VERSION "HNNBNNNYNNNNNNNNNNNNNNNNNNNNNNNNNNNNNNNNNN/4/%%%/4/'%**4NNN///"

NS_ :

BS_ :

BU_:  Airbag BAP_Tester ICAS1_Gateway ICAS1_KommunikationsServer LE1 LE2 Motor_BEV Schaltbetaetigung

BO_ 333 ACC_18: 32 ICAS1_Gateway
 SG_ ACC_18_CRC  : 0|8@1+ (1.000000,0.000000) [0.000000|255.000000] "" Motor_BEV
 SG_ ACC_18_BZ  : 8|4@1+ (1.000000,0.000000) [0.000000|15.000000] "" Motor_BEV
 SG_ ACC_limitierte_Anfahrdyn  : 12|1@1+ (1.000000,0.000000) [0.000000|1.000000] "" Motor_BEV
 SG_ ACC_nachtr_Stopp_Anf  : 13|1@1+ (1.000000,0.000000) [0.000000|1.000000] "" Vector__XXX
 SG_ ACC_DynErhoehung  : 14|1@1+ (1.000000,0.000000) [0.000000|1.000000] "" Motor_BEV
 SG_ ACC_Freilaufstrategie_TSK  : 15|1@1+ (1.000000,0.000000) [0.000000|1.000000] "" Motor_BEV
 SG_ ACC_zul_Regelabw_unten  : 16|6@1+ (0.024000,0.000000) [0.000000|1.512000] "Unit_MeterPerSeconSquar" Motor_BEV
 SG_ ACC_StartStopp_Info  : 22|2@1+ (1.000000,0.000000) [0.000000|3.000000] "" Vector__XXX
 SG_ ACC_Sollbeschleunigung_02  : 24|11@1+ (0.005000,-7.220000) [-7.220000|3.005000] "Unit_MeterPerSeconSquar" Motor_BEV
 SG_ ACC_zul_Regelabw_oben  : 35|5@1+ (0.062500,0.000000) [0.000000|1.937500] "Unit_MeterPerSeconSquar" Motor_BEV
 SG_ ACC_neg_Sollbeschl_Grad_02  : 40|8@1+ (0.050000,0.000000) [0.000000|12.750000] "Unit_MeterPerCubicSecon" Motor_BEV
 SG_ ACC_pos_Sollbeschl_Grad_02  : 48|8@1+ (0.050000,0.000000) [0.000000|12.750000] "Unit_MeterPerCubicSecon" Motor_BEV
 SG_ ACC_Anfahren  : 56|1@1+ (1.000000,0.000000) [0.000000|1.000000] "" Motor_BEV
 SG_ ACC_Anhalten  : 57|1@1+ (1.000000,0.000000) [0.000000|1.000000] "" Motor_BEV
 SG_ ACC_Typ  : 58|2@1+ (1.000000,0.000000) [0.000000|3.000000] "" Motor_BEV
 SG_ ACC_Status_ACC  : 60|3@1+ (1.000000,0.000000) [0.000000|7.000000] "" Motor_BEV
 SG_ ACC_Minimale_Bremsung  : 63|1@1+ (1.000000,0.000000) [0.000000|1.000000] "" Motor_BEV
 SG_ ACC_Anhalteweg  : 64|11@1+ (0.010000,0.000000) [0.000000|20.450000] "Unit_Meter" Vector__XXX
 SG_ ACC_Boost  : 75|1@1+ (1.000000,0.000000) [0.000000|1.000000] "" Vector__XXX
 SG_ ACC_Freilauf_Anf  : 76|1@1+ (1.000000,0.000000) [0.000000|1.000000] "" Vector__XXX
 SG_ ACC_Anforderung_HMS  : 77|3@1+ (1.000000,0.000000) [0.000000|7.000000] "" Vector__XXX
 SG_ ACC_Folgebeschl  : 80|8@1+ (0.030000,-4.600000) [-4.600000|2.990000] "Unit_MeterPerSeconSquar" Motor_BEV
 SG_ ACC_Freilauf_Info  : 88|2@1+ (1.000000,0.000000) [0.000000|3.000000] "" Motor_BEV
 SG_ ACC_Tempolimitassistent_Ein  : 90|1@1+ (1.000000,0.000000) [0.000000|1.000000] "" Vector__XXX
 SG_ ACC_FoD_Status  : 91|2@1+ (1.000000,0.000000) [0.000000|3.000000] "" Motor_BEV
 SG_ vESC_Verz_Anf  : 232|4@1+ (0.500000,0.000000) [0.000000|3.500000] "Unit_MeterPerSeconSquar" Vector__XXX
 SG_ RDR_v_ueber_Grund  : 236|12@1+ (0.100000,0.000000) [0.000000|409.000000] "Unit_KiloMeterPerHour" Vector__XXX
 SG_ RDR_v_ueber_Grund_Genauigkeit  : 248|6@1+ (0.100000,0.000000) [0.000000|6.000000] "Unit_KiloMeterPerHour" Vector__XXX
 SG_ RDR_v_ueber_Grund_Fahrtrichtung  : 254|2@1+ (1.000000,0.000000) [0.000000|3.000000] "" Vector__XXX

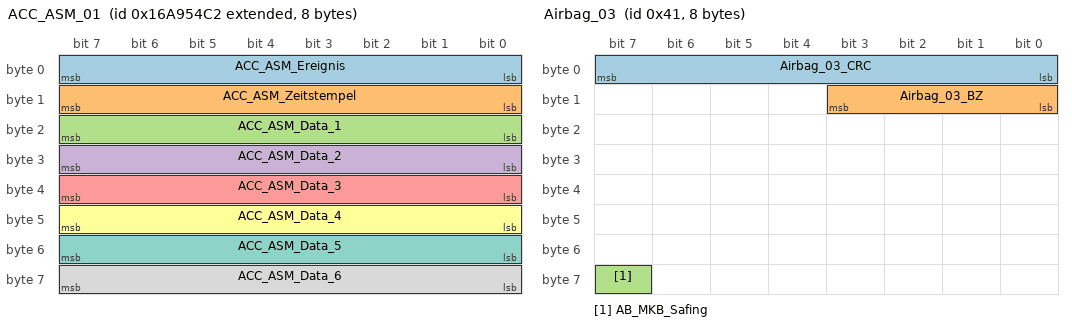
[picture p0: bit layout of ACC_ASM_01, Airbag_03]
BO_ 2527679682 ACC_ASM_01: 8 ICAS1_Gateway
 SG_ ACC_ASM_Ereignis  : 0|8@1+ (1.000000,0.000000) [1.000000|254.000000] "" Airbag
 SG_ ACC_ASM_Zeitstempel  : 8|8@1+ (0.080000,0.000000) [0.000000|20.320000] "Unit_Secon" Airbag
 SG_ ACC_ASM_Data_1  : 16|8@1+ (1.000000,0.000000) [0.000000|255.000000] "" Airbag
 SG_ ACC_ASM_Data_2  : 24|8@1+ (1.000000,0.000000) [0.000000|255.000000] "" Airbag
 SG_ ACC_ASM_Data_3  : 32|8@1+ (1.000000,0.000000) [0.000000|255.000000] "" Airbag
 SG_ ACC_ASM_Data_4  : 40|8@1+ (1.000000,0.000000) [0.000000|255.000000] "" Airbag
 SG_ ACC_ASM_Data_5  : 48|8@1+ (1.000000,0.000000) [0.000000|255.000000] "" Airbag
 SG_ ACC_ASM_Data_6  : 56|8@1+ (1.000000,0.000000) [0.000000|255.000000] "" Airbag

BO_ 64 Airbag_01: 8 Airbag
 SG_ Airbag_01_CRC  : 0|8@1+ (1.000000,0.000000) [0.000000|255.000000] "" ICAS1_Gateway LE1 LE2 Motor_BEV
 SG_ Airbag_01_BZ  : 8|4@1+ (1.000000,0.000000) [0.000000|15.000000] "" ICAS1_Gateway LE1 LE2 Motor_BEV
 SG_ AB_RGS_Anst  : 12|4@1+ (1.000000,0.000000) [0.000000|15.000000] "" ICAS1_Gateway ICAS1_KommunikationsServer
 SG_ AB_Front_Crash  : 16|1@1+ (1.000000,0.000000) [0.000000|1.000000] "" ICAS1_Gateway
 SG_ AB_Heck_Crash  : 17|1@1+ (1.000000,0.000000) [0.000000|1.000000] "" ICAS1_Gateway
 SG_ AB_SF_Crash  : 18|1@1+ (1.000000,0.000000) [0.000000|1.000000] "" ICAS1_Gateway
 SG_ AB_SB_Crash  : 19|1@1+ (1.000000,0.000000) [0.000000|1.000000] "" ICAS1_Gateway
 SG_ AB_Rollover_Crash  : 20|1@1+ (1.000000,0.000000) [0.000000|1.000000] "" ICAS1_Gateway
 SG_ AB_Crash_Int  : 21|3@1+ (1.000000,0.000000) [0.000000|7.000000] "" ICAS1_Gateway ICAS1_KommunikationsServer Motor_BEV
 SG_ AB_Lampe  : 24|1@1+ (1.000000,0.000000) [0.000000|1.000000] "" ICAS1_Gateway ICAS1_KommunikationsServer
 SG_ AB_Deaktiviert  : 25|1@1+ (1.000000,0.000000) [0.000000|1.000000] "" ICAS1_Gateway
 SG_ AB_VB_deaktiviert  : 26|1@1+ (1.000000,0.000000) [0.000000|1.000000] "" ICAS1_Gateway
 SG_ AB_Systemfehler  : 27|1@1+ (1.000000,0.000000) [0.000000|1.000000] "" ICAS1_Gateway ICAS1_KommunikationsServer
 SG_ AB_Diagnose  : 28|1@1+ (1.000000,0.000000) [0.000000|1.000000] "" ICAS1_Gateway
 SG_ AB_Stellgliedtest  : 29|1@1+ (1.000000,0.000000) [0.000000|1.000000] "" ICAS1_Gateway
 SG_ AB_Erh_Auf_VB  : 30|2@1+ (1.000000,0.000000) [0.000000|3.000000] "" ICAS1_Gateway
 SG_ AB_Gurtwarn_VF  : 32|1@1+ (1.000000,0.000000) [0.000000|1.000000] "" ICAS1_Gateway ICAS1_KommunikationsServer
 SG_ AB_Gurtwarn_VB  : 33|1@1+ (1.000000,0.000000) [0.000000|1.000000] "" ICAS1_Gateway ICAS1_KommunikationsServer
 SG_ AB_Anzeige_Fussg  : 34|2@1+ (1.000000,0.000000) [0.000000|3.000000] "" ICAS1_Gateway
 SG_ AB_Texte_AKS  : 36|2@1+ (1.000000,0.000000) [0.000000|3.000000] "" ICAS1_Gateway
 SG_ AB_PAO_Leuchte_Anf  : 38|1@1+ (1.000000,0.000000) [0.000000|1.000000] "" ICAS1_Gateway
 SG_ AB_MKB_gueltig  : 39|1@1+ (1.000000,0.000000) [0.000000|1.000000] "" ICAS1_Gateway
 SG_ AB_MKB_Anforderung  : 40|1@1+ (1.000000,0.000000) [0.000000|1.000000] "" ICAS1_Gateway
 SG_ AB_Versorgungsspannung  : 41|1@1+ (1.000000,0.000000) [0.000000|1.000000] "" ICAS1_Gateway
 SG_ AB_Deaktivierung_HV  : 42|3@1+ (1.000000,0.000000) [0.000000|7.000000] "" ICAS1_Gateway ICAS1_KommunikationsServer LE1 LE2 Motor_BEV
 SG_ AB_EDR_Trigger  : 45|2@1+ (1.000000,0.000000) [0.000000|3.000000] "" ICAS1_Gateway
 SG_ AB_Belegung_VF  : 47|2@1+ (1.000000,0.000000) [0.000000|3.000000] "" ICAS1_Gateway
 SG_ AB_Gurtschloss_FA_ext  : 49|3@1+ (1.000000,0.000000) [0.000000|7.000000] "" ICAS1_Gateway
 SG_ AB_Belegung_VF_ext  : 52|3@1+ (1.000000,0.000000) [0.000000|7.000000] "" ICAS1_Gateway
 SG_ ASM_Masterzeit  : 56|8@1+ (0.080000,0.000000) [0.000000|20.320000] "Unit_Secon" ICAS1_Gateway

BO_ 1312 Airbag_02: 8 Airbag
 SG_ Airbag_02_CRC  : 0|8@1+ (1.000000,0.000000) [0.000000|255.000000] "" ICAS1_Gateway Motor_BEV
 SG_ Airbag_02_BZ  : 8|4@1+ (1.000000,0.000000) [0.000000|15.000000] "" ICAS1_Gateway Motor_BEV
 SG_ LoGeWa_Event_Kombiwarnung  : 12|4@1+ (1.000000,0.000000) [0.000000|15.000000] "" ICAS1_Gateway
 SG_ AB_Anforderung_eCall  : 16|1@1+ (1.000000,0.000000) [0.000000|1.000000] "" ICAS1_Gateway
 SG_ AB_Anprall_Seite_Beifahrer  : 17|1@1+ (1.000000,0.000000) [0.000000|1.000000] "" ICAS1_Gateway ICAS1_KommunikationsServer
 SG_ AB_Anprall_Rollover  : 18|1@1+ (1.000000,0.000000) [0.000000|1.000000] "" ICAS1_Gateway ICAS1_KommunikationsServer
 SG_ AB_Anprall_FGS  : 19|1@1+ (1.000000,0.000000) [0.000000|1.000000] "" ICAS1_Gateway ICAS1_KommunikationsServer
 SG_ AB_Anprall_Front_Beifahrer  : 20|1@1+ (1.000000,0.000000) [0.000000|1.000000] "" ICAS1_Gateway ICAS1_KommunikationsServer
 SG_ AB_Anprall_Front_Fahrer  : 21|1@1+ (1.000000,0.000000) [0.000000|1.000000] "" ICAS1_Gateway ICAS1_KommunikationsServer
 SG_ AB_Anprall_Heck_Beifahrer  : 22|1@1+ (1.000000,0.000000) [0.000000|1.000000] "" ICAS1_Gateway ICAS1_KommunikationsServer
 SG_ AB_Anprall_Heck_Fahrer  : 23|1@1+ (1.000000,0.000000) [0.000000|1.000000] "" ICAS1_Gateway ICAS1_KommunikationsServer
 SG_ AB_Wickelklappung_Reihe2_MI  : 24|2@1+ (1.000000,0.000000) [0.000000|3.000000] "" ICAS1_Gateway
 SG_ AB_Belegung_VB  : 26|2@1+ (1.000000,0.000000) [0.000000|3.000000] "" ICAS1_Gateway
 SG_ AB_Abschaltanf_SIH_BF  : 28|1@1+ (1.000000,0.000000) [0.000000|1.000000] "" ICAS1_Gateway
 SG_ AB_Anprall_Seite_Fahrer  : 29|1@1+ (1.000000,0.000000) [0.000000|1.000000] "" ICAS1_Gateway ICAS1_KommunikationsServer
 SG_ SC_PAO_Schriftzug_Anf  : 30|2@1+ (1.000000,0.000000) [0.000000|3.000000] "" ICAS1_Gateway
 SG_ SC_PAO_ON_Anf  : 32|2@1+ (1.000000,0.000000) [0.000000|3.000000] "" ICAS1_Gateway
 SG_ SC_PAO_OFF_Anf  : 34|2@1+ (1.000000,0.000000) [0.000000|3.000000] "" ICAS1_Gateway
 SG_ AB_Crashschwere  : 36|3@1+ (1.000000,0.000000) [0.000000|7.000000] "" ICAS1_Gateway ICAS1_KommunikationsServer
 SG_ AB_Anforderung_USM  : 39|1@1+ (1.000000,0.000000) [0.000000|1.000000] "" ICAS1_Gateway
 SG_ AB_Gurtschloss_FA  : 40|2@1+ (1.000000,0.000000) [0.000000|3.000000] "" ICAS1_Gateway ICAS1_KommunikationsServer Motor_BEV
 SG_ AB_Gurtschloss_BF  : 42|2@1+ (1.000000,0.000000) [0.000000|3.000000] "" ICAS1_Gateway ICAS1_KommunikationsServer
 SG_ AB_Gurtschloss_Reihe2_FA  : 44|2@1+ (1.000000,0.000000) [0.000000|3.000000] "" ICAS1_Gateway ICAS1_KommunikationsServer
 SG_ AB_Gurtschloss_Reihe2_MI  : 46|2@1+ (1.000000,0.000000) [0.000000|3.000000] "" ICAS1_Gateway ICAS1_KommunikationsServer
 SG_ AB_Gurtschloss_Reihe2_BF  : 48|2@1+ (1.000000,0.000000) [0.000000|3.000000] "" ICAS1_Gateway ICAS1_KommunikationsServer
 SG_ AB_Gurtschloss_Reihe3_FA  : 50|2@1+ (1.000000,0.000000) [0.000000|3.000000] "" ICAS1_Gateway ICAS1_KommunikationsServer
 SG_ AB_Gurtschloss_Reihe3_MI  : 52|2@1+ (1.000000,0.000000) [0.000000|3.000000] "" ICAS1_Gateway ICAS1_KommunikationsServer
 SG_ AB_Gurtschloss_Reihe3_BF  : 54|2@1+ (1.000000,0.000000) [0.000000|3.000000] "" ICAS1_Gateway ICAS1_KommunikationsServer
 SG_ AB_Sitzpos_Sens_FA  : 56|2@1+ (1.000000,0.000000) [0.000000|3.000000] "" ICAS1_Gateway
 SG_ AB_Sitzpos_Sens_BF  : 58|2@1+ (1.000000,0.000000) [0.000000|3.000000] "" ICAS1_Gateway
 SG_ AB_Wickelklappung_Reihe2_BF  : 60|2@1+ (1.000000,0.000000) [0.000000|3.000000] "" ICAS1_Gateway
 SG_ AB_Wickelklappung_Reihe2_FA  : 62|2@1+ (1.000000,0.000000) [0.000000|3.000000] "" ICAS1_Gateway

BO_ 65 Airbag_03: 8 Airbag
 SG_ Airbag_03_CRC  : 0|8@1+ (1.000000,0.000000) [0.000000|255.000000] "" ICAS1_Gateway
 SG_ Airbag_03_BZ  : 8|4@1+ (1.000000,0.000000) [0.000000|15.000000] "" ICAS1_Gateway
 SG_ AB_MKB_Safing  : 63|1@1+ (1.000000,0.000000) [0.000000|1.000000] "" ICAS1_Gateway

BO_ 1349 Airbag_04: 8 Airbag
 SG_ AB_Gurtwarn_Reihe4_FA  : 14|2@1+ (1.000000,0.000000) [0.000000|3.000000] "" ICAS1_Gateway ICAS1_KommunikationsServer
 SG_ AB_Gurtwarn_Reihe4_BF  : 16|2@1+ (1.000000,0.000000) [0.000000|3.000000] "" ICAS1_Gateway ICAS1_KommunikationsServer
 SG_ AB_Gurtwarn_Reihe4_MI  : 18|2@1+ (1.000000,0.000000) [0.000000|3.000000] "" ICAS1_Gateway ICAS1_KommunikationsServer
 SG_ AB_Gurtwarn_Reihe2_FA  : 20|2@1+ (1.000000,0.000000) [0.000000|3.000000] "" ICAS1_Gateway ICAS1_KommunikationsServer
 SG_ AB_Gurtwarn_Reihe2_BF  : 22|2@1+ (1.000000,0.000000) [0.000000|3.000000] "" ICAS1_Gateway ICAS1_KommunikationsServer
 SG_ AbstWarn_MV_FAS_Fkt_Status  : 24|2@1+ (1.000000,0.000000) [0.000000|3.000000] "" ICAS1_Gateway
 SG_ WarnBrems_Charisma_Status  : 26|2@1+ (1.000000,0.000000) [0.000000|3.000000] "" ICAS1_Gateway
 SG_ WarnBrems_Charisma_FahrPr  : 28|4@1+ (1.000000,0.000000) [0.000000|15.000000] "" ICAS1_Gateway
 SG_ AB_Gurtwarn_Reihe2_MI  : 32|2@1+ (1.000000,0.000000) [0.000000|3.000000] "" ICAS1_Gateway ICAS1_KommunikationsServer
 SG_ AB_Gurtwarn_Reihe3_FA  : 34|2@1+ (1.000000,0.000000) [0.000000|3.000000] "" ICAS1_Gateway ICAS1_KommunikationsServer
 SG_ AB_Gurtwarn_Reihe3_MI  : 36|2@1+ (1.000000,0.000000) [0.000000|3.000000] "" ICAS1_Gateway ICAS1_KommunikationsServer
 SG_ AB_Gurtwarn_Reihe3_BF  : 38|2@1+ (1.000000,0.000000) [0.000000|3.000000] "" ICAS1_Gateway ICAS1_KommunikationsServer
 SG_ LGI_FAS_Fkt_Status  : 40|2@1+ (1.000000,0.000000) [0.000000|3.000000] "" ICAS1_Gateway
 SG_ PreCrash_FAS_Fkt_Status  : 42|3@1+ (1.000000,0.000000) [0.000000|7.000000] "" ICAS1_Gateway
 SG_ AB_SBR_hinten_verbau  : 48|2@1+ (1.000000,0.000000) [0.000000|3.000000] "" ICAS1_Gateway ICAS1_KommunikationsServer
 SG_ AWV_Einstellung_System_ASG  : 51|1@1+ (1.000000,0.000000) [0.000000|1.000000] "" ICAS1_Gateway
 SG_ AWV_Einstellung_Warnung_ASG  : 52|3@1+ (1.000000,0.000000) [0.000000|7.000000] "" ICAS1_Gateway
 SG_ SC_PreSense_Modus_Warnung_NV  : 55|3@1+ (1.000000,0.000000) [0.000000|7.000000] "" ICAS1_Gateway
 SG_ SC_PreSense_Modus_Warnung_MV  : 58|3@1+ (1.000000,0.000000) [0.000000|7.000000] "" ICAS1_Gateway
 SG_ SC_PreSense_Modus_System_MV  : 61|1@1+ (1.000000,0.000000) [0.000000|1.000000] "" ICAS1_Gateway
 SG_ SC_PreSense_Modus_System_NV  : 62|1@1+ (1.000000,0.000000) [0.000000|1.000000] "" ICAS1_Gateway
 SG_ SC_PreSense_Modus_System_KAS  : 63|1@1+ (1.000000,0.000000) [0.000000|1.000000] "" ICAS1_Gateway

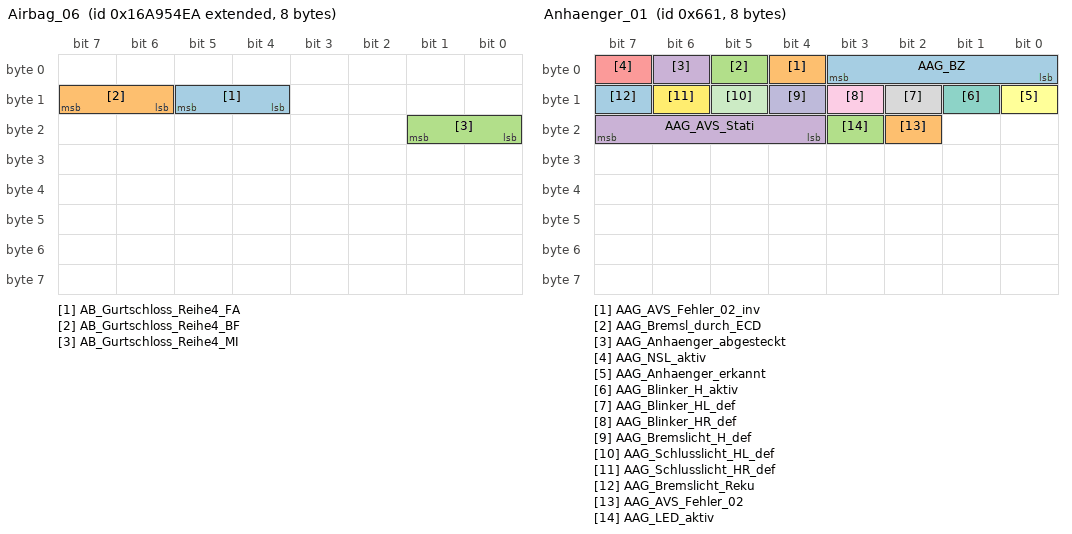
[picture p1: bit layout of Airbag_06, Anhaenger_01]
BO_ 2527679722 Airbag_06: 8 Airbag
 SG_ AB_Gurtschloss_Reihe4_FA  : 12|2@1+ (1.000000,0.000000) [0.000000|3.000000] "" ICAS1_Gateway ICAS1_KommunikationsServer
 SG_ AB_Gurtschloss_Reihe4_BF  : 14|2@1+ (1.000000,0.000000) [0.000000|3.000000] "" ICAS1_Gateway ICAS1_KommunikationsServer
 SG_ AB_Gurtschloss_Reihe4_MI  : 16|2@1+ (1.000000,0.000000) [0.000000|3.000000] "" ICAS1_Gateway ICAS1_KommunikationsServer

BO_ 1633 Anhaenger_01: 8 ICAS1_Gateway
 SG_ AAG_BZ  : 0|4@1+ (1.000000,0.000000) [0.000000|15.000000] "" Vector__XXX
 SG_ AAG_AVS_Fehler_02_inv  : 4|1@1+ (1.000000,0.000000) [0.000000|1.000000] "" Vector__XXX
 SG_ AAG_Bremsl_durch_ECD  : 5|1@1+ (1.000000,0.000000) [0.000000|1.000000] "" Motor_BEV
 SG_ AAG_Anhaenger_abgesteckt  : 6|1@1+ (1.000000,0.000000) [0.000000|1.000000] "" Motor_BEV
 SG_ AAG_NSL_aktiv  : 7|1@1+ (1.000000,0.000000) [0.000000|1.000000] "" Vector__XXX
 SG_ AAG_Anhaenger_erkannt  : 8|1@1+ (1.000000,0.000000) [0.000000|1.000000] "" Motor_BEV
 SG_ AAG_Blinker_H_aktiv  : 9|1@1+ (1.000000,0.000000) [0.000000|1.000000] "" Vector__XXX
 SG_ AAG_Blinker_HL_def  : 10|1@1+ (1.000000,0.000000) [0.000000|1.000000] "" Vector__XXX
 SG_ AAG_Blinker_HR_def  : 11|1@1+ (1.000000,0.000000) [0.000000|1.000000] "" Vector__XXX
 SG_ AAG_Bremslicht_H_def  : 12|1@1+ (1.000000,0.000000) [0.000000|1.000000] "" Motor_BEV
 SG_ AAG_Schlusslicht_HL_def  : 13|1@1+ (1.000000,0.000000) [0.000000|1.000000] "" Vector__XXX
 SG_ AAG_Schlusslicht_HR_def  : 14|1@1+ (1.000000,0.000000) [0.000000|1.000000] "" Vector__XXX
 SG_ AAG_Bremslicht_Reku  : 15|1@1+ (1.000000,0.000000) [0.000000|1.000000] "" Vector__XXX
 SG_ AAG_AVS_Fehler_02  : 18|1@1+ (1.000000,0.000000) [0.000000|1.000000] "" Vector__XXX
 SG_ AAG_LED_aktiv  : 19|1@1+ (1.000000,0.000000) [0.000000|1.000000] "" Vector__XXX
 SG_ AAG_AVS_Stati  : 20|4@1+ (1.000000,0.000000) [0.000000|15.000000] "" Vector__XXX

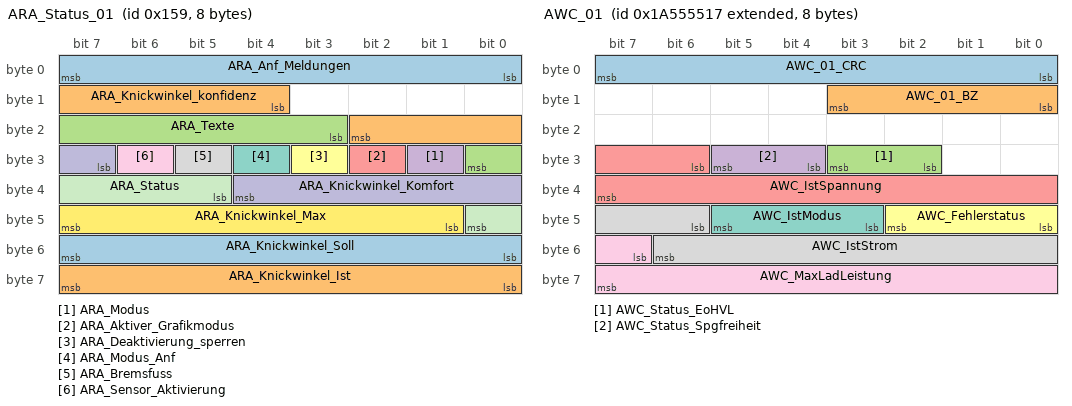
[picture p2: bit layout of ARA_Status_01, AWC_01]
BO_ 345 ARA_Status_01: 8 ICAS1_Gateway
 SG_ ARA_Anf_Meldungen  : 0|8@1+ (1.000000,0.000000) [0.000000|255.000000] "" Vector__XXX
 SG_ ARA_Knickwinkel_konfidenz  : 12|7@1+ (1.000000,0.000000) [0.000000|120.000000] "Unit_DegreOfArc" Vector__XXX
 SG_ ARA_Texte  : 19|6@1+ (1.000000,0.000000) [0.000000|63.000000] "" Vector__XXX
 SG_ ARA_Modus  : 25|1@1+ (1.000000,0.000000) [0.000000|1.000000] "" Vector__XXX
 SG_ ARA_Aktiver_Grafikmodus  : 26|1@1+ (1.000000,0.000000) [0.000000|1.000000] "" Vector__XXX
 SG_ ARA_Deaktivierung_sperren  : 27|1@1+ (1.000000,0.000000) [0.000000|1.000000] "" Vector__XXX
 SG_ ARA_Modus_Anf  : 28|1@1+ (1.000000,0.000000) [0.000000|1.000000] "" Vector__XXX
 SG_ ARA_Bremsfuss  : 29|1@1+ (1.000000,0.000000) [0.000000|1.000000] "" Vector__XXX
 SG_ ARA_Sensor_Aktivierung  : 30|1@1+ (1.000000,0.000000) [0.000000|1.000000] "" Vector__XXX
 SG_ ARA_Knickwinkel_Komfort  : 31|6@1+ (1.000000,0.000000) [0.000000|60.000000] "Unit_DegreOfArc" Vector__XXX
 SG_ ARA_Status  : 37|4@1+ (1.000000,0.000000) [0.000000|15.000000] "" Motor_BEV
 SG_ ARA_Knickwinkel_Max  : 41|7@1+ (1.000000,0.000000) [0.000000|120.000000] "Unit_DegreOfArc" Vector__XXX
 SG_ ARA_Knickwinkel_Soll  : 48|8@1+ (1.000000,-125.000000) [-125.000000|126.000000] "Unit_DegreOfArc" Vector__XXX
 SG_ ARA_Knickwinkel_Ist  : 56|8@1+ (1.000000,-125.000000) [-125.000000|126.000000] "Unit_DegreOfArc" Vector__XXX

BO_ 2589283607 AWC_01: 8 ICAS1_Gateway
 SG_ AWC_01_CRC  : 0|8@1+ (1.000000,0.000000) [0.000000|255.000000] "" Vector__XXX
 SG_ AWC_01_BZ  : 8|4@1+ (1.000000,0.000000) [0.000000|15.000000] "" Vector__XXX
 SG_ AWC_Status_EoHVL  : 26|2@1+ (1.000000,0.000000) [0.000000|3.000000] "" Motor_BEV
 SG_ AWC_Status_Spgfreiheit  : 28|2@1+ (1.000000,0.000000) [0.000000|3.000000] "" Vector__XXX
 SG_ AWC_IstSpannung  : 30|10@1+ (1.000000,0.000000) [0.000000|1021.000000] "Unit_Volt" Vector__XXX
 SG_ AWC_Fehlerstatus  : 40|3@1+ (1.000000,0.000000) [0.000000|7.000000] "" Vector__XXX
 SG_ AWC_IstModus  : 43|3@1+ (1.000000,0.000000) [0.000000|7.000000] "" Vector__XXX
 SG_ AWC_IstStrom  : 46|9@1+ (0.100000,0.000000) [0.000000|50.900000] "Unit_Amper" Vector__XXX
 SG_ AWC_MaxLadLeistung  : 55|9@1+ (25.000000,0.000000) [0.000000|12725.000000] "Unit_Watt" Vector__XXX

BO_ 219 AWV_03: 48 ICAS1_Gateway
 SG_ AWV_03_CRC  : 0|8@1+ (1.000000,0.000000) [0.000000|255.000000] "" Airbag
 SG_ AWV_03_BZ  : 8|4@1+ (1.000000,0.000000) [0.000000|15.000000] "" Airbag
 SG_ PCF_Freigabe  : 12|1@1+ (1.000000,0.000000) [0.000000|1.000000] "" Airbag
 SG_ SDF_PSF_Objektstatus  : 13|3@1+ (1.000000,0.000000) [0.000000|7.000000] "" Airbag
 SG_ SDF_PSF_CU_Status  : 16|1@1+ (1.000000,0.000000) [0.000000|1.000000] "" Airbag
 SG_ SDF_PSF_CW  : 17|7@1+ (1.000000,0.000000) [0.000000|100.000000] "" Airbag
 SG_ SDF_PSF_Fahrer_aktiv  : 24|1@1+ (1.000000,0.000000) [0.000000|1.000000] "" Airbag
 SG_ SDF_PSF_Guete  : 25|2@1+ (1.000000,0.000000) [0.000000|3.000000] "" Airbag
 SG_ SDF_PSF_Kollisionsueberdeckung  : 27|5@1+ (0.100000,0.000000) [0.100000|2.800000] "Unit_Meter" Airbag
 SG_ SDF_PSF_Time_To_Collision  : 32|8@1+ (0.010000,0.000000) [0.000000|2.500000] "Unit_Secon" Vector__XXX
 SG_ SDF_PSF_v_rel  : 40|8@1+ (0.400000,0.000000) [0.400000|101.200000] "Unit_MeterPerSecon" Airbag
 SG_ AWV_Eingriff_Sendeart  : 64|1@1+ (1.000000,0.000000) [0.000000|1.000000] "" Airbag
 SG_ AWV_Verz_Freigabe  : 65|1@1+ (1.000000,0.000000) [0.000000|1.000000] "" Airbag
 SG_ AWV_Verz_Anf  : 66|10@1+ (0.024000,-20.016000) [-20.016000|4.512000] "Unit_MeterPerSeconSquar" Airbag
 SG_ AWV_Anf_Prefill  : 76|1@1+ (1.000000,0.000000) [0.000000|1.000000] "" Airbag
 SG_ AWV_Ruckprofil  : 77|3@1+ (1.000000,0.000000) [0.000000|7.000000] "" Vector__XXX
 SG_ AWV_Time_to_collision  : 80|8@1+ (0.010000,0.000000) [0.000000|2.500000] "Unit_Secon" Airbag
 SG_ AWV_HBA_Param  : 88|2@1+ (1.000000,0.000000) [0.000000|3.000000] "" Vector__XXX
 SG_ AWV_Verz_Anf_ASIL  : 90|3@1+ (1.000000,0.000000) [0.000000|7.000000] "" Vector__XXX
 SG_ AWV_Time_to_brake  : 93|7@1+ (10.000000,0.000000) [0.000000|1240.000000] "Unit_MilliSecon" Vector__XXX
 SG_ AWV_Zielobjekttyp  : 100|4@1+ (1.000000,0.000000) [0.000000|15.000000] "" Airbag
 SG_ AWV_QFK_KruemmSoll  : 104|15@1+ (0.000007,0.000000) [0.000000|0.219539] "Unit_MeterInver" Vector__XXX
 SG_ AWV_QFK_KruemmSoll_VZ  : 119|1@1+ (1.000000,0.000000) [0.000000|1.000000] "" Vector__XXX
 SG_ AWV_QFK_Spuerb  : 120|8@1+ (0.400000,0.000000) [0.000000|100.000000] "Unit_PerCent" Vector__XXX
 SG_ AWV_QFK_AnfStat  : 128|4@1+ (1.000000,0.000000) [0.000000|15.000000] "" Airbag
 SG_ AWV_QFK_Signal1  : 132|10@1+ (1.000000,0.000000) [0.000000|1023.000000] "" Vector__XXX
 SG_ AWV_QFK_Art1  : 142|3@1+ (1.000000,0.000000) [0.000000|7.000000] "" Vector__XXX
 SG_ AWV_QFK_Art2  : 145|3@1+ (1.000000,0.000000) [0.000000|7.000000] "" Vector__XXX
 SG_ AWV_QFK_Signal2  : 148|10@1+ (1.000000,0.000000) [0.000000|1023.000000] "" Vector__XXX

BO_ 2536767264 BAP_Debug_Cmd: 8 BAP_Tester
 SG_ BAP_Debug_Cmd  : 0|16@1+ (1.000000,0.000000) [0.000000|65535.000000] "" Motor_BEV

BO_ 2536767280 BAP_Debug_Data: 8 Motor_BEV
 SG_ BAP_Debug_Data  : 0|64@1+ (1.000000,0.000000) [0.000000|18446744073709551616.000000] "" BAP_Tester

BO_ 2536717313 BAP_EfficiencyAssist_ASG_02: 8 ICAS1_Gateway
 SG_ BAP_EfficAssist_ASG_02_Header  : 0|64@1+ (1.000000,0.000000) [0.000000|18446744073709551616.000000] "" Motor_BEV

BO_ 2536717314 BAP_EfficiencyAssist_ASG_03: 8 ICAS1_Gateway
 SG_ BAP_EfficAssist_ASG_03_Header  : 0|8@1+ (1.000000,0.000000) [0.000000|255.000000] "" Motor_BEV

BO_ 2536717328 BAP_EfficiencyAssist_FSG_01: 8 Motor_BEV
 SG_ BAP_EfficAssist_FSG_01_Header  : 0|8@1+ (1.000000,0.000000) [0.000000|255.000000] "" ICAS1_Gateway

BO_ 2536709120 BAP_Hybrid_ASG_01: 8 ICAS1_Gateway
 SG_ BAP_Hybrid_ASG_01_Header  : 0|8@1+ (1.000000,0.000000) [0.000000|255.000000] "" Motor_BEV

BO_ 2536709136 BAP_Hybrid_FSG_01: 8 Motor_BEV
 SG_ BAP_Hybrid_FSG_01_Header  : 0|8@1+ (1.000000,0.000000) [0.000000|255.000000] "" ICAS1_Gateway

BO_ 869 BEM_05: 8 ICAS1_Gateway
 SG_ BEM_UBDM  : 0|8@1+ (0.050000,5.000000) [5.050000|17.700000] "Unit_Volt" Vector__XXX
 SG_ NVEM_Ladefreigabe  : 8|2@1+ (1.000000,0.000000) [0.000000|3.000000] "" Vector__XXX
 SG_ NVEM_FMAus_Info  : 10|2@1+ (1.000000,0.000000) [0.000000|3.000000] "" Vector__XXX
 SG_ NVEM_PTC_Sollstufe  : 12|2@1+ (1.000000,0.000000) [0.000000|3.000000] "" Vector__XXX
 SG_ NVEM_P_Generator_Status  : 15|1@1+ (1.000000,0.000000) [0.000000|1.000000] "" Vector__XXX
 SG_ BEM_P_Generator  : 16|8@1+ (50.000000,0.000000) [0.000000|12700.000000] "Unit_Watt" Vector__XXX
 SG_ BEM_n_LLA  : 24|2@1+ (1.000000,0.000000) [0.000000|3.000000] "" Vector__XXX
 SG_ BEM_01_Abschaltstufen  : 26|3@1+ (1.000000,0.000000) [0.000000|7.000000] "" Vector__XXX
 SG_ BEM_Anf_KL  : 29|1@1+ (1.000000,0.000000) [0.000000|1.000000] "" Vector__XXX
 SG_ BEM_StartStopp_Info  : 30|2@1+ (1.000000,0.000000) [0.000000|3.000000] "" Vector__XXX
 SG_ BEM_DFM  : 32|5@1+ (3.225000,0.025000) [0.025000|100.000000] "" Vector__XXX
 SG_ BEM_EMLIN_ungueltig  : 37|1@1+ (1.000000,0.000000) [0.000000|1.000000] "" Vector__XXX
 SG_ BEM_Batt_Ab  : 38|1@1+ (1.000000,0.000000) [0.000000|1.000000] "" Motor_BEV
 SG_ NVEM_FMAus_I_Verbrauch  : 39|5@1+ (5.000000,0.000000) [0.000000|145.000000] "Unit_Amper" Vector__XXX
 SG_ NVEM_Freilauf_Info  : 44|2@1+ (1.000000,0.000000) [0.000000|3.000000] "" Vector__XXX
 SG_ BEM_NV_NachladAnf  : 46|2@1+ (1.000000,0.000000) [0.000000|3.000000] "" Vector__XXX
 SG_ BEM_Segel_Info  : 48|2@1+ (1.000000,0.000000) [0.000000|3.000000] "" Vector__XXX
 SG_ BEM_HYB_DC_uSollLV  : 50|6@1+ (0.100000,10.600000) [10.600000|16.000000] "Unit_Volt" Vector__XXX
 SG_ BEM_HYB_DC_uMinLV  : 56|8@1+ (0.100000,0.000000) [0.000000|25.300000] "Unit_Volt" Vector__XXX

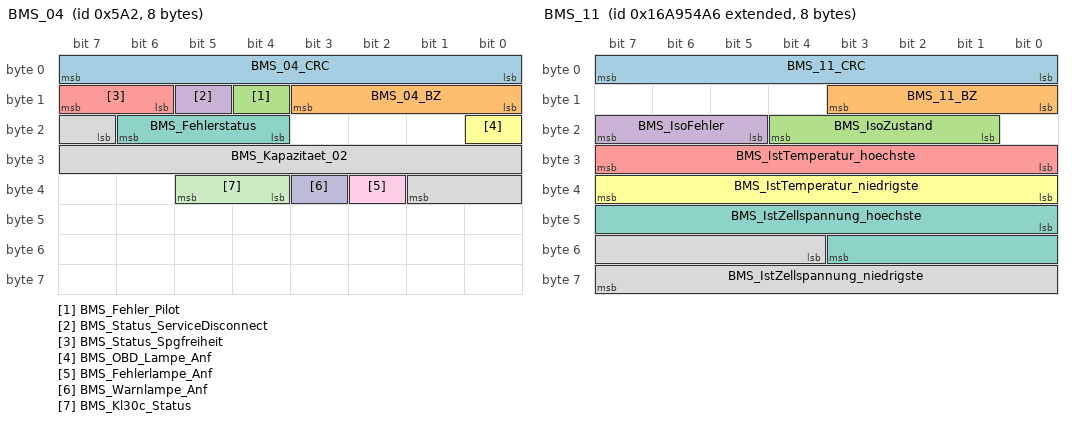
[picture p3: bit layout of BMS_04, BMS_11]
BO_ 1442 BMS_04: 8 ICAS1_Gateway
 SG_ BMS_04_CRC  : 0|8@1+ (1.000000,0.000000) [0.000000|255.000000] "" Vector__XXX
 SG_ BMS_04_BZ  : 8|4@1+ (1.000000,0.000000) [0.000000|15.000000] "" Vector__XXX
 SG_ BMS_Fehler_Pilot  : 12|1@1+ (1.000000,0.000000) [0.000000|1.000000] "" Vector__XXX
 SG_ BMS_Status_ServiceDisconnect  : 13|1@1+ (1.000000,0.000000) [0.000000|1.000000] "" Vector__XXX
 SG_ BMS_Status_Spgfreiheit  : 14|2@1+ (1.000000,0.000000) [0.000000|3.000000] "" Motor_BEV
 SG_ BMS_OBD_Lampe_Anf  : 16|1@1+ (1.000000,0.000000) [0.000000|1.000000] "" Motor_BEV
 SG_ BMS_Fehlerstatus  : 20|3@1+ (1.000000,0.000000) [0.000000|7.000000] "" Vector__XXX
 SG_ BMS_Kapazitaet_02  : 23|11@1+ (0.200000,0.000000) [0.000000|409.200000] "Unit_AmperHour" Vector__XXX
 SG_ BMS_Fehlerlampe_Anf  : 34|1@1+ (1.000000,0.000000) [0.000000|1.000000] "" Motor_BEV
 SG_ BMS_Warnlampe_Anf  : 35|1@1+ (1.000000,0.000000) [0.000000|1.000000] "" Motor_BEV
 SG_ BMS_Kl30c_Status  : 36|2@1+ (1.000000,0.000000) [0.000000|3.000000] "" Motor_BEV

BO_ 2527679654 BMS_11: 8 ICAS1_Gateway
 SG_ BMS_11_CRC  : 0|8@1+ (1.000000,0.000000) [0.000000|255.000000] "" Motor_BEV
 SG_ BMS_11_BZ  : 8|4@1+ (1.000000,0.000000) [0.000000|15.000000] "" Motor_BEV
 SG_ BMS_IsoZustand  : 17|4@1+ (1.000000,0.000000) [0.000000|15.000000] "" Motor_BEV
 SG_ BMS_IsoFehler  : 21|3@1+ (1.000000,0.000000) [0.000000|7.000000] "" Motor_BEV
 SG_ BMS_IstTemperatur_hoechste  : 24|8@1+ (0.500000,-40.000000) [-40.000000|86.000000] "Unit_DegreCelsi" Vector__XXX
 SG_ BMS_IstTemperatur_niedrigste  : 32|8@1+ (0.500000,-40.000000) [-40.000000|86.000000] "Unit_DegreCelsi" Vector__XXX
 SG_ BMS_IstZellspannung_hoechste  : 40|12@1+ (1.000000,1000.000000) [1000.000000|5091.000000] "Unit_MilliVolt" Vector__XXX
 SG_ BMS_IstZellspannung_niedrigste  : 52|12@1+ (1.000000,1000.000000) [1000.000000|5091.000000] "Unit_MilliVolt" Vector__XXX

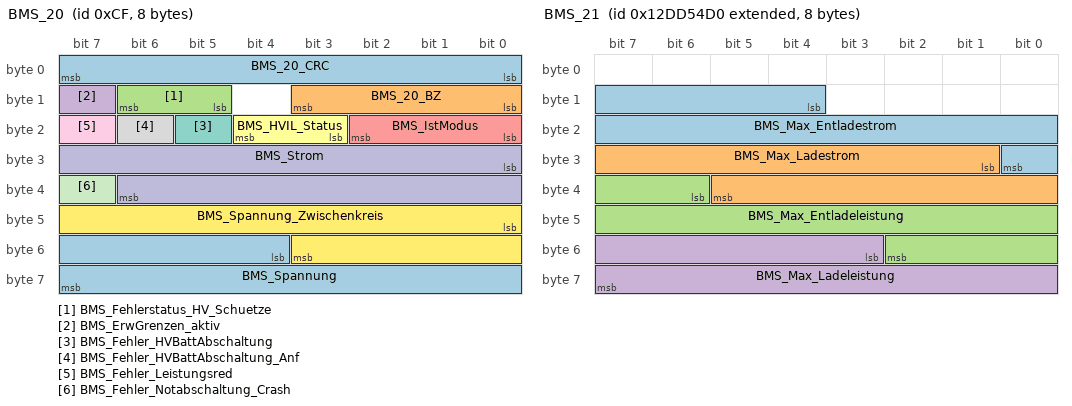
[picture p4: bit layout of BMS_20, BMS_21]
BO_ 207 BMS_20: 8 ICAS1_Gateway
 SG_ BMS_20_CRC  : 0|8@1+ (1.000000,0.000000) [0.000000|255.000000] "" Motor_BEV
 SG_ BMS_20_BZ  : 8|4@1+ (1.000000,0.000000) [0.000000|15.000000] "" Motor_BEV
 SG_ BMS_Fehlerstatus_HV_Schuetze  : 13|2@1+ (1.000000,0.000000) [0.000000|3.000000] "" Motor_BEV
 SG_ BMS_ErwGrenzen_aktiv  : 15|1@1+ (1.000000,0.000000) [0.000000|1.000000] "" Motor_BEV
 SG_ BMS_IstModus  : 16|3@1+ (1.000000,0.000000) [0.000000|7.000000] "" LE1 LE2 Motor_BEV
 SG_ BMS_HVIL_Status  : 19|2@1+ (1.000000,0.000000) [0.000000|3.000000] "" Motor_BEV
 SG_ BMS_Fehler_HVBattAbschaltung  : 21|1@1+ (1.000000,0.000000) [0.000000|1.000000] "" Motor_BEV
 SG_ BMS_Fehler_HVBattAbschaltung_Anf  : 22|1@1+ (1.000000,0.000000) [0.000000|1.000000] "" Motor_BEV
 SG_ BMS_Fehler_Leistungsred  : 23|1@1+ (1.000000,0.000000) [0.000000|1.000000] "" Motor_BEV
 SG_ BMS_Strom  : 24|15@1+ (0.100000,-1630.000000) [-1630.000000|1630.000000] "Unit_Amper" Motor_BEV
 SG_ BMS_Fehler_Notabschaltung_Crash  : 39|1@1+ (1.000000,0.000000) [0.000000|1.000000] "" Vector__XXX
 SG_ BMS_Spannung_Zwischenkreis  : 40|12@1+ (0.500000,-1000.000000) [-1000.000000|1000.000000] "Unit_Volt" Motor_BEV
 SG_ BMS_Spannung  : 52|12@1+ (0.250000,0.000000) [0.000000|1000.000000] "Unit_Volt" Motor_BEV

BO_ 2463978704 BMS_21: 8 ICAS1_Gateway
 SG_ BMS_Max_Entladestrom  : 12|13@1+ (0.200000,0.000000) [0.000000|1630.000000] "Unit_Amper" Motor_BEV
 SG_ BMS_Max_Ladestrom  : 25|13@1+ (0.200000,0.000000) [0.000000|1630.000000] "Unit_Amper" Motor_BEV
 SG_ BMS_Max_Entladeleistung  : 38|13@1+ (100.000000,0.000000) [0.000000|818000.000000] "Unit_Watt" Motor_BEV
 SG_ BMS_Max_Ladeleistung  : 51|13@1+ (100.000000,0.000000) [0.000000|818000.000000] "Unit_Watt" Motor_BEV

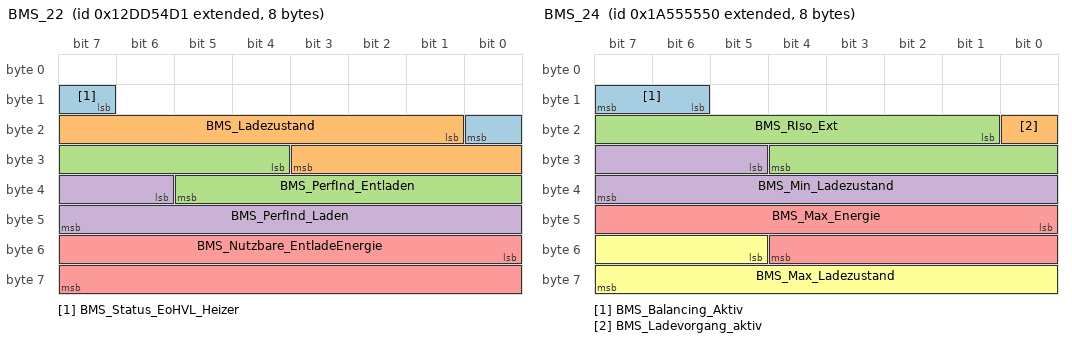
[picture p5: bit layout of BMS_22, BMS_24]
BO_ 2463978705 BMS_22: 8 ICAS1_Gateway
 SG_ BMS_Status_EoHVL_Heizer  : 15|2@1+ (1.000000,0.000000) [0.000000|3.000000] "" Motor_BEV
 SG_ BMS_Ladezustand  : 17|11@1+ (0.050000,0.000000) [0.000000|100.000000] "Unit_PerCent" Motor_BEV
 SG_ BMS_PerfInd_Entladen  : 28|10@1+ (0.200000,0.000000) [0.000000|200.000000] "Unit_PerCent" Motor_BEV
 SG_ BMS_PerfInd_Laden  : 38|10@1+ (0.200000,0.000000) [0.000000|200.000000] "Unit_PerCent" Motor_BEV
 SG_ BMS_Nutzbare_EntladeEnergie  : 48|16@1+ (5.000000,0.000000) [0.000000|327400.000000] "Unit_WattHour" Motor_BEV

BO_ 2589283664 BMS_24: 8 ICAS1_Gateway
 SG_ BMS_Balancing_Aktiv  : 14|2@1+ (1.000000,0.000000) [0.000000|3.000000] "" Vector__XXX
 SG_ BMS_Ladevorgang_aktiv  : 16|1@1+ (1.000000,0.000000) [0.000000|1.000000] "" Vector__XXX
 SG_ BMS_RIso_Ext  : 17|12@1+ (5.000000,0.000000) [0.000000|20465.000000] "Unit_KiloOhm" Motor_BEV
 SG_ BMS_Min_Ladezustand  : 29|11@1+ (0.050000,0.000000) [0.000000|100.000000] "Unit_PerCent" Motor_BEV
 SG_ BMS_Max_Energie  : 40|13@1+ (40.000000,0.000000) [0.000000|327400.000000] "Unit_WattHour" Motor_BEV
 SG_ BMS_Max_Ladezustand  : 53|11@1+ (0.050000,0.000000) [0.000000|100.000000] "Unit_PerCent" Motor_BEV

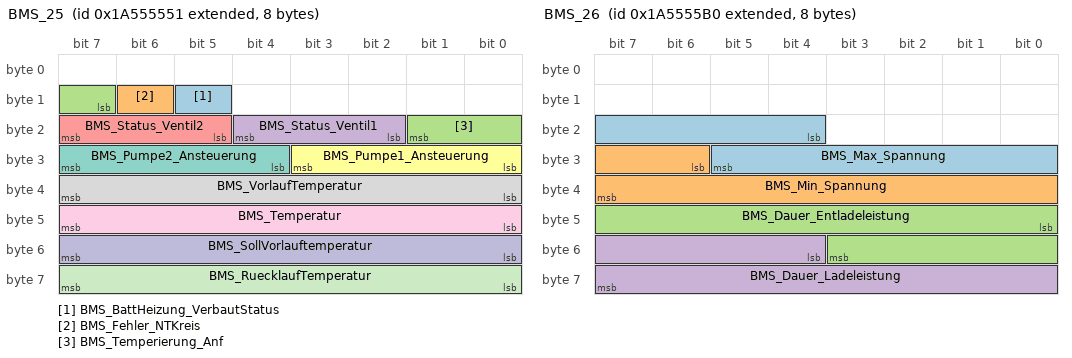
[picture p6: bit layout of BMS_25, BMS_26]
BO_ 2589283665 BMS_25: 8 ICAS1_Gateway
 SG_ BMS_BattHeizung_VerbautStatus  : 13|1@1+ (1.000000,0.000000) [0.000000|1.000000] "" Motor_BEV
 SG_ BMS_Fehler_NTKreis  : 14|1@1+ (1.000000,0.000000) [0.000000|1.000000] "" Vector__XXX
 SG_ BMS_Temperierung_Anf  : 15|3@1+ (1.000000,0.000000) [0.000000|7.000000] "" Motor_BEV
 SG_ BMS_Status_Ventil1  : 18|3@1+ (1.000000,0.000000) [0.000000|7.000000] "" Motor_BEV
 SG_ BMS_Status_Ventil2  : 21|3@1+ (1.000000,0.000000) [0.000000|7.000000] "" Motor_BEV
 SG_ BMS_Pumpe1_Ansteuerung  : 24|4@1+ (10.000000,0.000000) [0.000000|100.000000] "Unit_PerCent" Motor_BEV
 SG_ BMS_Pumpe2_Ansteuerung  : 28|4@1+ (10.000000,0.000000) [0.000000|100.000000] "Unit_PerCent" Motor_BEV
 SG_ BMS_VorlaufTemperatur  : 32|8@1+ (0.500000,-40.000000) [-40.000000|86.000000] "Unit_DegreCelsi" Motor_BEV
 SG_ BMS_Temperatur  : 40|8@1+ (0.500000,-40.000000) [-40.000000|86.500000] "Unit_DegreCelsi" Motor_BEV
 SG_ BMS_SollVorlauftemperatur  : 48|8@1+ (0.500000,-40.000000) [-40.000000|86.500000] "Unit_DegreCelsi" Motor_BEV
 SG_ BMS_RuecklaufTemperatur  : 56|8@1+ (0.500000,-40.000000) [-40.000000|86.000000] "Unit_DegreCelsi" Motor_BEV

BO_ 2589283760 BMS_26: 8 ICAS1_Gateway
 SG_ BMS_Max_Spannung  : 20|10@1+ (1.000000,0.000000) [0.000000|1000.000000] "Unit_Volt" Motor_BEV
 SG_ BMS_Min_Spannung  : 30|10@1+ (1.000000,0.000000) [0.000000|1000.000000] "Unit_Volt" Motor_BEV
 SG_ BMS_Dauer_Entladeleistung  : 40|12@1+ (200.000000,0.000000) [0.000000|818000.000000] "Unit_Watt" Motor_BEV
 SG_ BMS_Dauer_Ladeleistung  : 52|12@1+ (200.000000,0.000000) [0.000000|818000.000000] "Unit_Watt" Motor_BEV

BO_ 2463978646 Charisma_11: 24 ICAS1_Gateway
 SG_ CHA_Ziel_FahrPr_AGA  : 0|4@1+ (1.000000,0.000000) [0.000000|15.000000] "" Vector__XXX
 SG_ CHA_Ziel_FahrPr_ESP  : 4|4@1+ (1.000000,0.000000) [0.000000|15.000000] "" Motor_BEV
 SG_ CHA_Ziel_FahrPr_Freilauf  : 8|4@1+ (1.000000,0.000000) [0.000000|15.000000] "" Vector__XXX
 SG_ CHA_Fahrer_Umschaltung  : 14|1@1+ (1.000000,0.000000) [0.000000|1.000000] "" Motor_BEV
 SG_ CHA_Fahrer_Umschaltung_BMA  : 15|1@1+ (1.000000,0.000000) [0.000000|1.000000] "" Vector__XXX
 SG_ CHA_Ziel_FahrPr_MO  : 16|4@1+ (1.000000,0.000000) [0.000000|15.000000] "" Motor_BEV
 SG_ CHA_Ziel_FahrPr_GE  : 20|4@1+ (1.000000,0.000000) [0.000000|15.000000] "" Vector__XXX
 SG_ CHA_Ziel_FahrPr_ALR  : 24|4@1+ (1.000000,0.000000) [0.000000|15.000000] "" Motor_BEV
 SG_ CHA_Ziel_FahrPr_MO_BZS  : 28|4@1+ (1.000000,0.000000) [0.000000|15.000000] "" Vector__XXX
 SG_ CHA_Ziel_FahrPr_DR  : 32|4@1+ (1.000000,0.000000) [0.000000|15.000000] "" Vector__XXX
 SG_ CHA_Ziel_FahrPr_VAQ  : 36|4@1+ (1.000000,0.000000) [0.000000|15.000000] "" Vector__XXX
 SG_ CHA_Ziel_FahrPr_AFS  : 40|4@1+ (1.000000,0.000000) [0.000000|15.000000] "" Vector__XXX
 SG_ CHA_Ziel_FahrPr_PreCrash  : 44|4@1+ (1.000000,0.000000) [0.000000|15.000000] "" Airbag
 SG_ CHA_Ziel_FahrPr_EPS  : 48|4@1+ (1.000000,0.000000) [0.000000|15.000000] "" Vector__XXX
 SG_ CHA_Ziel_FahrPr_ACC  : 52|4@1+ (1.000000,0.000000) [0.000000|15.000000] "" Vector__XXX
 SG_ CHA_Ziel_FahrPr_SAK  : 56|4@1+ (1.000000,0.000000) [0.000000|15.000000] "" Vector__XXX
 SG_ CHA_Ziel_FahrPr_MO_StSt  : 60|4@1+ (1.000000,0.000000) [0.000000|15.000000] "" Vector__XXX
 SG_ CHA_Ziel_FahrPr_EBKV  : 64|4@1+ (1.000000,0.000000) [0.000000|15.000000] "" Vector__XXX
 SG_ CHA_Ziel_FahrPr_IL  : 68|4@1+ (1.000000,0.000000) [0.000000|15.000000] "" Vector__XXX
 SG_ CHA_Current_Mode  : 72|4@1+ (1.000000,0.000000) [0.000000|15.000000] "" Vector__XXX
 SG_ CHA_Ziel_FahrPr_QS  : 80|4@1+ (1.000000,0.000000) [0.000000|15.000000] "" Vector__XXX
 SG_ CHA_Ziel_FahrPr_SCU  : 84|4@1+ (1.000000,0.000000) [0.000000|15.000000] "" Vector__XXX
 SG_ CHA_Ziel_FahrPr_HAL  : 88|4@1+ (1.000000,0.000000) [0.000000|15.000000] "" Vector__XXX
 SG_ CHA_Ziel_FahrPr_NR  : 92|4@1+ (1.000000,0.000000) [0.000000|15.000000] "" Vector__XXX
 SG_ CHA_Ziel_FahrPr_AV  : 96|4@1+ (1.000000,0.000000) [0.000000|15.000000] "" Vector__XXX
 SG_ CHA_Ziel_FahrPr_MXB  : 100|4@1+ (1.000000,0.000000) [0.000000|15.000000] "" Vector__XXX
 SG_ CHA_Ziel_FahrPr_AFR  : 104|4@1+ (1.000000,0.000000) [0.000000|15.000000] "" Vector__XXX
 SG_ CHA_Ziel_FahrPr_HDC  : 108|4@1+ (1.000000,0.000000) [0.000000|15.000000] "" Vector__XXX
 SG_ CHA_Ziel_FahrPr_EAR  : 112|4@1+ (1.000000,0.000000) [0.000000|15.000000] "" Vector__XXX
 SG_ CHA_Ziel_FahrPr_AEB  : 116|4@1+ (1.000000,0.000000) [0.000000|15.000000] "" Vector__XXX
 SG_ CHA_Ziel_FahrPr_FCWO  : 120|4@1+ (1.000000,0.000000) [0.000000|15.000000] "" Vector__XXX
 SG_ CHA_Ziel_FahrPr_FCWP  : 124|4@1+ (1.000000,0.000000) [0.000000|15.000000] "" Vector__XXX
 SG_ CHA_Ziel_FahrPr_ToS_laengs  : 144|4@1+ (1.000000,0.000000) [0.000000|15.000000] "" Vector__XXX
 SG_ CHA_Ziel_FahrPr_ToS_quer  : 148|4@1+ (1.000000,0.000000) [0.000000|15.000000] "" Vector__XXX
 SG_ CHA_Ziel_FahrPr_mFDR  : 152|4@1+ (1.000000,0.000000) [0.000000|15.000000] "" Vector__XXX
 SG_ CHA_Ziel_FahrPr_Reku_ZwGas  : 156|4@1+ (1.000000,0.000000) [0.000000|15.000000] "" Vector__XXX
 SG_ CHA_Ziel_FahrPr_MO_Freilauf  : 160|4@1+ (1.000000,0.000000) [0.000000|15.000000] "" Vector__XXX
 SG_ CHA_Ziel_FahrPr_BMS  : 164|4@1+ (1.000000,0.000000) [0.000000|15.000000] "" Vector__XXX
 SG_ CHA_Current_Mode_BMA  : 168|4@1+ (1.000000,0.000000) [0.000000|15.000000] "" Vector__XXX
 SG_ CHA_Ziel_FahrPr_PDC  : 172|4@1+ (1.000000,0.000000) [0.000000|15.000000] "" Vector__XXX
 SG_ CHA_Ziel_FahrPr_HHC  : 176|4@1+ (1.000000,0.000000) [0.000000|15.000000] "" Vector__XXX
 SG_ CHA_Ziel_FahrPr_EDS  : 180|4@1+ (1.000000,0.000000) [0.000000|15.000000] "" Vector__XXX
 SG_ CHA_Ziel_FahrPr_PACC  : 184|4@1+ (1.000000,0.000000) [0.000000|15.000000] "" Vector__XXX
 SG_ CHA_Ziel_FahrPr_AGK  : 188|4@1+ (1.000000,0.000000) [0.000000|15.000000] "" Vector__XXX

CM_ "MEB_ACANFD_V10.04.03FGeneratedbyBusNet_NG_Produktiv9.9.3";
CM_ BU_ Airbag "AirbagMQB2020";
CM_ BU_ ICAS1_Gateway "ICAS1MEB
DFL-Kürzel: Gateway";
CM_ BU_ LE1 "LeistungselektronikMQB2020(BEVundPHEV)";
CM_ BU_ LE2 "Leistungselektronik2MQB2020(BEVundPHEV)";
CM_ BU_ Motor_BEV "Motor-SG(Antriebs-SG)MQB2020BEV";
CM_ BU_ Schaltbetaetigung "MonostabilerWählhebelMQB2020";
CM_ BO_ 1633 "abMQB7.2";
CM_ BO_ 2536717313 "BAPASGmessageEfficiencyAssist(PEA)<br>
Sender: Kombi
Receiver: MSG";
CM_ BO_ 2536717314 "BAPASGmessageEfficiencyAssist(PEA)<br>
Sender: Kombi
Receiver: MSG";
CM_ BO_ 2536717328 "BAPFSGmessageEfficiencyAssist(PEA)<br>
Sender: MSG<br>
Receiver: HU (MIB)";
CM_ BO_ 869 "abMQB";
CM_ BO_ 2463978646 "abMQBohneCHKundmitgeänderterSendeart";
CM_ SG_ 333 ACC_18_CRC "FürMLB:
Berechnung siehe Lastenheft 'Kommunikationsabsicherung für FlexRay und CAN'
Ab MQB und MLBevo:
Berechnung siehe Lastenheft 'End-to-End Kommunikationsabsicherung'

Endwerte siehe Begleitdokument 'S-PDU Kennungsfolgen'";
CM_ SG_ 333 ACC_18_BZ "4bitBotschaftszähler,wirdmitjederSendebotschaftinkrementiert";
CM_ SG_ 333 ACC_limitierte_Anfahrdyn "InfofürdenMotor,dassbeimACC-AnfahrenmitZielfahrzeugseitensACCeinelimitierteFahrpedalkennliniegefordertwird.";
CM_ SG_ 333 ACC_nachtr_Stopp_Anf "DiesesSignaldientdemMotoralsTrigger,dasseinnachträglicherMotorstoppeingeleitetwerdenkann,wennesdieBedingungendesStStKoordinatorsdieszulassen.";
CM_ SG_ 333 ACC_DynErhoehung "AnsteuerungeinererhöhtenDynamikimVerzögerungsfall(vorallembeimMotormomentenabbau)";
CM_ SG_ 333 ACC_Freilaufstrategie_TSK "DasSignaldefiniertimaktivenACC-Betrieb,obeinFreilaufdirektüberdasACCangefordertwirdodereinFreilaufüberdenTriebstrangkoordinator(TSK)angefordertwird,fallsdasACCdenFreilauffreigibt.";
CM_ SG_ 333 ACC_zul_Regelabw_unten "AnforderungandenTriebstrangkoordinator.ZulässigerBetragderAbweichungzwischenangeforderter'ACC_Sollbeschleunigung(_02)'undumzusetzenderSollbeschleunigungimTSK.ImTSKwird,abhängigvomArbeitspunktdieToleranzunddieSollbeschleunigungf";
CM_ SG_ 333 ACC_StartStopp_Info "Freigabebzw.StartanforderungfürStart/Stopp";
CM_ SG_ 333 ACC_Sollbeschleunigung_02 "AnforderungandenTriebstrangkoordinator,eine'ACC_Sollbeschleunigung'umzusetzen.";
CM_ SG_ 333 ACC_zul_Regelabw_oben "AnforderungandenTriebstrangkoordinator.ZulässigerBetragderAbweichungzwischenangeforderter'ACC_Sollbeschleunigung(_02)'undumzusetzenderSollbeschleunigungimTSK.ImTSKwird,abhängigvomArbeitspunktdieToleranzunddieSollbeschleunigungf";
CM_ SG_ 333 ACC_neg_Sollbeschl_Grad_02 "EmpfehlungandenTriebstrangkoordinator,mitwelchembetragsmäßigmaximalennegativenGradienteneineACC-Anforderung'ACC_Sollbeschleunigung_02'einzuregelnist.";
CM_ SG_ 333 ACC_pos_Sollbeschl_Grad_02 "EmpfehlungandenTriebstrangkoordinator,mitwelchembetragsmäßigmaximalenpositivenGradienteneineACC-Anforderung'ACC_Sollbeschleunigung_02'einzuregelnist.";
CM_ SG_ 333 ACC_Anfahren "AnforderungAnfahren";
CM_ SG_ 333 ACC_Anhalten "ImFalleeinesgesetztenBitswirdvomACCeinAnhaltenbisindenStandgewünscht.DasBitwirdvonACCnurunterhalbeinerappl.Geschwindigkeitsschwellegesetzt.NotwendigfürdieACCplus-Funktionalität.NichtfürAudiB8relevant,jedochimVorgriffa";
CM_ SG_ 333 ACC_Typ "MotorplausibilisiertseineeigeneKodierung";
CM_ SG_ 333 ACC_Status_ACC "'ACCOFF'bedeutetACC-Hauptschalterist'GerastetAus

'ACC Reversibler Fehler' bedeutet, daß das ACC aktuell einen
reversiblen Fehler im ACC-SG selbst oder in einem zum
ACC-System gehörenden SG erkennt.

'ACC irreversibler Fehler' bedeutet, daß ";
CM_ SG_ 333 ACC_Minimale_Bremsung "ImFalleeinesgesetztenBitswirdvomACCdemTSKangezeigt,dassessichimResume_Suspend_Modebefindet.IndiesemModedarfderTSKkeineECD-Bremsunganfordern,unabhängigvonder'ACC_Sollbeschleunigungsanforderung'.EineFahrzeugverzögerungdarfnu";
CM_ SG_ 333 ACC_Anhalteweg "VerbleibenderWegbiszumStillstand";
CM_ SG_ 333 ACC_Boost "AktivitätderBoost-FunktiondesACC";
CM_ SG_ 333 ACC_Freilauf_Anf "Freilauf-AnforderungdurchEnergo/ACC";
CM_ SG_ 333 ACC_Anforderung_HMS "BremsanforderungandenHaltemanager";
CM_ SG_ 333 ACC_Folgebeschl "SollbeschleunigungdesACC-Folgeregler";
CM_ SG_ 333 ACC_Freilauf_Info "Freilauf-FreigabedurchAktivenTeilnehmerFreilauf";
CM_ SG_ 333 ACC_Tempolimitassistent_Ein "StatusACC-Tempolimitassistent";
CM_ SG_ 333 ACC_FoD_Status "InformiertdenTSKundKombi,obdieACC-Funktionfreigeschaltetistodernicht.";
CM_ SG_ 333 vESC_Verz_Anf "DieFunktionvorausschauendesESCforderteineVerzögerungimVZM.";
CM_ SG_ 333 RDR_v_ueber_Grund "DasSignalV_ueber_GrundzeigtdieFahrzeuggeschwindigkeitüberGrundinX-Richtungan.
Das Signal wird ausschließlich durch Auswertung von Radarsignalen erzeugt.";
CM_ SG_ 333 RDR_v_ueber_Grund_Genauigkeit "DasSignalzeigtdieGenauigkeitdesGeschwindigkeitssignalsRDR_v_ueber_Grundim95%-Konfidenzintervallan.";
CM_ SG_ 333 RDR_v_ueber_Grund_Fahrtrichtung "DasSignalzeigtdieFahrtrichtungdesFahrzeugsan.
Das Signal wird ausschließlich durch Auswertung von Radarsignalen erzeugt.";
CM_ SG_ 2527679682 ACC_ASM_Ereignis "DiesesSignaldefiniert,welcheFunktionundwelcheArtvonAktivitätdasSendenderBotschaftandenAssistenzsystemmonitorASM(HostSG:SafetyComputer)veranlassthat.";
CM_ SG_ 2527679682 ACC_ASM_Zeitstempel "DiesesSignalermöglichtdiezeitlicheZuordnungdervonACCandenAssistenzsystemmonitorASM(HostSG:SafetyComputer)gesendetenStatusbotschaften.";
CM_ SG_ 2527679682 ACC_ASM_Data_1 "DiesesSignalwirdvonACC(LongRangeRadar)befülltundandenAssistenzsystemmonitorASM(HostSG:SafetyComputer)gesendet.";
CM_ SG_ 2527679682 ACC_ASM_Data_2 "DiesesSignalwirdvonACC(LongRangeRadar)befülltundandenAssistenzsystemmonitorASM(HostSG:SafetyComputer)gesendet.";
CM_ SG_ 2527679682 ACC_ASM_Data_3 "DiesesSignalwirdvonACC(LongRangeRadar)befülltundandenAssistenzsystemmonitorASM(HostSG:SafetyComputer)gesendet.";
CM_ SG_ 2527679682 ACC_ASM_Data_4 "DiesesSignalwirdvonACC(LongRangeRadar)befülltundandenAssistenzsystemmonitorASM(HostSG:SafetyComputer)gesendet.";
CM_ SG_ 2527679682 ACC_ASM_Data_5 "DiesesSignalwirdvonACC(LongRangeRadar)befülltundandenAssistenzsystemmonitorASM(HostSG:SafetyComputer)gesendet.";
CM_ SG_ 2527679682 ACC_ASM_Data_6 "DiesesSignalwirdvonACC(LongRangeRadar)befülltundandenAssistenzsystemmonitorASM(HostSG:SafetyComputer)gesendet.";
CM_ SG_ 64 Airbag_01_CRC "FürMLB:
'Berechnung siehe Lastenheft 'Kommunikationsabsicherung für FlexRay und CAN''

Ab MQB und MLBevo:
'Berechnung siehe Lastenheft 'End-to-End Kommunikationsabsicherung''

Endwerte siehe Begleitdokument 'S-PDU Kennungsfolgen'";
CM_ SG_ 64 AB_RGS_Anst "PreCrash-AnsteuerungreversiblerGurtstraffer(AktivierungundKraftniveau)

10xx = deaktiviert";
CM_ SG_ 64 AB_Front_Crash "BitwirdbeiÜberschreitungderGurtstraffer-,US-undRdW-Schwellegesetzt";
CM_ SG_ 64 AB_Heck_Crash "WirdfüralleneuanlaufendenProjekteumgesetzt:AB8.4,Audi8/VW8";
CM_ SG_ 64 AB_SF_Crash "Z.Zt.nurinVerbindungmitCrash-Intensität>=100b(Kraftstoffpumpenabschaltung)verwendet.";
CM_ SG_ 64 AB_SB_Crash "Z.Zt.nurinVerbindungmitCrash-Intensität>=100b(Kraftstoffpumpenabschaltung)verwendet.
";
CM_ SG_ 64 AB_Rollover_Crash "WirdimB6/B7CabrioundNewBeetleCabriobedient.";
CM_ SG_ 64 AB_Crash_Int "Crash_Intensität_1=fahrzeugabhängigeReaktionenimCrash
Crash_Intensität_2 = fahrzeugabhängige Reaktionen im Crash
Crash_Intensität_3 = fahrzeugabhängige Reaktionen im Crash

Die jeweiligen fahrzeugabhängigen Reaktionen im Crash sind in einem separ";
CM_ SG_ 64 AB_Lampe "SicherheitswarnlampeimKombiwirdvomAirbag-SGangesteuert;ZustandderLampewirdaufdemCAN-Busausgegeben(auchBlinkinformation).";
CM_ SG_ 64 AB_Deaktiviert "AirbagoderGurtstrafferwurdenperAnpassungdeaktiviert:AktualisierungerstnachSelbsttest";
CM_ SG_ 64 AB_VB_deaktiviert "AlsOptionvorgehalten,BeifahrerairbagwurdenperSchlüsselschalteroderInsassenerkennungdeaktiviert";
CM_ SG_ 64 AB_Systemfehler "SystemfehlerGgf.wirdWarnlampedauerndeingeschaltet.";
CM_ SG_ 64 AB_Diagnose "AirbaginDiagnose";
CM_ SG_ 64 AB_Stellgliedtest "Information,obAirbagimStellgliedtestist,umeineNotrufauflösungbeimStellgliedtestzuverhindern";
CM_ SG_ 64 AB_Erh_Auf_VB "DerFahrersollbeieinemStatuswechseldesBeifahrerairbags(ausgelöstdurchdieBeifahrerinsassenerkennungoderdenSchlüsselschloßschalter)aufmerksamgemachtwerdendurcheineAnzeigeimKombi.NurAudi:gültigfür:AB2(4-TürerAU352),B7,C6,D3";
CM_ SG_ 64 AB_Gurtwarn_VF "FahrerhatGurtnichtgesteckt,AnzeigeimKombi";
CM_ SG_ 64 AB_Gurtwarn_VB "BeifahrerhatGurtnichtgesteckt,AnzeigeimKombi";
CM_ SG_ 64 AB_Anzeige_Fussg "AnzeigefürausgelösteFussgängerschutz-Aktuatorik";
CM_ SG_ 64 AB_Texte_AKS "TextanzeigefürpyrotechnischeAuslösungderaktivenKopfstütze(AKS)";
CM_ SG_ 64 AB_PAO_Leuchte_Anf "AnforderungandiePassenger-Airbag-OffLeuchteinderDachkonsole(ein/aus),EinsatznurbeiPAG";
CM_ SG_ 64 AB_MKB_gueltig "Multi-Kollisions-BremsungimAirbagfreigeschaltet";
CM_ SG_ 64 AB_MKB_Anforderung "AnforderungMulti-Kollisions-Bremsung";
CM_ SG_ 64 AB_Versorgungsspannung "ÜbertragungderPlausibilitätsinformationKl.15-Lastvs.Kl.15-CAN.
Bedienung im Fall Kl.15-Last 'EIN' und Kl.15-CAN 'AUS' mit Ausgabe Warnung/Akustik im Kombi.";
CM_ SG_ 64 AB_Deaktivierung_HV "DeaktivierungdesHV-SystemsundderHV-TeilnehmerimCrash(u.a.Hybrid-undElektrofahrzeuge)";
CM_ SG_ 64 AB_EDR_Trigger "TriggerbedingungzurdezentralenAufzeichnungunfallrelevanterDatenimEventDataRecorder";
CM_ SG_ 64 AB_Belegung_VF "BelegungserkennungvorneFahrer.";
CM_ SG_ 64 AB_Gurtschloss_FA_ext "DasErgebnisderBasisfunktion'PlausibilisierungGurtschloss'desVerlassenskonzeptswirdimSignaldargestellt.";
CM_ SG_ 64 AB_Belegung_VF_ext "DasSignalkommuniziertdenStatusdesSitzbelegsensorsFahrerincl.dauerhafterZuständemitSignalqualitätASILA.";
CM_ SG_ 64 ASM_Masterzeit "MasterzeitfüralleASMSender";
CM_ SG_ 1312 Airbag_02_CRC "FürMLB:
'Berechnung siehe Lastenheft 'Kommunikationsabsicherung für FlexRay und CAN''

Ab MQB und MLBevo:
'Berechnung siehe Lastenheft 'End-to-End Kommunikationsabsicherung''

Endwerte siehe Begleitdokument 'S-PDU Kennungsfolgen'";
CM_ SG_ 1312 LoGeWa_Event_Kombiwarnung "EventfürKombiwarnung";
CM_ SG_ 1312 AB_Anforderung_eCall "TriggerfürCar2XSteuergerätdaseineCallEreigniserkanntwurde.";
CM_ SG_ 1312 AB_Anprall_Seite_Beifahrer "UebermittlungderLageeinerKollision,AnprallzoneBeifahrerseiteSeite";
CM_ SG_ 1312 AB_Anprall_Rollover "UebermittlungderLageeinerKollision,Rollovererkannt";
CM_ SG_ 1312 AB_Anprall_FGS "UebermittlungderLageeinerKollision,Fussgaengerschutz-Aktorik";
CM_ SG_ 1312 AB_Anprall_Front_Beifahrer "UebermittlungderLageeinerKollision,AnprallzoneBeifahrerseitevorne";
CM_ SG_ 1312 AB_Anprall_Front_Fahrer "UebermittlungderLageeinerKollision,AnprallzoneFahrerseitevorne";
CM_ SG_ 1312 AB_Anprall_Heck_Beifahrer "UebermittlungderLageeinerKollision,AnprallzoneBeifahrerseitehinten";
CM_ SG_ 1312 AB_Anprall_Heck_Fahrer "UebermittlungderLageeinerKollision,AnprallzoneFahrerseitehinten";
CM_ SG_ 1312 AB_Wickelklappung_Reihe2_MI "StatusWickelklappung2.ReiheMitte,Mehrausstattung";
CM_ SG_ 1312 AB_Belegung_VB "BelegungserkennungvorneBeifahrer.WirdinUS-SteuergerätenüberBladder-Mattebedient,optionalbeiRdW,fallsSBE_EuroNCAPentschiedenwird.";
CM_ SG_ 1312 AB_Abschaltanf_SIH_BF "DieInsassenerkennungaufderBeifahrerseitefordertbeiÜbertemperatureineAbschaltungderSitzheizungan.DieÜbertemperaturkannbeiniederohmigenNebenschlüssenderSitzheizungsmattealsFolgevonzuhohemresultierendenStromauftreten.";
CM_ SG_ 1312 AB_Anprall_Seite_Fahrer "UebermittlungderLageeinerKollision,AnprallzoneFahrerseiteSeite";
CM_ SG_ 1312 SC_PAO_Schriftzug_Anf "SollwertfürLED'PASSENGERAIRBAG'inAnzeigePassengerAirbagOn/Off";
CM_ SG_ 1312 SC_PAO_ON_Anf "SollwertfürLED'ON'inAnzeigePassengerAirbagOn/Off";
CM_ SG_ 1312 SC_PAO_OFF_Anf "SollwertfürLED'OFF'inAnzeigePassengerAirbagOn/Off";
CM_ SG_ 1312 AB_Crashschwere "ÜbermittlungderCrashschwereandasGateway(OBDC)";
CM_ SG_ 1312 AB_Anforderung_USM "TriggerfürGateway(OBDC)undMIB/MMI,dasseinUSM-Ereigniserkanntwurde.";
CM_ SG_ 1312 AB_Gurtschloss_FA "GurtschlosstatatusFahrerseite";
CM_ SG_ 1312 AB_Gurtschloss_BF "GurtschlossstatusBeifahrerseite";
CM_ SG_ 1312 AB_Gurtschloss_Reihe2_FA "Gurtschlossstatus2.ReiheFahrerseite,Mehrausstattung";
CM_ SG_ 1312 AB_Gurtschloss_Reihe2_MI "Gurtschlossstatus2.ReiheMitte,Mehrausstattung";
CM_ SG_ 1312 AB_Gurtschloss_Reihe2_BF "Gurtschlossstatus2.ReiheBeifahrerseite,Mehrausstattung";
CM_ SG_ 1312 AB_Gurtschloss_Reihe3_FA "Gurtschlossstatus3.ReiheFahrerseite,Mehrausstattung";
CM_ SG_ 1312 AB_Gurtschloss_Reihe3_MI "Gurtschlossstatus3.ReiheMitte,Mehrausstattung";
CM_ SG_ 1312 AB_Gurtschloss_Reihe3_BF "Gurtschlossstatus3.ReiheBeifahrerseite,Mehrausstattung";
CM_ SG_ 1312 AB_Sitzpos_Sens_FA "AusgabeSitzpositionFahrer";
CM_ SG_ 1312 AB_Sitzpos_Sens_BF "AusgabeSitzpositionBeifahrer";
CM_ SG_ 1312 AB_Wickelklappung_Reihe2_BF "StatusWickelklappung2.ReiheBeifahrerseite,Mehrausstattung";
CM_ SG_ 1312 AB_Wickelklappung_Reihe2_FA "StatusWickelklappung2.ReiheFahrerseite,Mehrausstattung";
CM_ SG_ 65 Airbag_03_CRC "FürMLB:
'Berechnung siehe Lastenheft 'Kommunikationsabsicherung für FlexRay und CAN''

Ab MQB und MLBevo:
'Berechnung siehe Lastenheft 'End-to-End Kommunikationsabsicherung''

Endwerte siehe Begleitdokument 'S-PDU Kennungsfolgen'";
CM_ SG_ 65 AB_MKB_Safing "SafingfürMulti-Kollisions-Bremsung";
CM_ SG_ 1349 AB_Gurtwarn_Reihe4_FA "StatusGurtwarnung4.SitzreiheFahrerseite";
CM_ SG_ 1349 AB_Gurtwarn_Reihe4_BF "StatusGurtwarnung4.SitzreiheBeifahrerseite";
CM_ SG_ 1349 AB_Gurtwarn_Reihe4_MI "StatusGurtwarnung4.SitzreiheMitte";
CM_ SG_ 1349 AB_Gurtwarn_Reihe2_FA "StatusGurtwarnung2.SitzreiheFahrerseite";
CM_ SG_ 1349 AB_Gurtwarn_Reihe2_BF "StatusGurtwarnung2.SitzreiheBeifahrerseite";
CM_ SG_ 1349 AbstWarn_MV_FAS_Fkt_Status "FAS-ProfileMasterIststatusderKundenfunktion";
CM_ SG_ 1349 WarnBrems_Charisma_Status "VerfügbarkeitderFunktionWarn-und/oderNotbremsfunktionfürdieAnsteuerungdurchdenCharisma-Koordinator.";
CM_ SG_ 1349 WarnBrems_Charisma_FahrPr "AktuelleingestelltesFahrprogrammderFunktionWarn-und/oderNotbremsfunktion";
CM_ SG_ 1349 AB_Gurtwarn_Reihe2_MI "StatusGurtwarnung2.SitzreiheMitte";
CM_ SG_ 1349 AB_Gurtwarn_Reihe3_FA "StatusGurtwarnung3.SitzreiheFahrerseite";
CM_ SG_ 1349 AB_Gurtwarn_Reihe3_MI "StatusGurtwarnung3.SitzreiheMitte";
CM_ SG_ 1349 AB_Gurtwarn_Reihe3_BF "StatusGurtwarnung3.SitzreiheBeifahrerseite";
CM_ SG_ 1349 LGI_FAS_Fkt_Status "FAS-ProfileMasterIststatusderKundenfunktion(LGI:LokaleGefahreninformation)";
CM_ SG_ 1349 PreCrash_FAS_Fkt_Status "FAS-ProfileMasterIststatusderKundenfunktion";
CM_ SG_ 1349 AB_SBR_hinten_verbau "VerbauinformationSitzbelegungssensorhinten(2.und3.Sitzreihe)";
CM_ SG_ 1349 AWV_Einstellung_System_ASG "SignalzurRealisierungdesBAP-Koordinators";
CM_ SG_ 1349 AWV_Einstellung_Warnung_ASG "SignalzurRealisierungdesBAP-Koordinators";
CM_ SG_ 1349 SC_PreSense_Modus_Warnung_NV "SignalzurRealisierungderBAP-KommunikationfürPreSense";
CM_ SG_ 1349 SC_PreSense_Modus_Warnung_MV "SignalzurRealisierungderBAP-KommunikationfürPreSense";
CM_ SG_ 1349 SC_PreSense_Modus_System_MV "SignalzurRealisierungderBAP-KommunikationfürPreSense";
CM_ SG_ 1349 SC_PreSense_Modus_System_NV "SignalzurRealisierungderBAP-KommunikationfürPreSense";
CM_ SG_ 1349 SC_PreSense_Modus_System_KAS "BAP-KommunikationzumKreuzungsassistent";
CM_ SG_ 2527679722 AB_Gurtschloss_Reihe4_FA "Gurtschlossstatus4.ReiheFahrerseite,Mehrausstattung";
CM_ SG_ 2527679722 AB_Gurtschloss_Reihe4_BF "Gurtschlossstatus4.ReiheBeifahrerseite,Mehrausstattung";
CM_ SG_ 2527679722 AB_Gurtschloss_Reihe4_MI "Gurtschlossstatus4.ReiheMitte,Mehrausstattung";
CM_ SG_ 1633 AAG_BZ "4bit-Botschaftszaehler,wirdinjederSendebotschaftinkrementiert

";
CM_ SG_ 1633 AAG_AVS_Fehler_02_inv "FehlerAVS(inversesSignal)";
CM_ SG_ 1633 AAG_Bremsl_durch_ECD "BremslichtdurchECDaktiv";
CM_ SG_ 1633 AAG_Anhaenger_abgesteckt "AnhaengerwurdebeiKl.15ausabgesteckt";
CM_ SG_ 1633 AAG_NSL_aktiv "AnhaengerNebelschlusslichtaktiv";
CM_ SG_ 1633 AAG_Anhaenger_erkannt "ErkennungAnhaenger";
CM_ SG_ 1633 AAG_Blinker_H_aktiv "Status:AnhaengerBlinkeraktiv";
CM_ SG_ 1633 AAG_Blinker_HL_def "AnhaengerBlinkerlinksdefekt";
CM_ SG_ 1633 AAG_Blinker_HR_def "AnhaengerBlinkerrechtsdefekt";
CM_ SG_ 1633 AAG_Bremslicht_H_def "AnhaengerBremslichtdefekt";
CM_ SG_ 1633 AAG_Schlusslicht_HL_def "AnhaengerSchlußlichtlinksdefekt";
CM_ SG_ 1633 AAG_Schlusslicht_HR_def "AnhaengerSchlußlichtrechtsdefekt";
CM_ SG_ 1633 AAG_Bremslicht_Reku "AAG_Bremslicht_RekumeldetzyklischdenempfangenenZustanddesCAN-SignalsMO_Bremslicht_Rekuzurück.";
CM_ SG_ 1633 AAG_AVS_Fehler_02 "FehlerAVS";
CM_ SG_ 1633 AAG_LED_aktiv "DiesesSignalsendetderBeleuchtungsartdesAnhängers(LEDoderLampe)
Bei LED aktiv erfolgt kein Kaltüberwachung";
CM_ SG_ 1633 AAG_AVS_Stati "StatusAVS(beiabnehmbarerodermech.schwenkbarerAnhängerkupplungistderStatusimmer0)
";
CM_ SG_ 345 ARA_Anf_Meldungen "AnforderungderMeldungen:
0 - Keine Meldung
1-127 niederprio. Meldungen
128-255 hochprio. Meldungen";
CM_ SG_ 345 ARA_Knickwinkel_konfidenz "GibteinenUnschärfewinkelzurDarstellungderVisiualisierunginderRV-AnsichtbeiNotregelungan";
CM_ SG_ 345 ARA_Texte "AnforderungfürKombianzeigetexteundAkustik";
CM_ SG_ 345 ARA_Modus "RegelmodusARAfürKombidarstellung";
CM_ SG_ 345 ARA_Aktiver_Grafikmodus "ZeigtandaseineGrafikfürARAaktiviertwerdensoll";
CM_ SG_ 345 ARA_Deaktivierung_sperren "UnterdrücktdieDeaktivierungderARA-Visualisierung";
CM_ SG_ 345 ARA_Modus_Anf "AnforderungdesARA-ModusimTürsteuergerät";
CM_ SG_ 345 ARA_Bremsfuss "AnforderungdesBremsfusssymbolsimKombi";
CM_ SG_ 345 ARA_Sensor_Aktivierung "AnforderungderAktivierungdesKnickwinkelsensors.";
CM_ SG_ 345 ARA_Knickwinkel_Komfort "Knickwinkelgrenzebiszuder,beimaximalemLenkeinschlag,einesofortigegeradeRückwärtsfahrtmöglichist.";
CM_ SG_ 345 ARA_Status "GibtdenStatusdesARAwieder";
CM_ SG_ 345 ARA_Knickwinkel_Max "GibtdenmaximalenausregelbarenKnickwinkelzwischenAnhängerundFahrzeugwieder.";
CM_ SG_ 345 ARA_Knickwinkel_Soll "VomFahrervorgegebenerKnickwinkel.";
CM_ SG_ 345 ARA_Knickwinkel_Ist "GibtdenaktuellenKnickwinkelzwischenAnhängerundFahrzeugwieder";
CM_ SG_ 2589283607 AWC_01_CRC "FürMLB:
'Berechnung siehe Lastenheft 'Kommunikationsabsicherung für FlexRay und CAN''

Ab MQB und MLBevo:
'Berechnung siehe Lastenheft 'End-to-End Kommunikationsabsicherung''

Endwerte siehe Begleitdokument 'S-PDU Kennungsfolgen'";
CM_ SG_ 2589283607 AWC_01_BZ "FortlaufenderBotschaftszaehler";
CM_ SG_ 2589283607 AWC_Status_EoHVL "ErkennungeineroffenenHV-Leitung(EoHVL),bewertetanhandeinerSpannungsgrenze";
CM_ SG_ 2589283607 AWC_Status_Spgfreiheit "InformationüberSpannungsfreiheitderHV-KomponentenfürDiagnoseundKundendienst.";
CM_ SG_ 2589283607 AWC_IstSpannung "AusgangsspannungAWCLader";
CM_ SG_ 2589283607 AWC_Fehlerstatus "aktuellerFehlerstatusdesLadegerätes
0: Komponente IO (keine HVK relevanter Fehler)
1: Eingeschränkte_Komponentenfunktion AWC Laden nicht möglich
2: reserve
3: Eingeschr_Komponentenfunktion aufgrund HV-Interlock-Fehler (nur wenn LHVIL)
4- 5: reserv";
CM_ SG_ 2589283607 AWC_IstModus "momentanerAWC-Lademodus,d.h.aktuellerZustandderEnergieübertragung(inaktiv,aktiv,verzögertoderdeaktiviert)";
CM_ SG_ 2589283607 AWC_IstStrom "AusgangsstromAWC";
CM_ SG_ 2589283607 AWC_MaxLadLeistung "MaximaleLeistungAWC-LadegerätbezogenaufdiemaximaleLeistungAWC-Infrastruktur(Kabel,Ladestation)undBerücksichtigungdesAWC-Ladegerät-Wirkungsgrades";
CM_ SG_ 219 AWV_03_CRC "FürMLB:
Berechnung siehe Lastenheft 'Kommunikationsabsicherung für FlexRay und CAN'
Ab MQB und MLBevo:
Berechnung siehe Lastenheft 'End-to-End Kommunikationsabsicherung'

Endwerte siehe Begleitdokument 'S-PDU Kennungsfolgen'";
CM_ SG_ 219 AWV_03_BZ "4bitBotschaftszähler,wirdmitjederSendebotschaftinkrementiert";
CM_ SG_ 219 PCF_Freigabe "FreigabederFunktionPreCrash-Front";
CM_ SG_ 219 SDF_PSF_Objektstatus "Objektstatus";
CM_ SG_ 219 SDF_PSF_CU_Status "Kollisionsvermeidbarkeit";
CM_ SG_ 219 SDF_PSF_CW "Kollisionswahrscheinlichkeit";
CM_ SG_ 219 SDF_PSF_Fahrer_aktiv "Fahreraktivität";
CM_ SG_ 219 SDF_PSF_Guete "GuetedesObjektes";
CM_ SG_ 219 SDF_PSF_Kollisionsueberdeckung "Kollisionsueberdeckunginy-Richtung";
CM_ SG_ 219 SDF_PSF_Time_To_Collision "ZeitbiszurKollision";
CM_ SG_ 219 SDF_PSF_v_rel "PrädizierteAufprallgeschwindigkeit";
CM_ SG_ 219 AWV_Eingriff_Sendeart "UmschaltenzwischenlangsamemundschnellemZyklusderAWV_Eingriffs-Botschaft";
CM_ SG_ 219 AWV_Verz_Freigabe "Freigabe-BitderAWVVerzögerungandasVZM";
CM_ SG_ 219 AWV_Verz_Anf "VerzögerungsanforderungderFunktionenZielbremsungundTeilbremsungandasVZM";
CM_ SG_ 219 AWV_Anf_Prefill "AnforderunganVZM,dassdiePrefill-Funktionaktiviertwerdensoll.";
CM_ SG_ 219 AWV_Ruckprofil "AnforderunganVZM,welcherRuckauseinerAuswahlvonmax.7verschiedenenRuckprofilenverwendetwerdensoll.";
CM_ SG_ 219 AWV_Time_to_collision "PrädizierterAufprallzeitpunktdesrelevantenObjektesausderAWV-Funktion";
CM_ SG_ 219 AWV_HBA_Param "AnforderunganHBAzurAnpassungderHBA-Auslöseschwelle.";
CM_ SG_ 219 AWV_Verz_Anf_ASIL "DefiniertdasAnforderungssignalvonFKTanVZMmitdemdynamischenASIL";
CM_ SG_ 219 AWV_Time_to_brake "ZeitinMillisekundenbszueinerAWVVerzögerungsanforderung(ATBoderZBR)";
CM_ SG_ 219 AWV_Zielobjekttyp "DefiniertdenZielobjekttypanVZM";
CM_ SG_ 219 AWV_QFK_KruemmSoll "Krümmungsanforderung";
CM_ SG_ 219 AWV_QFK_KruemmSoll_VZ "VorzeichenfürdieKrümmungsanforderung";
CM_ SG_ 219 AWV_QFK_Spuerb "Spürbarkeitsanforderung.Legtfest,mitwelchemHandmomentdieangeforderteKrümmungüberlenktwerdenmuss.";
CM_ SG_ 219 AWV_QFK_AnfStat "StatusinformationendesAnforderers";
CM_ SG_ 219 AWV_QFK_Signal1 "InhaltAWV_QFK_Signal1wirddurchdasSignalAWV_QFK_Art1gesteuert.
Nähere Informationen im LAH Querführungskoordinator.";
CM_ SG_ 219 AWV_QFK_Art1 "AuswahlsignalfürAWV_QFK_Signal1";
CM_ SG_ 219 AWV_QFK_Art2 "AuswahlsignalfürAWV_QFK_Signal2";
CM_ SG_ 219 AWV_QFK_Signal2 "InhaltAWV_QFK_Signal2wirddurchdasSignalAWV_QFK_Art2gesteuert.
Nähere Informationen im LAH Querführungskoordinator.";
CM_ SG_ 2536717313 BAP_EfficAssist_ASG_02_Header "EfficiencyAssistAnzeigesteuergeraet2";
CM_ SG_ 2536717314 BAP_EfficAssist_ASG_03_Header "BAPDatadummy";
CM_ SG_ 2536717328 BAP_EfficAssist_FSG_01_Header "BAPdummydata";
CM_ SG_ 869 BEM_UBDM "Batteriespannung,gemessenvomBatteriedatenmodul";
CM_ SG_ 869 NVEM_Ladefreigabe "FreigabeemfehlungzurLadungdesFMA-Zusatzspeichers";
CM_ SG_ 869 NVEM_FMAus_Info "FreilaufInformationssignalzumFreilaufkoordinator.
Gilt nur für die Freilauf Phase. Verwendung im MicroHybrid.";
CM_ SG_ 869 NVEM_PTC_Sollstufe "VorgabedesBEMandasBCMzurAktivierungdergefordertenPTC-Stufe.
Das MSG kopiert dies auf das Signal MO_PTC_Status";
CM_ SG_ 869 NVEM_P_Generator_Status "DasSignalkennzeichnetobBEM_P_GeneratoraktuellgefilterteoderungefilterteWerteüberträgt.";
CM_ SG_ 869 BEM_P_Generator "Esgilt:SignalspecBEM_P_Generatorv1.0

Mechanische Generatorleistung dient dem Motorsteuergerät zur Berechnung der Motorlast; Genauigkeit ca. +/- (500W + 20% vom Messwert)

MLBevo: Bei NVEM_P_Generator_Status = 1 wird das Signal ohne Filterung ausg";
CM_ SG_ 869 BEM_n_LLA "Esgilt:SignalspecBEM_n_LLAv1.0

Anforderung einer Leerlaufdrehzahlanhebung in drei Stufen. Die Höhe der jeweiligen LL-Drehzahlstufe ist im Motorsteuergerät appliziert.



";
CM_ SG_ 869 BEM_01_Abschaltstufen "SignalinhaltlichidentischmitBEM_02_Abschaltstufen.NamentlicheUmbenennungwegenStandard-SWimGateway-BEMimMLB(HandlinggleicherSignalnamenimSource-Code).
Abschaltstufen des Ruhestrommanagements
(Initialisierungswert aus EEPROM)";
CM_ SG_ 869 BEM_Anf_KL "Esgilt:SignalspecBEM_Anf_KLv1.1
Das BEM fordert über das MSG den Kühlerlüfter-Betrieb an; hierzu wird ein minimaler Leistungswert im MSG appliziert.
Szenario: bei erkannter abgetrennten Batterie soll durch Ansteuerung des Kühlerlüfters das Energien";
CM_ SG_ 869 BEM_StartStopp_Info "Stopp-FreigabeundStart-AnforderungandenStart-Stopp-Koordinator";
CM_ SG_ 869 BEM_DFM "Generatorauslastungsgrad,vomGeneratorüberLINandasGatewaygesandt.DasMotorsteuergerätregeltaufdiesesSignaldiePTC,dasEnergiemanagementimBSG/BCMkalkuliertdieBordnetzauslastung";
CM_ SG_ 869 BEM_EMLIN_ungueltig "Energie-Lin-SignalesindungültigvomSlaveBatteriedatenmoduloderGenerator
0 = Signale gültig
1 = Signale ungültig";
CM_ SG_ 869 BEM_Batt_Ab "Batterieverbindungskontrolle:
0x0: Batterie am Bordnetz
0x1: Batterie ab erkannt";
CM_ SG_ 869 NVEM_FMAus_I_Verbrauch "PredezierterBordneztstromverbrauchwährendderFreilaufMotorAusPhase.";
CM_ SG_ 869 NVEM_Freilauf_Info "FreilaufInformationssignalvomNVEMzumFreilaufkoordinator.DasNVEMkannüberdiesesSignaldenFreilauffreigeben,verhindernbzw.explizitanfordern.";
CM_ SG_ 869 BEM_NV_NachladAnf "BeiEnergiedefizitaufderNiedervoltseitewirdderLademanageraufgefordert,dieNiedervoltseitenachzuladen.";
CM_ SG_ 869 BEM_Segel_Info "0:keineAnforderung
(Segeln ist ohne Einschänkung erlaubt)
1: Mindestdrehzahl 1
(Segeln ist mit Einschänkung erlaubt)
2: Mindestdrehzahl 2
(Segeln ist mit Einschänkung erlaubt)
3: Segelveto
(Segeln ist nicht  erlaubt)";
CM_ SG_ 869 BEM_HYB_DC_uSollLV "SollwertfürdieBordnetzspannungimTiefsetzbetriebvomTraktionsnetzinsBordnetz(Hybrid)";
CM_ SG_ 869 BEM_HYB_DC_uMinLV "Abregelgrenze:minimalerlaubteBordnetzspannungimHochsetzbetrieb(Hybrid)";
CM_ SG_ 1442 BMS_04_CRC "FürMLB:
'Berechnung siehe Lastenheft 'Kommunikationsabsicherung für FlexRay und CAN''

Ab MQB und MLBevo:
'Berechnung siehe Lastenheft 'End-to-End Kommunikationsabsicherung''

Endwerte siehe Begleitdokument 'S-PDU Kennungsfolgen'";
CM_ SG_ 1442 BMS_Fehler_Pilot "SignalisiertdenStatusderPilotlinieBMS.";
CM_ SG_ 1442 BMS_Status_ServiceDisconnect "StatusdesServiceDisconnect,obdiesergestecktodergezogenist.
Abhängigkeiten zu anderen Signalen: BMS_Fehler_Sicherung und BMS_Fehler_Pilot";
CM_ SG_ 1442 BMS_Status_Spgfreiheit "0=Init(ohneFunktion)
1=BMS Zwischenkreis spannungsfrei (U_Zwkr < 20V)
2=BMS Zwischenkreis nicht spannungsfrei (U_Zwkr >/= 25V, Hysterese)
3=Fehler (z.B. Fehler in der Sensorik)";
CM_ SG_ 1442 BMS_OBD_Lampe_Anf "AnforderungMIL(MalfunctionIndicationLamp)vonBMS(MotorsteuergerätreichtdieseInfoanKombiweiter).";
CM_ SG_ 1442 BMS_Fehlerstatus "aktuellerFehlerstatusderBatterie";
CM_ SG_ 1442 BMS_Kapazitaet_02 "NutzbareKapazitätderBatterie,
oder alterungsabhängige absolute Gesamtkapazität der Batterie.

Projektabhängig kann die Kapazität auf das nutzbare SOC-Fenster (zwischen oberer und unterer SOC-Grenze) bezogen sein, wobei sich dieses SOC-Fenster alteru";
CM_ SG_ 1442 BMS_Fehlerlampe_Anf "AnforderungderrotenHybrid-WarnlampeimKombi";
CM_ SG_ 1442 BMS_Warnlampe_Anf "AnforderungdergelbenHybrid-WarnlampeimKombi";
CM_ SG_ 1442 BMS_Kl30c_Status "Stecker-ZustanddesService-Disconnect(Klemme30c)";
CM_ SG_ 2527679654 BMS_11_CRC "FürMLB:
Berechnung siehe Lastenheft 'Kommunikationsabsicherung für FlexRay und CAN'
Ab MQB und MLBevo:
Berechnung siehe Lastenheft 'End-to-End Kommunikationsabsicherung'

Endwerte siehe Begleitdokument 'S-PDU Kennungsfolgen'";
CM_ SG_ 2527679654 BMS_11_BZ "4bitBotschaftszähler,wirdmitjederSendebotschaftinkrementiert";
CM_ SG_ 2527679654 BMS_IsoZustand "Ergebnisdesaktuellen/letztenIsolations-Meßzyklus:Messungläuft;MessungBatterie-internoderGesamtsystem;gemessenerWertunterschreitetSchwelle1/Schwelle2.";
CM_ SG_ 2527679654 BMS_IsoFehler "ErgebnisderIsolationsmessungdesBMS";
CM_ SG_ 2527679654 BMS_IstTemperatur_hoechste "aktuellhöchsteTemperaturinderBatterie";
CM_ SG_ 2527679654 BMS_IstTemperatur_niedrigste "aktuellniedrigsteTemperaturinderBatterie";
CM_ SG_ 2527679654 BMS_IstZellspannung_hoechste "höchsterWertallerZellspannungenimBMS";
CM_ SG_ 2527679654 BMS_IstZellspannung_niedrigste "niedrigsterWertallerZellspannungenimBMS";
CM_ SG_ 207 BMS_20_CRC "FürMLB:
Berechnung siehe Lastenheft 'Kommunikationsabsicherung für FlexRay und CAN'
Ab MQB und MLBevo:
Berechnung siehe Lastenheft 'End-to-End Kommunikationsabsicherung'

Endwerte siehe Begleitdokument 'S-PDU Kennungsfolgen'";
CM_ SG_ 207 BMS_20_BZ "4bitBotschaftszähler,wirdmitjederSendebotschaftinkrementiert";
CM_ SG_ 207 BMS_Fehlerstatus_HV_Schuetze "FehlerstatusderHV-Schütze,Verschweißt-Erkennung";
CM_ SG_ 207 BMS_ErwGrenzen_aktiv "dieaktuellenStromgrenzenderHV-BatteriesindzumStartdesVerbrennungsmotorsaufgeweitet/BestätigungderAnforderung";
CM_ SG_ 207 BMS_IstModus "AktuellerBetriebsmodusderBatterie
0: Standby; Schuetze geoeffnet; Kommunikation aktiv
1: Hauptschuetze geschlossen / HV-Netz aktiviert / normaler Fahrbetrieb
2: projektabhaengig belegt (z.B. Balancing, erweitertes DC-Schnelladen)
3: externes Laden ";
CM_ SG_ 207 BMS_HVIL_Status "SignalstatusHVIL/Pilotlinie";
CM_ SG_ 207 BMS_Fehler_HVBattAbschaltung "Fehler:Fehlerzustand,erfordertdasÖffnenderBatterieschütze
interner Batteriefehler, Batterieschütze ohne Vorankündigung durch das BMS geöffnet";
CM_ SG_ 207 BMS_Fehler_HVBattAbschaltung_Anf "Fehler:Fehlerzustand,erfordertdasÖffnenderBatterieschütze
interner Batteriefehler; Vorankündigung eines bevorstehenden Öffnens der Batterieschütze durch das BMS";
CM_ SG_ 207 BMS_Fehler_Leistungsred "Fehler:LeistungsfähigkeitderBatterieisteingeschränkt(z.B.aufgrunddesAusfallsvonSensorenoderdesLüfters)";
CM_ SG_ 207 BMS_Strom "AktuellerStromderBatterie.
Stromrichtung: Ladestrom wird mit positiven, Entladestrom mit negativen Werten angegeben.";
CM_ SG_ 207 BMS_Fehler_Notabschaltung_Crash "Fehler:SicherheitskritischerFehler(Crash-Erkennung)
Batterieschütze sind bereits geöffnet / werden sofort geöffnet
Signal wird direkt vom EMS gelesen und initiiert einen AKS des PWR und eine aktive Entladung des Zwischenkreises";
CM_ SG_ 207 BMS_Spannung_Zwischenkreis "AktuelleSpannungandenBatterie-HV-Anschlüssen;AbgangderBatteriezumZwischenkreis/HV-Bordnetz/zurLeistungselektronik.";
CM_ SG_ 207 BMS_Spannung "AktuelleSpannungderBatterie.
Innerhalb der Batterie an den Zellmodulen gemessen, also _vor_ den Schützen und der Sicherung.";
CM_ SG_ 2463978704 BMS_Max_Entladestrom "ZwingendeinzuhaltenderGrenzwertfürdenEntladestromderBatterie.
Darf aus Bauteilschutzgründen nicht überschritten werden.
Aus Lebensdauersicht muss zusätzlich die Leistungsgrenze eingehalten werden.";
CM_ SG_ 2463978704 BMS_Max_Ladestrom "ZwingendeinzuhaltenderGrenzwertfürdenLadestromderBatterie.
Darf aus Bauteilschutzgründen nicht überschritten werden.
Aus Lebensdauersicht muss zusätzlich die Leistungs- und SOC-Grenze eingehalten werden.";
CM_ SG_ 2463978704 BMS_Max_Entladeleistung "MaximaleLeistung,mitderdieBatteriemomentanbelastetwerdendarf.
Kurze Überschwinger aufgrund dynamischen Verhalten des Reglers sind nach Absprache möglich, aber
hierbei muss unbedingt auch der maximale Entladestrom berücksichtigt werden.";
CM_ SG_ 2463978704 BMS_Max_Ladeleistung "MaximaleLeistung,mitderdieBatterieaktuellgeladenwerdendarf.
Kurze Überschwinger aufgrund dynamischen Verhalten des Reglers sind nach Absprache möglich, aber
hierbei muss unbedingt auch der maximale Ladestrom berücksichtigt werden.";
CM_ SG_ 2463978705 BMS_Status_EoHVL_Heizer "StatusErkennungoffenerHV-Leitung(EoHVL)/offeneSteckverbindungzumHV-Batterieheizer(PTC):
0=Init
1=Keine offene HV-Leitung erkannt
2=offene HV-Leitung erkannt
3=Fehler";
CM_ SG_ 2463978705 BMS_Ladezustand "AktuellerLadezustand(SOC)derBatterie.
Es handelt sich NICHT um den dem Fahrer angezeigten Füllstand der Batterie, sondern um den technisch ermittelten, batterie-internen Ladezustand, bezogen auf die Brutto-Kapazität der Batterie.";
CM_ SG_ 2463978705 BMS_PerfInd_Entladen "LeistungsindikationinEntladerichtung.
Der Bereich 100...200% beschreibt die verbleibende Reserve, bis ein Derating der maximalen Entladeleistungsgrenze eintritt.
Werte von 0 bis 100% beschreiben, auf welchen Teil der potentiell möglichen maximalen Ent";
CM_ SG_ 2463978705 BMS_PerfInd_Laden "LeistungsindikationinLaderichtung.
Der Bereich 100...200% beschreibt die verbleibende Reserve, bis ein Derating der maximalen Ladeleistungsgrenze eintritt.
Werte von 0 bis 100% beschreiben, auf welchen Teil der potentiell möglichen maximalen Ladeleist";
CM_ SG_ 2463978705 BMS_Nutzbare_EntladeEnergie "Aktuelle,verbleibendeEnergiemenge,dienochausderBatterieentladenwerdenkann.
Diese hängt in erster Linie vom aktuellen Ladezustand der Batterie ab.

Projektabhängig kann die Energiemenge noch vom variablen SOC-Fenster, dem Alterungszustand, dem";
CM_ SG_ 2589283664 BMS_Balancing_Aktiv "Signalzeigtan,obmindestenseineZellederHVBatteriebalanciertwird";
CM_ SG_ 2589283664 BMS_Ladevorgang_aktiv "SignalisiertaktivenLadevorgang,LadegerätundDC/DCaktiv.
Signal bleibt nach Kl.15 ein aktiv, bis ESP_Stillstandsflag gelöscht.

Abhängigkeit zu BMS_Energieinhalt";
CM_ SG_ 2589283664 BMS_RIso_Ext "MinimumdesIsolationswiderstandszwischenBatteriegehäuseundHV+bzw.BatteriegehäuseundHV-beigeschlossenenSchützen(externeIsoMessung)";
CM_ SG_ 2589283664 BMS_Min_Ladezustand "UntereLadezustandsgrenzefürdasSOC-FensterinderBetriebsstrategie.
Der Wert kann sich über Lebensdauer und Alterung des Batteriesystems änder";
CM_ SG_ 2589283664 BMS_Max_Energie "NutzbarermaximalerEntlade-EnergieinhaltdervollgeladenenBatterie.

Projektabhängig kann der Energiewert vom variablen SOC-Fenster (zwischen oberer und unterer SOC-Grenze), dem Alterungszustand, dem aktuellen Lastprofil sowie der Temperatur abhängen";
CM_ SG_ 2589283664 BMS_Max_Ladezustand "ObereLadezustandsgrenzefürdasSOC-FensterinderBetriebsstrategie.
Der Wert kann sich über Lebensdauer und Alterung des Batteriesystems änder";
CM_ SG_ 2589283665 BMS_BattHeizung_VerbautStatus "VerbausignalisierungderoptionalenHV-Batterieheizung";
CM_ SG_ 2589283665 BMS_Fehler_NTKreis "FehlerimNTKreis,HV-Batteriewirdnichtklimatisiert
(Fehler, Fehlerfrei) ";
CM_ SG_ 2589283665 BMS_Temperierung_Anf "TemperierungsbedarfderHV-Batterie";
CM_ SG_ 2589283665 BMS_Status_Ventil1 "StatusVentil;wassergekühltesBatteriesystem.
Batteriekreis-Absperrventil.

nicht-angesteuert = Batterie im kleinen Kühlkreislauf, abgetrennt vom restlichen Kühlsystem
angesteuert = Batterie eingeschleift in großen Kühlkreislauf (Niedertemperatur-Küh";
CM_ SG_ 2589283665 BMS_Status_Ventil2 "StatusdeszweitenVentils;wassergekühltesBatteriesystem.
Für Systeme, wo die Batterie ein zweites Ventil ansteuert.
Belegung projektabhängig.

nicht-angesteuert = großer Kühlkreislauf (Niedertemperatur-Kühlkreis) abgetrennt vom Batteriesystem oder ";
CM_ SG_ 2589283665 BMS_Pumpe1_Ansteuerung "AnsteuerungderBatterie-Kühlmittelpumpe.
0% = Pumpe abgeschaltet
100% = Pumpe maximal angesteuert";
CM_ SG_ 2589283665 BMS_Pumpe2_Ansteuerung "AnsteuerungeinerzweitenKühlmittelpumpe.
Projektabhängig für Systeme, die seitens Batterie zwei Pumpen ansteuern.
0% = Pumpe abgeschaltet
100% = Pumpe maximal angesteuert";
CM_ SG_ 2589283665 BMS_VorlaufTemperatur "AktuellerMesswertderKühlmittel-Vorlauftemperatur
am Kühlmittel-Einlass des Batteriesystems.";
CM_ SG_ 2589283665 BMS_Temperatur "batterytemperature/Momentanwert:TemperaturderTraktionsbatterie";
CM_ SG_ 2589283665 BMS_SollVorlauftemperatur "Soll_Vorlauftemperatur_Kühlmediumin°C";
CM_ SG_ 2589283665 BMS_RuecklaufTemperatur "AktuellerMesswertderKühlmittel-Rücklauftemperatur
am Kühlmittel-Auslass des Batteriesystems.";
CM_ SG_ 2589283760 BMS_Max_Spannung "MaximalerlaubteBatteriespannung,zwingendeinzuhaltenderGrenzwert";
CM_ SG_ 2589283760 BMS_Min_Spannung "MinimalerlaubteBatteriespannung,zwingendeinzuhaltenderGrenzwert";
CM_ SG_ 2589283760 BMS_Dauer_Entladeleistung "istdieaktuelleDauer-LeistungsfähigkeitderBatterie.
Wenn dieser Wert überschritten wird, kann ein zeitliches Derating der maximalen Leistungsgrenzen stattfindet. Die Dauerleistung ändert sich mit Batterietemperatur und Ladezustand.";
CM_ SG_ 2589283760 BMS_Dauer_Ladeleistung "istdieaktuelleDauer-LeistungsfähigkeitderBatterie.
Wenn dieser Wert überschritten wird, kann ein zeitliches Derating der maximalen Leistungsgrenzen stattfindet. Die Dauerleistung ändert sich mit Batterietemperatur und Ladezustand.";
CM_ SG_ 2463978646 CHA_Ziel_FahrPr_AGA "AnforderungZiel-FahrprogrammAGA/SAK2(Aussensound)";
CM_ SG_ 2463978646 CHA_Ziel_FahrPr_ESP "AnforderungZiel-FahrprogrammESP";
CM_ SG_ 2463978646 CHA_Ziel_FahrPr_Freilauf "AnforderungZiel-FahrprogrammFunktionFreilauf";
CM_ SG_ 2463978646 CHA_Fahrer_Umschaltung "DiemanuelleUmschaltungdurchdenFahrersollsignalisiertwerden,umzuautomatischenUmschaltungen(z.B.Retries)differenzierenzukönnen.";
CM_ SG_ 2463978646 CHA_Fahrer_Umschaltung_BMA "DiemanuelleUmschaltungderBetriebsmodusauswahldurchdenFahrersollsignalisiertwerden,umzuautomatischenUmschaltungen(z.B.Retries)differenzierenzukönnen.";
CM_ SG_ 2463978646 CHA_Ziel_FahrPr_MO "AnforderungZiel-FahrprogrammMotor";
CM_ SG_ 2463978646 CHA_Ziel_FahrPr_GE "AnforderungZiel-FahrprogrammGetriebe";
CM_ SG_ 2463978646 CHA_Ziel_FahrPr_ALR "AnforderungZiel-FahrprogrammAllrad";
CM_ SG_ 2463978646 CHA_Ziel_FahrPr_MO_BZS "AnforderungZielfahrprogrammMotor-Betriebszusände";
CM_ SG_ 2463978646 CHA_Ziel_FahrPr_DR "AnforderungZiel-FahrprogrammDämpfer";
CM_ SG_ 2463978646 CHA_Ziel_FahrPr_VAQ "AnforderungZiel-FahrprogrammVAQ";
CM_ SG_ 2463978646 CHA_Ziel_FahrPr_AFS "AnforderungZiel-FahrprogrammAFS";
CM_ SG_ 2463978646 CHA_Ziel_FahrPr_PreCrash "AnforderungZiel-FahrprogrammPreCrash";
CM_ SG_ 2463978646 CHA_Ziel_FahrPr_EPS "AnforderungZiel-FahrprogrammElektrischeLenkhilfe";
CM_ SG_ 2463978646 CHA_Ziel_FahrPr_ACC "MQB
Anforderung Ziel-Fahrprogramm ACC";
CM_ SG_ 2463978646 CHA_Ziel_FahrPr_SAK "AnforderungZiel-FahrprogrammSoundaktuator";
CM_ SG_ 2463978646 CHA_Ziel_FahrPr_MO_StSt "AnforderungZiel-FahrprogrammFunktionMotorStart-Stopp";
CM_ SG_ 2463978646 CHA_Ziel_FahrPr_EBKV "SignalzurAnsteuerungdesEBKVdurchdenCharisma-Koordinator";
CM_ SG_ 2463978646 CHA_Ziel_FahrPr_IL "AnforderungZiel-FahrprogrammIntegrallenkung";
CM_ SG_ 2463978646 CHA_Current_Mode "AktuelleingestelltesCharismaFahrprogramm";
CM_ SG_ 2463978646 CHA_Ziel_FahrPr_QS "AnforderungZiel-FahrprogrammgeregelteHinterachsquersperre";
CM_ SG_ 2463978646 CHA_Ziel_FahrPr_SCU "AnforderungZiel-FahrprogrammSCU";
CM_ SG_ 2463978646 CHA_Ziel_FahrPr_HAL "AnforderungZielfahrprogrammHinterachslenkung(HAL)";
CM_ SG_ 2463978646 CHA_Ziel_FahrPr_NR "AnforderungZiel-FahrprogrammNiveaureglierung";
CM_ SG_ 2463978646 CHA_Ziel_FahrPr_AV "AnforderungZiel-FahrprogrammAreaView2";
CM_ SG_ 2463978646 CHA_Ziel_FahrPr_MXB "AnforderungZiel-FahrprogrammMXB";
CM_ SG_ 2463978646 CHA_Ziel_FahrPr_AFR "AnforderungZiel-FahrprogrammAktiveFahrwerkRegelung(eAWSundeABC)";
CM_ SG_ 2463978646 CHA_Ziel_FahrPr_HDC "AnforderungZiel-FahrprogrammHillDescentControl";
CM_ SG_ 2463978646 CHA_Ziel_FahrPr_EAR "AnforderungZielfahrprogrammEAR(EFPAllradRegelsysteme)";
CM_ SG_ 2463978646 CHA_Ziel_FahrPr_AEB "AnforderungZiel-FahrprogrammAEB(AutonomousEmergencyBraking)";
CM_ SG_ 2463978646 CHA_Ziel_FahrPr_FCWO "AnforderungZiel-FahrprogrammFCWO(Objektwarnung)";
CM_ SG_ 2463978646 CHA_Ziel_FahrPr_FCWP "AnforderungZiel-FahrprogrammFCWP(Personenwarnung)";
CM_ SG_ 2463978646 CHA_Ziel_FahrPr_ToS_laengs "SignalzurAnsteuerungdesTorqueSplitterlängsdurchdenCharisma-Koordinator";
CM_ SG_ 2463978646 CHA_Ziel_FahrPr_ToS_quer "SignalzurAnsteuerungdesTorqueSplitterquerdurchdenCharisma-Koordinator";
CM_ SG_ 2463978646 CHA_Ziel_FahrPr_mFDR "SignalzurAnsteuerungdesmFDRdurchdenCharisma-Koordinator";
CM_ SG_ 2463978646 CHA_Ziel_FahrPr_Reku_ZwGas "AnforderungZiel-FahrprogrammfürRekuperationoderZwischengas";
CM_ SG_ 2463978646 CHA_Ziel_FahrPr_MO_Freilauf "AnforderungZiel-FahrprogrammFunktionFreilaufMotoraus";
CM_ SG_ 2463978646 CHA_Ziel_FahrPr_BMS "AnforderungZiel-FahrprogrammBMS(nähereSpezifikationsieheCharisma-LHPAG)";
CM_ SG_ 2463978646 CHA_Current_Mode_BMA "AktuelleingestellterCharismaBetriebsmodus";
CM_ SG_ 2463978646 CHA_Ziel_FahrPr_PDC "SignalzurAnsteuerungdesPDC/PLAdurchdenCharisma-Koordinator";
CM_ SG_ 2463978646 CHA_Ziel_FahrPr_HHC "AnforderungZiel-FahrprogrammHillHoldControl";
CM_ SG_ 2463978646 CHA_Ziel_FahrPr_EDS "AnforderungZiel-FahrprogrammElektronischeDifferentialsperre";
CM_ SG_ 2463978646 CHA_Ziel_FahrPr_PACC "AnforderungZiel-FahrprogrammInnoDrive(PACCh)";
CM_ SG_ 2463978646 CHA_Ziel_FahrPr_AGK "SignalzurAnsteuerungdesTeilnehmersAbgasklappendurchdenCharisma-KoordinatorüberdasMotor-SG";
BA_DEF_  "DBName" STRING;
BA_DEF_  "GenNWMApBusSleep" STRING;
BA_DEF_  "GenNWMApCanNormal" STRING;
BA_DEF_  "GenNWMApCanOff" STRING;
BA_DEF_  "GenNWMApCanOn" STRING;
BA_DEF_  "GenNWMApCanSleep" STRING;
BA_DEF_  "GenNWMApCanWakeUp" STRING;
BA_DEF_  "GenNWMGotoMode_Awake" STRING;
BA_DEF_  "GenNWMGotoMode_BusSleep" STRING;
BA_DEF_  "GenNWMSleepTime" INT 0 1000000;
BA_DEF_  "GenNWMTalkNM" STRING;
BA_DEF_  "Manufacturer" STRING;
BA_DEF_  "NmhBaseAddress" HEX 0 536870911;
BA_DEF_  "NmhMessageCount" INT 0 1024;
BA_DEF_  "NmType" STRING;
BA_DEF_  "VAGTP20_SetupMessageCount" INT 0 255;
BA_DEF_  "VAGTP20_SetupStartAddress" HEX 0 2047;
BA_DEF_  "VersionDay" INT 1 31;
BA_DEF_  "VersionMonth" INT 1 12;
BA_DEF_  "VersionWeek" INT 1 52;
BA_DEF_  "VersionYear" INT 0 99;
BA_DEF_  "VersionNumber" INT 0 65535;
BA_DEF_  "BusType" STRING;
BA_DEF_  "Baudrate" INT 1 1000000;
BA_DEF_  "BaudrateCANFD" INT 1 16000000;
BA_DEF_  "NmhTimeoutTimer" INT 0 65535;
BA_DEF_  "NmhWaitBusSleepTimer" INT 0 65535;
BA_DEF_  "NmhPrepareBusSleepTimer" INT 0 65535;
BA_DEF_  "NmhLongTimer" INT 0 65535;
BA_DEF_  "NmhNStart" INT 0 255;
BA_DEF_ BU_ "GenNodAutoGenDsp" ENUM "No", "Yes";
BA_DEF_ BU_ "GenNodAutoGenSnd" ENUM "No", "Yes";
BA_DEF_ BU_ "GenNodSleepTime" INT 0 1000000;
BA_DEF_ BU_ "ILUsed" ENUM "No", "Yes";
BA_DEF_ BU_ "ECUVariantDefault" ENUM "No", "Yes";
BA_DEF_ BU_ "ECUVariantGroup" STRING;
BA_DEF_ BU_ "NodeLayerModules" STRING;
BA_DEF_ BU_ "NmhNode" ENUM "No", "Yes";
BA_DEF_ BU_ "NmNode" ENUM "No", "Yes";
BA_DEF_ BU_ "SamplePointMin" FLOAT 50.000000 99.900000;
BA_DEF_ BU_ "SamplePointMax" FLOAT 50.000000 99.900000;
BA_DEF_ BU_ "SyncJumpWidthMin" FLOAT 0.000000 50.000000;
BA_DEF_ BU_ "SyncJumpWidthMax" FLOAT 0.000000 50.000000;
BA_DEF_ BU_ "SyncJumpWidthCANFDMin" FLOAT 0.000000 50.000000;
BA_DEF_ BU_ "SyncJumpWidthCANFDMax" FLOAT 0.000000 50.000000;
BA_DEF_ BU_ "SamplePointCANFDMin" FLOAT 50.000000 99.900000;
BA_DEF_ BU_ "SamplePointCANFDMax" FLOAT 50.000000 99.900000;
BA_DEF_ BU_ "SSPOffsetCANFDMin" FLOAT 50.000000 99.900000;
BA_DEF_ BU_ "SSPOffsetCANFDMax" FLOAT 50.000000 99.900000;
BA_DEF_ BU_ "TimeQuantaMin" INT 4 257;
BA_DEF_ BU_ "TimeQuantaMax" INT 4 257;
BA_DEF_ BU_ "TimeQuantaCANFDMin" INT 4 257;
BA_DEF_ BU_ "TimeQuantaCANFDMax" INT 4 257;
BA_DEF_ BO_ "DiagRequest" ENUM "No", "Yes";
BA_DEF_ BO_ "DiagResponse" ENUM "No", "Yes";
BA_DEF_ BO_ "DiagState" ENUM "No", "Yes";
BA_DEF_ BO_ "GenMsgChkConstant" HEX 0 4095;
BA_DEF_ BO_ "GenMsgCycleTime" INT 0 65535;
BA_DEF_ BO_ "GenMsgCycleTimeFast" INT 0 65535;
BA_DEF_ BO_ "GenMsgDelayTime" INT 0 100000;
BA_DEF_ BO_ "GenMsgILSupport" ENUM "No", "Yes";
BA_DEF_ BO_ "GenMsgNrOfRepetition" INT 0 100;
BA_DEF_ BO_ "GenMsgPDUConstants" STRING;
BA_DEF_ BO_ "GenMsgSendType" ENUM "Cyclic", "not_used", "not_used", "not_used", "not_used", "not_used", "not_used", "IfActive", "NoMsgSendType";
BA_DEF_ BO_ "GenMsgStartDelayTime" INT 0 100000;
BA_DEF_ BO_ "NmMessage" ENUM "No", "Yes";
BA_DEF_ BO_ "NmhMessage" ENUM "No", "Yes";
BA_DEF_ BO_ "MsgType" ENUM "Application", "NM", "NMH", "TP2.0", "ISO-TP", "BAP", "EID", "KS";
BA_DEF_ BO_ "VAGTP20_API" HEX 0 255;
BA_DEF_ BO_ "VAGTP20_DynConnection" ENUM "No", "Yes";
BA_DEF_ BO_ "VAGTP20_DynSetup" ENUM "No", "Yes";
BA_DEF_ BO_ "VAGTP20_StatConnection" ENUM "No", "Yes";
BA_DEF_ BO_ "CANFD_BRS" ENUM "0", "1";
BA_DEF_ BO_ "VFrameFormat" ENUM "StandardCAN", "ExtendedCAN", "reserved", "reserved", "reserved", "reserved", "reserved", "reserved", "reserved", "reserved", "reserved", "reserved", "reserved", "reserved", "StandardCAN_FD", "ExtendedCAN_FD";
BA_DEF_ SG_ "GenSigActiveRepetitions" INT -2147483648 2147483647;
BA_DEF_ SG_ "GenSigInactiveValue" INT -2147483648 2147483647;
BA_DEF_ SG_ "GenSigSendType" ENUM "Cyclic", "OnWrite", "OnWriteWithRepetition", "OnChange", "OnChangeWithRepetition", "IfActive", "IfActiveWithRepetition", "NoSigSendType", "OnChangeAndIfActive", "OnChangeAndIfActiveWithRepetition";
BA_DEF_ SG_ "GenSigStartValue" INT -2147483648 2147483647;
BA_DEF_ SG_ "NWM-WakeupAllowed" ENUM "No", "Yes";
BA_DEF_ SG_ "GenSigFuncType" ENUM "NoFunction", "MsgCounter", "CRC-8", "XOR", "XOR-2", "DatedBit", "SW-Kl15", "CHK", "Constant", "Protocol", "CRC-8-SAE_J1850";
BA_DEF_ SG_ "GenSigSwitchedByIgnition" ENUM "No", "Yes";
BA_DEF_ SG_ "Fehlerwert" HEX 0 2147483647;
BA_DEF_ SG_ "GenSigMissingSourceValue" HEX 0 2147483647;
BA_DEF_DEF_  "DBName" "";
BA_DEF_DEF_  "GenNWMApBusSleep" "";
BA_DEF_DEF_  "GenNWMApCanNormal" "";
BA_DEF_DEF_  "GenNWMApCanOff" "";
BA_DEF_DEF_  "GenNWMApCanOn" "";
BA_DEF_DEF_  "GenNWMApCanSleep" "";
BA_DEF_DEF_  "GenNWMApCanWakeUp" "";
BA_DEF_DEF_  "GenNWMGotoMode_Awake" "";
BA_DEF_DEF_  "GenNWMGotoMode_BusSleep" "";
BA_DEF_DEF_  "GenNWMSleepTime" 0;
BA_DEF_DEF_  "GenNWMTalkNM" "";
BA_DEF_DEF_  "Manufacturer" "";
BA_DEF_DEF_  "NmhBaseAddress" 0;
BA_DEF_DEF_  "NmhMessageCount" 1;
BA_DEF_DEF_  "NmType" "None";
BA_DEF_DEF_  "VAGTP20_SetupMessageCount" 0;
BA_DEF_DEF_  "VAGTP20_SetupStartAddress" 0;
BA_DEF_DEF_  "VersionDay" 8;
BA_DEF_DEF_  "VersionMonth" 2;
BA_DEF_DEF_  "VersionWeek" 6;
BA_DEF_DEF_  "VersionYear" 18;
BA_DEF_DEF_  "VersionNumber" 0;
BA_DEF_DEF_  "BusType" "";
BA_DEF_DEF_  "Baudrate" 500000;
BA_DEF_DEF_  "BaudrateCANFD" 2000000;
BA_DEF_DEF_  "NmhTimeoutTimer" 0;
BA_DEF_DEF_  "NmhWaitBusSleepTimer" 0;
BA_DEF_DEF_  "NmhPrepareBusSleepTimer" 0;
BA_DEF_DEF_  "NmhLongTimer" 0;
BA_DEF_DEF_  "NmhNStart" 0;
BA_DEF_DEF_  "GenNodAutoGenDsp" "Yes";
BA_DEF_DEF_  "GenNodAutoGenSnd" "Yes";
BA_DEF_DEF_  "GenNodSleepTime" 0;
BA_DEF_DEF_  "ILUsed" "Yes";
BA_DEF_DEF_  "ECUVariantDefault" "Yes";
BA_DEF_DEF_  "ECUVariantGroup" "";
BA_DEF_DEF_  "NodeLayerModules" "";
BA_DEF_DEF_  "NmhNode" "Yes";
BA_DEF_DEF_  "NmNode" "No";
BA_DEF_DEF_  "SamplePointMin" 75.000000;
BA_DEF_DEF_  "SamplePointMax" 75.000000;
BA_DEF_DEF_  "SyncJumpWidthMin" 50.000000;
BA_DEF_DEF_  "SyncJumpWidthMax" 50.000000;
BA_DEF_DEF_  "SyncJumpWidthCANFDMin" 50.000000;
BA_DEF_DEF_  "SyncJumpWidthCANFDMax" 50.000000;
BA_DEF_DEF_  "SamplePointCANFDMin" 75.000000;
BA_DEF_DEF_  "SamplePointCANFDMax" 75.000000;
BA_DEF_DEF_  "SSPOffsetCANFDMin" 75.000000;
BA_DEF_DEF_  "SSPOffsetCANFDMax" 75.000000;
BA_DEF_DEF_  "TimeQuantaMin" 160;
BA_DEF_DEF_  "TimeQuantaMax" 160;
BA_DEF_DEF_  "TimeQuantaCANFDMin" 40;
BA_DEF_DEF_  "TimeQuantaCANFDMax" 40;
BA_DEF_DEF_  "DiagRequest" "No";
BA_DEF_DEF_  "DiagResponse" "No";
BA_DEF_DEF_  "DiagState" "No";
BA_DEF_DEF_  "GenMsgChkConstant" 0;
BA_DEF_DEF_  "GenMsgCycleTime" 0;
BA_DEF_DEF_  "GenMsgCycleTimeFast" 0;
BA_DEF_DEF_  "GenMsgDelayTime" 0;
BA_DEF_DEF_  "GenMsgILSupport" "No";
BA_DEF_DEF_  "GenMsgNrOfRepetition" 0;
BA_DEF_DEF_  "GenMsgPDUConstants" "";
BA_DEF_DEF_  "GenMsgSendType" "NoMsgSendType";
BA_DEF_DEF_  "GenMsgStartDelayTime" 0;
BA_DEF_DEF_  "NmMessage" "No";
BA_DEF_DEF_  "NmhMessage" "No";
BA_DEF_DEF_  "MsgType" "Application";
BA_DEF_DEF_  "VAGTP20_API" 0;
BA_DEF_DEF_  "VAGTP20_DynConnection" "No";
BA_DEF_DEF_  "VAGTP20_DynSetup" "No";
BA_DEF_DEF_  "VAGTP20_StatConnection" "No";
BA_DEF_DEF_  "CANFD_BRS" "1";
BA_DEF_DEF_  "VFrameFormat" "StandardCAN";
BA_DEF_DEF_  "GenSigActiveRepetitions" 0;
BA_DEF_DEF_  "GenSigInactiveValue" 0;
BA_DEF_DEF_  "GenSigSendType" "NoSigSendType";
BA_DEF_DEF_  "GenSigStartValue" 0;
BA_DEF_DEF_  "NWM-WakeupAllowed" "No";
BA_DEF_DEF_  "GenSigFuncType" "NoFunction";
BA_DEF_DEF_  "GenSigSwitchedByIgnition" "Yes";
BA_DEF_DEF_  "Fehlerwert" 0;
BA_DEF_DEF_  "GenSigMissingSourceValue" 0;
BA_ "DBName" "MEB_ACANFD";
BA_ "GenNWMApBusSleep" "NMIndNetSDN()";
BA_ "GenNWMApCanNormal" "apCanNormal()";
BA_ "GenNWMApCanOff" "NMIndnetOff()";
BA_ "GenNWMApCanOn" "NMIndnetOn()";
BA_ "GenNWMApCanSleep" "apCanSleep()";
BA_ "GenNWMApCanWakeUp" "apCanWakeUp()";
BA_ "GenNWMGotoMode_Awake" "Nmh_ReqNetOn()";
BA_ "GenNWMGotoMode_BusSleep" "Nmh_ReqNetOff()";
BA_ "GenNWMSleepTime" 4000;
BA_ "GenNWMTalkNM" "Nmh_ReqNetOn()";
BA_ "Manufacturer" "VAG";
BA_ "NmhBaseAddress" 452984832;
BA_ "NmhMessageCount" 1024;
BA_ "NmType" "NM-High";
BA_ "VAGTP20_SetupMessageCount" 128;
BA_ "VAGTP20_SetupStartAddress" 512;
BA_ "VersionNumber" 403;
BA_ "BusType" "CAN FD";
BA_ "NmhTimeoutTimer" 1000;
BA_ "NmhWaitBusSleepTimer" 750;
BA_ "NmhPrepareBusSleepTimer" 500;
BA_ "NmhLongTimer" 200;
BA_ "NmhNStart" 20;
BA_ "GenNodSleepTime" BU_ Airbag 4000;
BA_ "NodeLayerModules" BU_ Airbag "NMHigh.DLL";
BA_ "SamplePointMin" BU_ Airbag 80.000000;
BA_ "SamplePointMax" BU_ Airbag 80.000000;
BA_ "SyncJumpWidthMin" BU_ Airbag 16.000000;
BA_ "SyncJumpWidthMax" BU_ Airbag 16.000000;
BA_ "SyncJumpWidthCANFDMin" BU_ Airbag 6.000000;
BA_ "SyncJumpWidthCANFDMax" BU_ Airbag 6.000000;
BA_ "SamplePointCANFDMin" BU_ Airbag 70.000000;
BA_ "SamplePointCANFDMax" BU_ Airbag 70.000000;
BA_ "SSPOffsetCANFDMin" BU_ Airbag 70.000000;
BA_ "SSPOffsetCANFDMax" BU_ Airbag 70.000000;
BA_ "TimeQuantaMin" BU_ Airbag 80;
BA_ "TimeQuantaMax" BU_ Airbag 80;
BA_ "TimeQuantaCANFDMin" BU_ Airbag 20;
BA_ "TimeQuantaCANFDMax" BU_ Airbag 20;
BA_ "GenNodSleepTime" BU_ BAP_Tester 4000;
BA_ "ECUVariantGroup" BU_ BAP_Tester "BAP";
BA_ "NmhNode" BU_ BAP_Tester "No";
BA_ "SamplePointMin" BU_ BAP_Tester 80.000000;
BA_ "SamplePointMax" BU_ BAP_Tester 80.000000;
BA_ "SyncJumpWidthMin" BU_ BAP_Tester 16.000000;
BA_ "SyncJumpWidthMax" BU_ BAP_Tester 16.000000;
BA_ "SyncJumpWidthCANFDMin" BU_ BAP_Tester 6.000000;
BA_ "SyncJumpWidthCANFDMax" BU_ BAP_Tester 6.000000;
BA_ "SamplePointCANFDMin" BU_ BAP_Tester 70.000000;
BA_ "SamplePointCANFDMax" BU_ BAP_Tester 70.000000;
BA_ "SSPOffsetCANFDMin" BU_ BAP_Tester 70.000000;
BA_ "SSPOffsetCANFDMax" BU_ BAP_Tester 70.000000;
BA_ "TimeQuantaMin" BU_ BAP_Tester 80;
BA_ "TimeQuantaMax" BU_ BAP_Tester 80;
BA_ "TimeQuantaCANFDMin" BU_ BAP_Tester 20;
BA_ "TimeQuantaCANFDMax" BU_ BAP_Tester 20;
BA_ "GenNodSleepTime" BU_ ICAS1_Gateway 4000;
BA_ "ECUVariantGroup" BU_ ICAS1_Gateway "Gateway";
BA_ "NodeLayerModules" BU_ ICAS1_Gateway "NMHigh.DLL";
BA_ "SamplePointMin" BU_ ICAS1_Gateway 80.000000;
BA_ "SamplePointMax" BU_ ICAS1_Gateway 80.000000;
BA_ "SyncJumpWidthMin" BU_ ICAS1_Gateway 16.000000;
BA_ "SyncJumpWidthMax" BU_ ICAS1_Gateway 16.000000;
BA_ "SyncJumpWidthCANFDMin" BU_ ICAS1_Gateway 6.000000;
BA_ "SyncJumpWidthCANFDMax" BU_ ICAS1_Gateway 6.000000;
BA_ "SamplePointCANFDMin" BU_ ICAS1_Gateway 70.000000;
BA_ "SamplePointCANFDMax" BU_ ICAS1_Gateway 70.000000;
BA_ "SSPOffsetCANFDMin" BU_ ICAS1_Gateway 70.000000;
BA_ "SSPOffsetCANFDMax" BU_ ICAS1_Gateway 70.000000;
BA_ "TimeQuantaMin" BU_ ICAS1_Gateway 80;
BA_ "TimeQuantaMax" BU_ ICAS1_Gateway 80;
BA_ "TimeQuantaCANFDMin" BU_ ICAS1_Gateway 20;
BA_ "TimeQuantaCANFDMax" BU_ ICAS1_Gateway 20;
BA_ "GenNodSleepTime" BU_ ICAS1_KommunikationsServer 4000;
BA_ "NmhNode" BU_ ICAS1_KommunikationsServer "No";
BA_ "SamplePointMin" BU_ ICAS1_KommunikationsServer 80.000000;
BA_ "SamplePointMax" BU_ ICAS1_KommunikationsServer 80.000000;
BA_ "SyncJumpWidthMin" BU_ ICAS1_KommunikationsServer 16.000000;
BA_ "SyncJumpWidthMax" BU_ ICAS1_KommunikationsServer 16.000000;
BA_ "SyncJumpWidthCANFDMin" BU_ ICAS1_KommunikationsServer 6.000000;
BA_ "SyncJumpWidthCANFDMax" BU_ ICAS1_KommunikationsServer 6.000000;
BA_ "SamplePointCANFDMin" BU_ ICAS1_KommunikationsServer 70.000000;
BA_ "SamplePointCANFDMax" BU_ ICAS1_KommunikationsServer 70.000000;
BA_ "SSPOffsetCANFDMin" BU_ ICAS1_KommunikationsServer 70.000000;
BA_ "SSPOffsetCANFDMax" BU_ ICAS1_KommunikationsServer 70.000000;
BA_ "TimeQuantaMin" BU_ ICAS1_KommunikationsServer 80;
BA_ "TimeQuantaMax" BU_ ICAS1_KommunikationsServer 80;
BA_ "TimeQuantaCANFDMin" BU_ ICAS1_KommunikationsServer 20;
BA_ "TimeQuantaCANFDMax" BU_ ICAS1_KommunikationsServer 20;
BA_ "GenNodSleepTime" BU_ LE1 4000;
BA_ "ECUVariantDefault" BU_ LE1 "No";
BA_ "ECUVariantGroup" BU_ LE1 "EMotor";
BA_ "NodeLayerModules" BU_ LE1 "NMHigh.DLL";
BA_ "SamplePointMin" BU_ LE1 80.000000;
BA_ "SamplePointMax" BU_ LE1 80.000000;
BA_ "SyncJumpWidthMin" BU_ LE1 16.000000;
BA_ "SyncJumpWidthMax" BU_ LE1 16.000000;
BA_ "SyncJumpWidthCANFDMin" BU_ LE1 6.000000;
BA_ "SyncJumpWidthCANFDMax" BU_ LE1 6.000000;
BA_ "SamplePointCANFDMin" BU_ LE1 70.000000;
BA_ "SamplePointCANFDMax" BU_ LE1 70.000000;
BA_ "SSPOffsetCANFDMin" BU_ LE1 70.000000;
BA_ "SSPOffsetCANFDMax" BU_ LE1 70.000000;
BA_ "TimeQuantaMin" BU_ LE1 80;
BA_ "TimeQuantaMax" BU_ LE1 80;
BA_ "TimeQuantaCANFDMin" BU_ LE1 20;
BA_ "TimeQuantaCANFDMax" BU_ LE1 20;
BA_ "GenNodSleepTime" BU_ LE2 4000;
BA_ "NodeLayerModules" BU_ LE2 "NMHigh.DLL";
BA_ "SamplePointMin" BU_ LE2 80.000000;
BA_ "SamplePointMax" BU_ LE2 80.000000;
BA_ "SyncJumpWidthMin" BU_ LE2 16.000000;
BA_ "SyncJumpWidthMax" BU_ LE2 16.000000;
BA_ "SyncJumpWidthCANFDMin" BU_ LE2 6.000000;
BA_ "SyncJumpWidthCANFDMax" BU_ LE2 6.000000;
BA_ "SamplePointCANFDMin" BU_ LE2 70.000000;
BA_ "SamplePointCANFDMax" BU_ LE2 70.000000;
BA_ "SSPOffsetCANFDMin" BU_ LE2 70.000000;
BA_ "SSPOffsetCANFDMax" BU_ LE2 70.000000;
BA_ "TimeQuantaMin" BU_ LE2 80;
BA_ "TimeQuantaMax" BU_ LE2 80;
BA_ "TimeQuantaCANFDMin" BU_ LE2 20;
BA_ "TimeQuantaCANFDMax" BU_ LE2 20;
BA_ "GenNodSleepTime" BU_ Motor_BEV 4000;
BA_ "ECUVariantGroup" BU_ Motor_BEV "Motor";
BA_ "NodeLayerModules" BU_ Motor_BEV "NMHigh.DLL";
BA_ "SamplePointMin" BU_ Motor_BEV 80.000000;
BA_ "SamplePointMax" BU_ Motor_BEV 80.000000;
BA_ "SyncJumpWidthMin" BU_ Motor_BEV 16.000000;
BA_ "SyncJumpWidthMax" BU_ Motor_BEV 16.000000;
BA_ "SyncJumpWidthCANFDMin" BU_ Motor_BEV 6.000000;
BA_ "SyncJumpWidthCANFDMax" BU_ Motor_BEV 6.000000;
BA_ "SamplePointCANFDMin" BU_ Motor_BEV 70.000000;
BA_ "SamplePointCANFDMax" BU_ Motor_BEV 70.000000;
BA_ "SSPOffsetCANFDMin" BU_ Motor_BEV 70.000000;
BA_ "SSPOffsetCANFDMax" BU_ Motor_BEV 70.000000;
BA_ "TimeQuantaMin" BU_ Motor_BEV 80;
BA_ "TimeQuantaMax" BU_ Motor_BEV 80;
BA_ "TimeQuantaCANFDMin" BU_ Motor_BEV 20;
BA_ "TimeQuantaCANFDMax" BU_ Motor_BEV 20;
BA_ "GenNodSleepTime" BU_ Schaltbetaetigung 4000;
BA_ "ECUVariantGroup" BU_ Schaltbetaetigung "Waehlhebel";
BA_ "NodeLayerModules" BU_ Schaltbetaetigung "NMHigh.DLL";
BA_ "SamplePointMin" BU_ Schaltbetaetigung 80.000000;
BA_ "SamplePointMax" BU_ Schaltbetaetigung 80.000000;
BA_ "SyncJumpWidthMin" BU_ Schaltbetaetigung 16.000000;
BA_ "SyncJumpWidthMax" BU_ Schaltbetaetigung 16.000000;
BA_ "SyncJumpWidthCANFDMin" BU_ Schaltbetaetigung 6.000000;
BA_ "SyncJumpWidthCANFDMax" BU_ Schaltbetaetigung 6.000000;
BA_ "SamplePointCANFDMin" BU_ Schaltbetaetigung 70.000000;
BA_ "SamplePointCANFDMax" BU_ Schaltbetaetigung 70.000000;
BA_ "SSPOffsetCANFDMin" BU_ Schaltbetaetigung 70.000000;
BA_ "SSPOffsetCANFDMax" BU_ Schaltbetaetigung 70.000000;
BA_ "TimeQuantaMin" BU_ Schaltbetaetigung 80;
BA_ "TimeQuantaMax" BU_ Schaltbetaetigung 80;
BA_ "TimeQuantaCANFDMin" BU_ Schaltbetaetigung 20;
BA_ "TimeQuantaCANFDMax" BU_ Schaltbetaetigung 20;
BA_ "GenMsgCycleTime" BO_ 333 20;
BA_ "GenMsgILSupport" BO_ 333 "Yes";
BA_ "GenMsgPDUConstants" BO_ 333 "0x1a,0x65,0x81,0x96,0xc0,0xdf,0x11,0x92,0xd3,0x61,0xc6,0x95,0x8c,0x29,0x21,0xb5";
BA_ "GenMsgSendType" BO_ 333 "Cyclic";
BA_ "VFrameFormat" BO_ 333 "StandardCAN_FD";
BA_ "GenMsgCycleTime" BO_ 2527679682 2000;
BA_ "GenMsgDelayTime" BO_ 2527679682 100;
BA_ "GenMsgILSupport" BO_ 2527679682 "Yes";
BA_ "GenMsgSendType" BO_ 2527679682 "Cyclic";
BA_ "VFrameFormat" BO_ 2527679682 "ExtendedCAN_FD";
BA_ "GenMsgChkConstant" BO_ 64 64;
BA_ "GenMsgCycleTime" BO_ 64 40;
BA_ "GenMsgCycleTimeFast" BO_ 64 10;
BA_ "GenMsgDelayTime" BO_ 64 10;
BA_ "GenMsgILSupport" BO_ 64 "Yes";
BA_ "GenMsgNrOfRepetition" BO_ 64 5;
BA_ "GenMsgPDUConstants" BO_ 64 "0x40,0x40,0x40,0x40,0x40,0x40,0x40,0x40,0x40,0x40,0x40,0x40,0x40,0x40,0x40,0x40";
BA_ "GenMsgSendType" BO_ 64 "Cyclic";
BA_ "CANFD_BRS" BO_ 64 "0";
BA_ "GenMsgChkConstant" BO_ 1312 68;
BA_ "GenMsgCycleTime" BO_ 1312 200;
BA_ "GenMsgDelayTime" BO_ 1312 20;
BA_ "GenMsgILSupport" BO_ 1312 "Yes";
BA_ "GenMsgPDUConstants" BO_ 1312 "0x44,0x44,0x44,0x44,0x44,0x44,0x44,0x44,0x44,0x44,0x44,0x44,0x44,0x44,0x44,0x44";
BA_ "GenMsgSendType" BO_ 1312 "Cyclic";
BA_ "CANFD_BRS" BO_ 1312 "0";
BA_ "GenMsgCycleTime" BO_ 65 1000;
BA_ "GenMsgCycleTimeFast" BO_ 65 10;
BA_ "GenMsgDelayTime" BO_ 65 10;
BA_ "GenMsgILSupport" BO_ 65 "Yes";
BA_ "GenMsgNrOfRepetition" BO_ 65 5;
BA_ "GenMsgPDUConstants" BO_ 65 "0x93,0xb0,0x9d,0xf1,0x09,0xe8,0x88,0x5e,0x36,0xfa,0xa8,0xa1,0x67,0x84,0xca,0x4f";
BA_ "GenMsgSendType" BO_ 65 "Cyclic";
BA_ "CANFD_BRS" BO_ 65 "0";
BA_ "GenMsgCycleTime" BO_ 1349 200;
BA_ "GenMsgDelayTime" BO_ 1349 40;
BA_ "GenMsgILSupport" BO_ 1349 "Yes";
BA_ "GenMsgSendType" BO_ 1349 "Cyclic";
BA_ "CANFD_BRS" BO_ 1349 "0";
BA_ "GenMsgCycleTime" BO_ 2527679722 200;
BA_ "GenMsgILSupport" BO_ 2527679722 "Yes";
BA_ "GenMsgSendType" BO_ 2527679722 "Cyclic";
BA_ "CANFD_BRS" BO_ 2527679722 "0";
BA_ "VFrameFormat" BO_ 2527679722 "ExtendedCAN";
BA_ "GenMsgCycleTime" BO_ 1633 100;
BA_ "GenMsgILSupport" BO_ 1633 "Yes";
BA_ "GenMsgSendType" BO_ 1633 "Cyclic";
BA_ "VFrameFormat" BO_ 1633 "StandardCAN_FD";
BA_ "GenMsgCycleTime" BO_ 345 100;
BA_ "GenMsgDelayTime" BO_ 345 10;
BA_ "GenMsgILSupport" BO_ 345 "Yes";
BA_ "GenMsgSendType" BO_ 345 "Cyclic";
BA_ "VFrameFormat" BO_ 345 "StandardCAN_FD";
BA_ "GenMsgCycleTime" BO_ 2589283607 200;
BA_ "GenMsgDelayTime" BO_ 2589283607 100;
BA_ "GenMsgILSupport" BO_ 2589283607 "Yes";
BA_ "GenMsgNrOfRepetition" BO_ 2589283607 5;
BA_ "GenMsgPDUConstants" BO_ 2589283607 "0xfb,0xee,0x5d,0x2d,0xfa,0x85,0x27,0xd4,0xc9,0xc4,0xa5,0x45,0x5f,0x76,0xa3,0x89";
BA_ "GenMsgSendType" BO_ 2589283607 "Cyclic";
BA_ "VFrameFormat" BO_ 2589283607 "ExtendedCAN_FD";
BA_ "GenMsgCycleTime" BO_ 219 1000;
BA_ "GenMsgCycleTimeFast" BO_ 219 20;
BA_ "GenMsgDelayTime" BO_ 219 20;
BA_ "GenMsgILSupport" BO_ 219 "Yes";
BA_ "GenMsgNrOfRepetition" BO_ 219 5;
BA_ "GenMsgPDUConstants" BO_ 219 "0x09,0xfa,0xca,0x8e,0x62,0xd5,0xd1,0xf0,0x31,0xa0,0xaf,0xda,0x4d,0x1a,0x0a,0x97";
BA_ "GenMsgSendType" BO_ 219 "Cyclic";
BA_ "VFrameFormat" BO_ 219 "StandardCAN_FD";
BA_ "MsgType" BO_ 2536767264 "BAP";
BA_ "VFrameFormat" BO_ 2536767264 "ExtendedCAN_FD";
BA_ "MsgType" BO_ 2536767280 "BAP";
BA_ "VFrameFormat" BO_ 2536767280 "ExtendedCAN_FD";
BA_ "GenMsgCycleTimeFast" BO_ 2536717313 80;
BA_ "GenMsgSendType" BO_ 2536717313 "IfActive";
BA_ "MsgType" BO_ 2536717313 "BAP";
BA_ "VFrameFormat" BO_ 2536717313 "ExtendedCAN_FD";
BA_ "GenMsgCycleTimeFast" BO_ 2536717314 80;
BA_ "GenMsgSendType" BO_ 2536717314 "IfActive";
BA_ "MsgType" BO_ 2536717314 "BAP";
BA_ "VFrameFormat" BO_ 2536717314 "ExtendedCAN_FD";
BA_ "GenMsgCycleTime" BO_ 2536717328 1000;
BA_ "GenMsgCycleTimeFast" BO_ 2536717328 50;
BA_ "GenMsgSendType" BO_ 2536717328 "IfActive";
BA_ "MsgType" BO_ 2536717328 "BAP";
BA_ "VFrameFormat" BO_ 2536717328 "ExtendedCAN_FD";
BA_ "GenMsgCycleTimeFast" BO_ 2536709120 80;
BA_ "GenMsgSendType" BO_ 2536709120 "IfActive";
BA_ "MsgType" BO_ 2536709120 "BAP";
BA_ "VFrameFormat" BO_ 2536709120 "ExtendedCAN_FD";
BA_ "GenMsgCycleTime" BO_ 2536709136 1000;
BA_ "GenMsgCycleTimeFast" BO_ 2536709136 50;
BA_ "GenMsgSendType" BO_ 2536709136 "IfActive";
BA_ "MsgType" BO_ 2536709136 "BAP";
BA_ "VFrameFormat" BO_ 2536709136 "ExtendedCAN_FD";
BA_ "GenMsgCycleTime" BO_ 869 50;
BA_ "GenMsgILSupport" BO_ 869 "Yes";
BA_ "GenMsgSendType" BO_ 869 "Cyclic";
BA_ "VFrameFormat" BO_ 869 "StandardCAN_FD";
BA_ "GenMsgCycleTime" BO_ 1442 500;
BA_ "GenMsgCycleTimeFast" BO_ 1442 100;
BA_ "GenMsgDelayTime" BO_ 1442 20;
BA_ "GenMsgILSupport" BO_ 1442 "Yes";
BA_ "GenMsgNrOfRepetition" BO_ 1442 5;
BA_ "GenMsgPDUConstants" BO_ 1442 "0xeb,0x4c,0x44,0xaf,0x21,0x8d,0x01,0x58,0xfa,0x93,0xdb,0x89,0x15,0x10,0x4a,0x61";
BA_ "GenMsgSendType" BO_ 1442 "Cyclic";
BA_ "VFrameFormat" BO_ 1442 "StandardCAN_FD";
BA_ "GenMsgCycleTime" BO_ 2527679654 200;
BA_ "GenMsgILSupport" BO_ 2527679654 "Yes";
BA_ "GenMsgPDUConstants" BO_ 2527679654 "0x79,0xb9,0x67,0xad,0xd5,0xf7,0x70,0xaa,0x44,0x61,0x5a,0xdc,0x26,0xb4,0xd2,0xc3";
BA_ "GenMsgSendType" BO_ 2527679654 "Cyclic";
BA_ "VFrameFormat" BO_ 2527679654 "ExtendedCAN_FD";
BA_ "GenMsgCycleTime" BO_ 207 10;
BA_ "GenMsgILSupport" BO_ 207 "Yes";
BA_ "GenMsgPDUConstants" BO_ 207 "0xee,0x80,0x6e,0x4e,0x29,0xc6,0x92,0xc0,0x65,0xaa,0x3a,0xa1,0x8f,0xcd,0xe6,0x90";
BA_ "GenMsgSendType" BO_ 207 "Cyclic";
BA_ "VFrameFormat" BO_ 207 "StandardCAN_FD";
BA_ "GenMsgCycleTime" BO_ 2463978704 100;
BA_ "GenMsgILSupport" BO_ 2463978704 "Yes";
BA_ "GenMsgSendType" BO_ 2463978704 "Cyclic";
BA_ "VFrameFormat" BO_ 2463978704 "ExtendedCAN_FD";
BA_ "GenMsgCycleTime" BO_ 2463978705 100;
BA_ "GenMsgILSupport" BO_ 2463978705 "Yes";
BA_ "GenMsgSendType" BO_ 2463978705 "Cyclic";
BA_ "VFrameFormat" BO_ 2463978705 "ExtendedCAN_FD";
BA_ "GenMsgCycleTime" BO_ 2589283664 500;
BA_ "GenMsgILSupport" BO_ 2589283664 "Yes";
BA_ "GenMsgSendType" BO_ 2589283664 "Cyclic";
BA_ "VFrameFormat" BO_ 2589283664 "ExtendedCAN_FD";
BA_ "GenMsgCycleTime" BO_ 2589283665 500;
BA_ "GenMsgILSupport" BO_ 2589283665 "Yes";
BA_ "GenMsgSendType" BO_ 2589283665 "Cyclic";
BA_ "VFrameFormat" BO_ 2589283665 "ExtendedCAN_FD";
BA_ "GenMsgCycleTime" BO_ 2589283760 1000;
BA_ "GenMsgILSupport" BO_ 2589283760 "Yes";
BA_ "GenMsgSendType" BO_ 2589283760 "Cyclic";
BA_ "VFrameFormat" BO_ 2589283760 "ExtendedCAN_FD";
BA_ "GenMsgCycleTime" BO_ 2463978646 1000;
BA_ "GenMsgDelayTime" BO_ 2463978646 50;
BA_ "GenMsgILSupport" BO_ 2463978646 "Yes";
BA_ "GenMsgSendType" BO_ 2463978646 "Cyclic";
BA_ "VFrameFormat" BO_ 2463978646 "ExtendedCAN_FD";
BA_ "GenSigSendType" SG_ 333 ACC_18_CRC "Cyclic";
BA_ "GenSigFuncType" SG_ 333 ACC_18_CRC "CRC-8";
BA_ "GenSigSwitchedByIgnition" SG_ 333 ACC_18_CRC "No";
BA_ "GenSigSendType" SG_ 333 ACC_18_BZ "Cyclic";
BA_ "GenSigFuncType" SG_ 333 ACC_18_BZ "MsgCounter";
BA_ "GenSigSwitchedByIgnition" SG_ 333 ACC_18_BZ "No";
BA_ "GenSigSendType" SG_ 333 ACC_limitierte_Anfahrdyn "Cyclic";
BA_ "GenSigSendType" SG_ 333 ACC_nachtr_Stopp_Anf "Cyclic";
BA_ "GenSigSwitchedByIgnition" SG_ 333 ACC_nachtr_Stopp_Anf "No";
BA_ "GenSigSendType" SG_ 333 ACC_DynErhoehung "Cyclic";
BA_ "GenSigSendType" SG_ 333 ACC_Freilaufstrategie_TSK "Cyclic";
BA_ "GenSigSendType" SG_ 333 ACC_zul_Regelabw_unten "Cyclic";
BA_ "GenSigSendType" SG_ 333 ACC_StartStopp_Info "Cyclic";
BA_ "GenSigSendType" SG_ 333 ACC_Sollbeschleunigung_02 "Cyclic";
BA_ "GenSigStartValue" SG_ 333 ACC_Sollbeschleunigung_02 2046;
BA_ "Fehlerwert" SG_ 333 ACC_Sollbeschleunigung_02 2047;
BA_ "GenSigSendType" SG_ 333 ACC_zul_Regelabw_oben "Cyclic";
BA_ "GenSigSendType" SG_ 333 ACC_neg_Sollbeschl_Grad_02 "Cyclic";
BA_ "GenSigSendType" SG_ 333 ACC_pos_Sollbeschl_Grad_02 "Cyclic";
BA_ "GenSigSendType" SG_ 333 ACC_Anfahren "Cyclic";
BA_ "GenSigSendType" SG_ 333 ACC_Anhalten "Cyclic";
BA_ "GenSigSendType" SG_ 333 ACC_Typ "Cyclic";
BA_ "GenSigFuncType" SG_ 333 ACC_Typ "Constant";
BA_ "GenSigSendType" SG_ 333 ACC_Status_ACC "Cyclic";
BA_ "GenSigSendType" SG_ 333 ACC_Minimale_Bremsung "Cyclic";
BA_ "GenSigSendType" SG_ 333 ACC_Anhalteweg "Cyclic";
BA_ "GenSigStartValue" SG_ 333 ACC_Anhalteweg 2046;
BA_ "Fehlerwert" SG_ 333 ACC_Anhalteweg 2047;
BA_ "GenSigSendType" SG_ 333 ACC_Boost "Cyclic";
BA_ "GenSigSendType" SG_ 333 ACC_Freilauf_Anf "Cyclic";
BA_ "GenSigSendType" SG_ 333 ACC_Anforderung_HMS "Cyclic";
BA_ "GenSigSendType" SG_ 333 ACC_Folgebeschl "Cyclic";
BA_ "GenSigStartValue" SG_ 333 ACC_Folgebeschl 254;
BA_ "GenSigSendType" SG_ 333 ACC_Freilauf_Info "Cyclic";
BA_ "GenSigSendType" SG_ 333 ACC_Tempolimitassistent_Ein "Cyclic";
BA_ "GenSigSendType" SG_ 333 ACC_FoD_Status "Cyclic";
BA_ "GenSigSendType" SG_ 333 vESC_Verz_Anf "Cyclic";
BA_ "GenSigStartValue" SG_ 333 vESC_Verz_Anf 9;
BA_ "Fehlerwert" SG_ 333 vESC_Verz_Anf 10;
BA_ "GenSigSendType" SG_ 333 RDR_v_ueber_Grund "Cyclic";
BA_ "GenSigStartValue" SG_ 333 RDR_v_ueber_Grund 4091;
BA_ "Fehlerwert" SG_ 333 RDR_v_ueber_Grund 4093;
BA_ "GenSigSendType" SG_ 333 RDR_v_ueber_Grund_Genauigkeit "Cyclic";
BA_ "GenSigStartValue" SG_ 333 RDR_v_ueber_Grund_Genauigkeit 62;
BA_ "Fehlerwert" SG_ 333 RDR_v_ueber_Grund_Genauigkeit 63;
BA_ "GenSigSendType" SG_ 333 RDR_v_ueber_Grund_Fahrtrichtung "Cyclic";
BA_ "GenSigStartValue" SG_ 333 RDR_v_ueber_Grund_Fahrtrichtung 2;
BA_ "GenSigSendType" SG_ 2527679682 ACC_ASM_Ereignis "OnChange";
BA_ "GenSigSendType" SG_ 2527679682 ACC_ASM_Zeitstempel "OnChange";
BA_ "GenSigStartValue" SG_ 2527679682 ACC_ASM_Zeitstempel 255;
BA_ "GenSigSendType" SG_ 2527679682 ACC_ASM_Data_1 "Cyclic";
BA_ "GenSigSendType" SG_ 2527679682 ACC_ASM_Data_2 "Cyclic";
BA_ "GenSigSendType" SG_ 2527679682 ACC_ASM_Data_3 "Cyclic";
BA_ "GenSigSendType" SG_ 2527679682 ACC_ASM_Data_4 "Cyclic";
BA_ "GenSigSendType" SG_ 2527679682 ACC_ASM_Data_5 "Cyclic";
BA_ "GenSigSendType" SG_ 2527679682 ACC_ASM_Data_6 "Cyclic";
BA_ "GenSigSendType" SG_ 64 Airbag_01_CRC "Cyclic";
BA_ "GenSigFuncType" SG_ 64 Airbag_01_CRC "CRC-8";
BA_ "GenSigSwitchedByIgnition" SG_ 64 Airbag_01_CRC "No";
BA_ "GenSigSendType" SG_ 64 Airbag_01_BZ "Cyclic";
BA_ "GenSigFuncType" SG_ 64 Airbag_01_BZ "MsgCounter";
BA_ "GenSigSwitchedByIgnition" SG_ 64 Airbag_01_BZ "No";
BA_ "GenSigSendType" SG_ 64 AB_RGS_Anst "OnChange";
BA_ "GenSigStartValue" SG_ 64 AB_RGS_Anst 8;
BA_ "GenSigSwitchedByIgnition" SG_ 64 AB_RGS_Anst "No";
BA_ "GenSigSendType" SG_ 64 AB_Front_Crash "OnChangeWithRepetition";
BA_ "GenSigSwitchedByIgnition" SG_ 64 AB_Front_Crash "No";
BA_ "GenSigSendType" SG_ 64 AB_Heck_Crash "OnChangeWithRepetition";
BA_ "GenSigSwitchedByIgnition" SG_ 64 AB_Heck_Crash "No";
BA_ "GenSigSendType" SG_ 64 AB_SF_Crash "OnChangeWithRepetition";
BA_ "GenSigSwitchedByIgnition" SG_ 64 AB_SF_Crash "No";
BA_ "GenSigSendType" SG_ 64 AB_SB_Crash "OnChangeWithRepetition";
BA_ "GenSigSwitchedByIgnition" SG_ 64 AB_SB_Crash "No";
BA_ "GenSigSendType" SG_ 64 AB_Rollover_Crash "OnChangeWithRepetition";
BA_ "GenSigSwitchedByIgnition" SG_ 64 AB_Rollover_Crash "No";
BA_ "GenSigSendType" SG_ 64 AB_Crash_Int "OnChangeWithRepetition";
BA_ "GenSigSwitchedByIgnition" SG_ 64 AB_Crash_Int "No";
BA_ "GenSigSendType" SG_ 64 AB_Lampe "Cyclic";
BA_ "GenSigStartValue" SG_ 64 AB_Lampe 1;
BA_ "GenSigSwitchedByIgnition" SG_ 64 AB_Lampe "No";
BA_ "GenSigSendType" SG_ 64 AB_Deaktiviert "Cyclic";
BA_ "GenSigSwitchedByIgnition" SG_ 64 AB_Deaktiviert "No";
BA_ "GenSigSendType" SG_ 64 AB_VB_deaktiviert "Cyclic";
BA_ "GenSigStartValue" SG_ 64 AB_VB_deaktiviert 1;
BA_ "GenSigSwitchedByIgnition" SG_ 64 AB_VB_deaktiviert "No";
BA_ "GenSigSendType" SG_ 64 AB_Systemfehler "Cyclic";
BA_ "GenSigSwitchedByIgnition" SG_ 64 AB_Systemfehler "No";
BA_ "GenSigSendType" SG_ 64 AB_Diagnose "Cyclic";
BA_ "GenSigSwitchedByIgnition" SG_ 64 AB_Diagnose "No";
BA_ "GenSigSendType" SG_ 64 AB_Stellgliedtest "Cyclic";
BA_ "GenSigSwitchedByIgnition" SG_ 64 AB_Stellgliedtest "No";
BA_ "GenSigSendType" SG_ 64 AB_Erh_Auf_VB "Cyclic";
BA_ "GenSigSwitchedByIgnition" SG_ 64 AB_Erh_Auf_VB "No";
BA_ "GenSigSendType" SG_ 64 AB_Gurtwarn_VF "Cyclic";
BA_ "GenSigSwitchedByIgnition" SG_ 64 AB_Gurtwarn_VF "No";
BA_ "GenSigSendType" SG_ 64 AB_Gurtwarn_VB "Cyclic";
BA_ "GenSigSwitchedByIgnition" SG_ 64 AB_Gurtwarn_VB "No";
BA_ "GenSigSendType" SG_ 64 AB_Anzeige_Fussg "Cyclic";
BA_ "GenSigSwitchedByIgnition" SG_ 64 AB_Anzeige_Fussg "No";
BA_ "GenSigSendType" SG_ 64 AB_Texte_AKS "Cyclic";
BA_ "GenSigSwitchedByIgnition" SG_ 64 AB_Texte_AKS "No";
BA_ "GenSigSendType" SG_ 64 AB_PAO_Leuchte_Anf "Cyclic";
BA_ "GenSigStartValue" SG_ 64 AB_PAO_Leuchte_Anf 1;
BA_ "GenSigSwitchedByIgnition" SG_ 64 AB_PAO_Leuchte_Anf "No";
BA_ "GenSigSendType" SG_ 64 AB_MKB_gueltig "Cyclic";
BA_ "GenSigSwitchedByIgnition" SG_ 64 AB_MKB_gueltig "No";
BA_ "GenSigSendType" SG_ 64 AB_MKB_Anforderung "OnChangeWithRepetition";
BA_ "GenSigSwitchedByIgnition" SG_ 64 AB_MKB_Anforderung "No";
BA_ "GenSigSendType" SG_ 64 AB_Versorgungsspannung "Cyclic";
BA_ "GenSigSwitchedByIgnition" SG_ 64 AB_Versorgungsspannung "No";
BA_ "GenSigSendType" SG_ 64 AB_Deaktivierung_HV "OnChangeWithRepetition";
BA_ "GenSigSwitchedByIgnition" SG_ 64 AB_Deaktivierung_HV "No";
BA_ "Fehlerwert" SG_ 64 AB_Deaktivierung_HV 7;
BA_ "GenSigSendType" SG_ 64 AB_EDR_Trigger "OnChange";
BA_ "GenSigSwitchedByIgnition" SG_ 64 AB_EDR_Trigger "No";
BA_ "GenSigSendType" SG_ 64 AB_Belegung_VF "Cyclic";
BA_ "GenSigSwitchedByIgnition" SG_ 64 AB_Belegung_VF "No";
BA_ "Fehlerwert" SG_ 64 AB_Belegung_VF 1;
BA_ "GenSigSendType" SG_ 64 AB_Gurtschloss_FA_ext "OnChange";
BA_ "GenSigStartValue" SG_ 64 AB_Gurtschloss_FA_ext 6;
BA_ "GenSigSwitchedByIgnition" SG_ 64 AB_Gurtschloss_FA_ext "No";
BA_ "Fehlerwert" SG_ 64 AB_Gurtschloss_FA_ext 7;
BA_ "GenSigSendType" SG_ 64 AB_Belegung_VF_ext "OnChange";
BA_ "GenSigStartValue" SG_ 64 AB_Belegung_VF_ext 6;
BA_ "GenSigSwitchedByIgnition" SG_ 64 AB_Belegung_VF_ext "No";
BA_ "Fehlerwert" SG_ 64 AB_Belegung_VF_ext 7;
BA_ "GenSigSendType" SG_ 64 ASM_Masterzeit "Cyclic";
BA_ "GenSigStartValue" SG_ 64 ASM_Masterzeit 255;
BA_ "GenSigSwitchedByIgnition" SG_ 64 ASM_Masterzeit "No";
BA_ "GenSigSendType" SG_ 1312 Airbag_02_CRC "Cyclic";
BA_ "GenSigFuncType" SG_ 1312 Airbag_02_CRC "CRC-8";
BA_ "GenSigSwitchedByIgnition" SG_ 1312 Airbag_02_CRC "No";
BA_ "GenSigSendType" SG_ 1312 Airbag_02_BZ "Cyclic";
BA_ "GenSigFuncType" SG_ 1312 Airbag_02_BZ "MsgCounter";
BA_ "GenSigSwitchedByIgnition" SG_ 1312 Airbag_02_BZ "No";
BA_ "GenSigSendType" SG_ 1312 LoGeWa_Event_Kombiwarnung "OnChange";
BA_ "GenSigSwitchedByIgnition" SG_ 1312 LoGeWa_Event_Kombiwarnung "No";
BA_ "GenSigSendType" SG_ 1312 AB_Anforderung_eCall "Cyclic";
BA_ "GenSigSwitchedByIgnition" SG_ 1312 AB_Anforderung_eCall "No";
BA_ "GenSigSendType" SG_ 1312 AB_Anprall_Seite_Beifahrer "OnChange";
BA_ "GenSigSendType" SG_ 1312 AB_Anprall_Rollover "OnChange";
BA_ "GenSigSendType" SG_ 1312 AB_Anprall_FGS "OnChange";
BA_ "GenSigSendType" SG_ 1312 AB_Anprall_Front_Beifahrer "OnChange";
BA_ "GenSigSendType" SG_ 1312 AB_Anprall_Front_Fahrer "OnChange";
BA_ "GenSigSendType" SG_ 1312 AB_Anprall_Heck_Beifahrer "OnChange";
BA_ "GenSigSendType" SG_ 1312 AB_Anprall_Heck_Fahrer "OnChange";
BA_ "GenSigSendType" SG_ 1312 AB_Wickelklappung_Reihe2_MI "OnChange";
BA_ "GenSigStartValue" SG_ 1312 AB_Wickelklappung_Reihe2_MI 1;
BA_ "GenSigSwitchedByIgnition" SG_ 1312 AB_Wickelklappung_Reihe2_MI "No";
BA_ "GenSigSendType" SG_ 1312 AB_Belegung_VB "Cyclic";
BA_ "GenSigSwitchedByIgnition" SG_ 1312 AB_Belegung_VB "No";
BA_ "Fehlerwert" SG_ 1312 AB_Belegung_VB 1;
BA_ "GenSigSendType" SG_ 1312 AB_Abschaltanf_SIH_BF "OnChange";
BA_ "GenSigSendType" SG_ 1312 AB_Anprall_Seite_Fahrer "OnChange";
BA_ "GenSigSendType" SG_ 1312 SC_PAO_Schriftzug_Anf "OnChange";
BA_ "GenSigSwitchedByIgnition" SG_ 1312 SC_PAO_Schriftzug_Anf "No";
BA_ "GenSigSendType" SG_ 1312 SC_PAO_ON_Anf "OnChange";
BA_ "GenSigSwitchedByIgnition" SG_ 1312 SC_PAO_ON_Anf "No";
BA_ "GenSigSendType" SG_ 1312 SC_PAO_OFF_Anf "OnChange";
BA_ "GenSigSwitchedByIgnition" SG_ 1312 SC_PAO_OFF_Anf "No";
BA_ "GenSigSendType" SG_ 1312 AB_Crashschwere "OnChange";
BA_ "GenSigSwitchedByIgnition" SG_ 1312 AB_Crashschwere "No";
BA_ "Fehlerwert" SG_ 1312 AB_Crashschwere 7;
BA_ "GenSigSendType" SG_ 1312 AB_Anforderung_USM "Cyclic";
BA_ "GenSigSwitchedByIgnition" SG_ 1312 AB_Anforderung_USM "No";
BA_ "GenSigSendType" SG_ 1312 AB_Gurtschloss_FA "OnChange";
BA_ "GenSigStartValue" SG_ 1312 AB_Gurtschloss_FA 1;
BA_ "GenSigSwitchedByIgnition" SG_ 1312 AB_Gurtschloss_FA "No";
BA_ "GenSigSendType" SG_ 1312 AB_Gurtschloss_BF "OnChange";
BA_ "GenSigStartValue" SG_ 1312 AB_Gurtschloss_BF 1;
BA_ "GenSigSwitchedByIgnition" SG_ 1312 AB_Gurtschloss_BF "No";
BA_ "GenSigSendType" SG_ 1312 AB_Gurtschloss_Reihe2_FA "OnChange";
BA_ "GenSigStartValue" SG_ 1312 AB_Gurtschloss_Reihe2_FA 1;
BA_ "GenSigSwitchedByIgnition" SG_ 1312 AB_Gurtschloss_Reihe2_FA "No";
BA_ "GenSigSendType" SG_ 1312 AB_Gurtschloss_Reihe2_MI "OnChange";
BA_ "GenSigStartValue" SG_ 1312 AB_Gurtschloss_Reihe2_MI 1;
BA_ "GenSigSwitchedByIgnition" SG_ 1312 AB_Gurtschloss_Reihe2_MI "No";
BA_ "GenSigSendType" SG_ 1312 AB_Gurtschloss_Reihe2_BF "OnChange";
BA_ "GenSigStartValue" SG_ 1312 AB_Gurtschloss_Reihe2_BF 1;
BA_ "GenSigSwitchedByIgnition" SG_ 1312 AB_Gurtschloss_Reihe2_BF "No";
BA_ "GenSigSendType" SG_ 1312 AB_Gurtschloss_Reihe3_FA "OnChange";
BA_ "GenSigStartValue" SG_ 1312 AB_Gurtschloss_Reihe3_FA 1;
BA_ "GenSigSwitchedByIgnition" SG_ 1312 AB_Gurtschloss_Reihe3_FA "No";
BA_ "GenSigSendType" SG_ 1312 AB_Gurtschloss_Reihe3_MI "OnChange";
BA_ "GenSigStartValue" SG_ 1312 AB_Gurtschloss_Reihe3_MI 1;
BA_ "GenSigSwitchedByIgnition" SG_ 1312 AB_Gurtschloss_Reihe3_MI "No";
BA_ "GenSigSendType" SG_ 1312 AB_Gurtschloss_Reihe3_BF "OnChange";
BA_ "GenSigStartValue" SG_ 1312 AB_Gurtschloss_Reihe3_BF 1;
BA_ "GenSigSwitchedByIgnition" SG_ 1312 AB_Gurtschloss_Reihe3_BF "No";
BA_ "GenSigSendType" SG_ 1312 AB_Sitzpos_Sens_FA "Cyclic";
BA_ "GenSigSwitchedByIgnition" SG_ 1312 AB_Sitzpos_Sens_FA "No";
BA_ "Fehlerwert" SG_ 1312 AB_Sitzpos_Sens_FA 1;
BA_ "GenSigSendType" SG_ 1312 AB_Sitzpos_Sens_BF "Cyclic";
BA_ "GenSigSwitchedByIgnition" SG_ 1312 AB_Sitzpos_Sens_BF "No";
BA_ "Fehlerwert" SG_ 1312 AB_Sitzpos_Sens_BF 1;
BA_ "GenSigSendType" SG_ 1312 AB_Wickelklappung_Reihe2_BF "OnChange";
BA_ "GenSigStartValue" SG_ 1312 AB_Wickelklappung_Reihe2_BF 1;
BA_ "GenSigSwitchedByIgnition" SG_ 1312 AB_Wickelklappung_Reihe2_BF "No";
BA_ "GenSigSendType" SG_ 1312 AB_Wickelklappung_Reihe2_FA "OnChange";
BA_ "GenSigStartValue" SG_ 1312 AB_Wickelklappung_Reihe2_FA 1;
BA_ "GenSigSwitchedByIgnition" SG_ 1312 AB_Wickelklappung_Reihe2_FA "No";
BA_ "GenSigSendType" SG_ 65 Airbag_03_CRC "Cyclic";
BA_ "GenSigFuncType" SG_ 65 Airbag_03_CRC "CRC-8";
BA_ "GenSigSwitchedByIgnition" SG_ 65 Airbag_03_CRC "No";
BA_ "GenSigSendType" SG_ 65 Airbag_03_BZ "Cyclic";
BA_ "GenSigFuncType" SG_ 65 Airbag_03_BZ "MsgCounter";
BA_ "GenSigSwitchedByIgnition" SG_ 65 Airbag_03_BZ "No";
BA_ "GenSigSendType" SG_ 65 AB_MKB_Safing "OnChangeWithRepetition";
BA_ "GenSigSwitchedByIgnition" SG_ 65 AB_MKB_Safing "No";
BA_ "GenSigSendType" SG_ 1349 AB_Gurtwarn_Reihe4_FA "Cyclic";
BA_ "GenSigSwitchedByIgnition" SG_ 1349 AB_Gurtwarn_Reihe4_FA "No";
BA_ "GenSigSendType" SG_ 1349 AB_Gurtwarn_Reihe4_BF "Cyclic";
BA_ "GenSigSwitchedByIgnition" SG_ 1349 AB_Gurtwarn_Reihe4_BF "No";
BA_ "GenSigSendType" SG_ 1349 AB_Gurtwarn_Reihe4_MI "Cyclic";
BA_ "GenSigSwitchedByIgnition" SG_ 1349 AB_Gurtwarn_Reihe4_MI "No";
BA_ "GenSigSendType" SG_ 1349 AB_Gurtwarn_Reihe2_FA "Cyclic";
BA_ "GenSigSwitchedByIgnition" SG_ 1349 AB_Gurtwarn_Reihe2_FA "No";
BA_ "GenSigSendType" SG_ 1349 AB_Gurtwarn_Reihe2_BF "Cyclic";
BA_ "GenSigSwitchedByIgnition" SG_ 1349 AB_Gurtwarn_Reihe2_BF "No";
BA_ "GenSigSendType" SG_ 1349 AbstWarn_MV_FAS_Fkt_Status "OnChange";
BA_ "GenSigSwitchedByIgnition" SG_ 1349 AbstWarn_MV_FAS_Fkt_Status "No";
BA_ "Fehlerwert" SG_ 1349 AbstWarn_MV_FAS_Fkt_Status 3;
BA_ "GenSigSendType" SG_ 1349 WarnBrems_Charisma_Status "Cyclic";
BA_ "GenSigSendType" SG_ 1349 WarnBrems_Charisma_FahrPr "Cyclic";
BA_ "GenSigSendType" SG_ 1349 AB_Gurtwarn_Reihe2_MI "Cyclic";
BA_ "GenSigSwitchedByIgnition" SG_ 1349 AB_Gurtwarn_Reihe2_MI "No";
BA_ "GenSigSendType" SG_ 1349 AB_Gurtwarn_Reihe3_FA "Cyclic";
BA_ "GenSigSwitchedByIgnition" SG_ 1349 AB_Gurtwarn_Reihe3_FA "No";
BA_ "GenSigSendType" SG_ 1349 AB_Gurtwarn_Reihe3_MI "Cyclic";
BA_ "GenSigSwitchedByIgnition" SG_ 1349 AB_Gurtwarn_Reihe3_MI "No";
BA_ "GenSigSendType" SG_ 1349 AB_Gurtwarn_Reihe3_BF "Cyclic";
BA_ "GenSigSwitchedByIgnition" SG_ 1349 AB_Gurtwarn_Reihe3_BF "No";
BA_ "GenSigSendType" SG_ 1349 LGI_FAS_Fkt_Status "OnChange";
BA_ "GenSigSwitchedByIgnition" SG_ 1349 LGI_FAS_Fkt_Status "No";
BA_ "Fehlerwert" SG_ 1349 LGI_FAS_Fkt_Status 3;
BA_ "GenSigSendType" SG_ 1349 PreCrash_FAS_Fkt_Status "OnChange";
BA_ "GenSigSwitchedByIgnition" SG_ 1349 PreCrash_FAS_Fkt_Status "No";
BA_ "Fehlerwert" SG_ 1349 PreCrash_FAS_Fkt_Status 3;
BA_ "GenSigSendType" SG_ 1349 AB_SBR_hinten_verbau "Cyclic";
BA_ "GenSigStartValue" SG_ 1349 AB_SBR_hinten_verbau 3;
BA_ "GenSigSwitchedByIgnition" SG_ 1349 AB_SBR_hinten_verbau "No";
BA_ "GenSigSendType" SG_ 1349 AWV_Einstellung_System_ASG "OnChange";
BA_ "GenSigSwitchedByIgnition" SG_ 1349 AWV_Einstellung_System_ASG "No";
BA_ "GenSigSendType" SG_ 1349 AWV_Einstellung_Warnung_ASG "OnChange";
BA_ "GenSigSwitchedByIgnition" SG_ 1349 AWV_Einstellung_Warnung_ASG "No";
BA_ "GenSigSendType" SG_ 1349 SC_PreSense_Modus_Warnung_NV "OnChange";
BA_ "GenSigSwitchedByIgnition" SG_ 1349 SC_PreSense_Modus_Warnung_NV "No";
BA_ "GenSigSendType" SG_ 1349 SC_PreSense_Modus_Warnung_MV "OnChange";
BA_ "GenSigSwitchedByIgnition" SG_ 1349 SC_PreSense_Modus_Warnung_MV "No";
BA_ "GenSigSendType" SG_ 1349 SC_PreSense_Modus_System_MV "OnChange";
BA_ "GenSigSwitchedByIgnition" SG_ 1349 SC_PreSense_Modus_System_MV "No";
BA_ "GenSigSendType" SG_ 1349 SC_PreSense_Modus_System_NV "OnChange";
BA_ "GenSigSwitchedByIgnition" SG_ 1349 SC_PreSense_Modus_System_NV "No";
BA_ "GenSigSendType" SG_ 1349 SC_PreSense_Modus_System_KAS "OnChange";
BA_ "GenSigSwitchedByIgnition" SG_ 1349 SC_PreSense_Modus_System_KAS "No";
BA_ "GenSigSendType" SG_ 2527679722 AB_Gurtschloss_Reihe4_FA "Cyclic";
BA_ "GenSigStartValue" SG_ 2527679722 AB_Gurtschloss_Reihe4_FA 1;
BA_ "GenSigSwitchedByIgnition" SG_ 2527679722 AB_Gurtschloss_Reihe4_FA "No";
BA_ "GenSigSendType" SG_ 2527679722 AB_Gurtschloss_Reihe4_BF "Cyclic";
BA_ "GenSigStartValue" SG_ 2527679722 AB_Gurtschloss_Reihe4_BF 1;
BA_ "GenSigSwitchedByIgnition" SG_ 2527679722 AB_Gurtschloss_Reihe4_BF "No";
BA_ "GenSigSendType" SG_ 2527679722 AB_Gurtschloss_Reihe4_MI "Cyclic";
BA_ "GenSigStartValue" SG_ 2527679722 AB_Gurtschloss_Reihe4_MI 1;
BA_ "GenSigSwitchedByIgnition" SG_ 2527679722 AB_Gurtschloss_Reihe4_MI "No";
BA_ "GenSigSendType" SG_ 1633 AAG_BZ "Cyclic";
BA_ "GenSigFuncType" SG_ 1633 AAG_BZ "MsgCounter";
BA_ "GenSigSwitchedByIgnition" SG_ 1633 AAG_BZ "No";
BA_ "GenSigSendType" SG_ 1633 AAG_AVS_Fehler_02_inv "Cyclic";
BA_ "GenSigStartValue" SG_ 1633 AAG_AVS_Fehler_02_inv 1;
BA_ "GenSigSwitchedByIgnition" SG_ 1633 AAG_AVS_Fehler_02_inv "No";
BA_ "GenSigSendType" SG_ 1633 AAG_Bremsl_durch_ECD "Cyclic";
BA_ "GenSigSwitchedByIgnition" SG_ 1633 AAG_Bremsl_durch_ECD "No";
BA_ "GenSigSendType" SG_ 1633 AAG_Anhaenger_abgesteckt "Cyclic";
BA_ "GenSigSwitchedByIgnition" SG_ 1633 AAG_Anhaenger_abgesteckt "No";
BA_ "GenSigSendType" SG_ 1633 AAG_NSL_aktiv "Cyclic";
BA_ "GenSigSwitchedByIgnition" SG_ 1633 AAG_NSL_aktiv "No";
BA_ "GenSigSendType" SG_ 1633 AAG_Anhaenger_erkannt "Cyclic";
BA_ "NWM-WakeupAllowed" SG_ 1633 AAG_Anhaenger_erkannt "Yes";
BA_ "GenSigSwitchedByIgnition" SG_ 1633 AAG_Anhaenger_erkannt "No";
BA_ "GenSigSendType" SG_ 1633 AAG_Blinker_H_aktiv "Cyclic";
BA_ "GenSigSwitchedByIgnition" SG_ 1633 AAG_Blinker_H_aktiv "No";
BA_ "GenSigSendType" SG_ 1633 AAG_Blinker_HL_def "Cyclic";
BA_ "GenSigSwitchedByIgnition" SG_ 1633 AAG_Blinker_HL_def "No";
BA_ "GenSigSendType" SG_ 1633 AAG_Blinker_HR_def "Cyclic";
BA_ "GenSigSwitchedByIgnition" SG_ 1633 AAG_Blinker_HR_def "No";
BA_ "GenSigSendType" SG_ 1633 AAG_Bremslicht_H_def "Cyclic";
BA_ "GenSigSwitchedByIgnition" SG_ 1633 AAG_Bremslicht_H_def "No";
BA_ "GenSigSendType" SG_ 1633 AAG_Schlusslicht_HL_def "Cyclic";
BA_ "GenSigSwitchedByIgnition" SG_ 1633 AAG_Schlusslicht_HL_def "No";
BA_ "GenSigSendType" SG_ 1633 AAG_Schlusslicht_HR_def "Cyclic";
BA_ "GenSigSwitchedByIgnition" SG_ 1633 AAG_Schlusslicht_HR_def "No";
BA_ "GenSigSendType" SG_ 1633 AAG_Bremslicht_Reku "Cyclic";
BA_ "GenSigSwitchedByIgnition" SG_ 1633 AAG_Bremslicht_Reku "No";
BA_ "GenSigSendType" SG_ 1633 AAG_AVS_Fehler_02 "Cyclic";
BA_ "GenSigSwitchedByIgnition" SG_ 1633 AAG_AVS_Fehler_02 "No";
BA_ "Fehlerwert" SG_ 1633 AAG_AVS_Fehler_02 1;
BA_ "GenSigSendType" SG_ 1633 AAG_LED_aktiv "Cyclic";
BA_ "GenSigSwitchedByIgnition" SG_ 1633 AAG_LED_aktiv "No";
BA_ "GenSigSendType" SG_ 1633 AAG_AVS_Stati "Cyclic";
BA_ "GenSigSwitchedByIgnition" SG_ 1633 AAG_AVS_Stati "No";
BA_ "GenSigSendType" SG_ 345 ARA_Anf_Meldungen "Cyclic";
BA_ "GenSigSendType" SG_ 345 ARA_Knickwinkel_konfidenz "Cyclic";
BA_ "GenSigStartValue" SG_ 345 ARA_Knickwinkel_konfidenz 126;
BA_ "Fehlerwert" SG_ 345 ARA_Knickwinkel_konfidenz 127;
BA_ "GenSigSendType" SG_ 345 ARA_Texte "Cyclic";
BA_ "Fehlerwert" SG_ 345 ARA_Texte 63;
BA_ "GenSigSendType" SG_ 345 ARA_Modus "Cyclic";
BA_ "GenSigSendType" SG_ 345 ARA_Aktiver_Grafikmodus "Cyclic";
BA_ "GenSigSendType" SG_ 345 ARA_Deaktivierung_sperren "OnChange";
BA_ "GenSigSendType" SG_ 345 ARA_Modus_Anf "Cyclic";
BA_ "GenSigSendType" SG_ 345 ARA_Bremsfuss "Cyclic";
BA_ "GenSigSendType" SG_ 345 ARA_Sensor_Aktivierung "OnChange";
BA_ "GenSigSendType" SG_ 345 ARA_Knickwinkel_Komfort "OnChange";
BA_ "GenSigStartValue" SG_ 345 ARA_Knickwinkel_Komfort 62;
BA_ "GenSigSendType" SG_ 345 ARA_Status "OnChange";
BA_ "GenSigStartValue" SG_ 345 ARA_Status 1;
BA_ "Fehlerwert" SG_ 345 ARA_Status 2;
BA_ "GenSigSendType" SG_ 345 ARA_Knickwinkel_Max "OnChange";
BA_ "GenSigStartValue" SG_ 345 ARA_Knickwinkel_Max 126;
BA_ "Fehlerwert" SG_ 345 ARA_Knickwinkel_Max 127;
BA_ "GenSigSendType" SG_ 345 ARA_Knickwinkel_Soll "OnChange";
BA_ "GenSigStartValue" SG_ 345 ARA_Knickwinkel_Soll 254;
BA_ "Fehlerwert" SG_ 345 ARA_Knickwinkel_Soll 255;
BA_ "GenSigSendType" SG_ 345 ARA_Knickwinkel_Ist "OnChange";
BA_ "GenSigStartValue" SG_ 345 ARA_Knickwinkel_Ist 254;
BA_ "Fehlerwert" SG_ 345 ARA_Knickwinkel_Ist 255;
BA_ "GenSigSendType" SG_ 2589283607 AWC_01_CRC "Cyclic";
BA_ "GenSigFuncType" SG_ 2589283607 AWC_01_CRC "CRC-8";
BA_ "GenSigSwitchedByIgnition" SG_ 2589283607 AWC_01_CRC "No";
BA_ "GenSigSendType" SG_ 2589283607 AWC_01_BZ "Cyclic";
BA_ "GenSigFuncType" SG_ 2589283607 AWC_01_BZ "MsgCounter";
BA_ "GenSigSwitchedByIgnition" SG_ 2589283607 AWC_01_BZ "No";
BA_ "GenSigSendType" SG_ 2589283607 AWC_Status_EoHVL "OnChangeWithRepetition";
BA_ "GenSigSwitchedByIgnition" SG_ 2589283607 AWC_Status_EoHVL "No";
BA_ "Fehlerwert" SG_ 2589283607 AWC_Status_EoHVL 3;
BA_ "GenSigSendType" SG_ 2589283607 AWC_Status_Spgfreiheit "OnChangeWithRepetition";
BA_ "GenSigSwitchedByIgnition" SG_ 2589283607 AWC_Status_Spgfreiheit "No";
BA_ "GenSigSendType" SG_ 2589283607 AWC_IstSpannung "Cyclic";
BA_ "GenSigStartValue" SG_ 2589283607 AWC_IstSpannung 1022;
BA_ "GenSigSwitchedByIgnition" SG_ 2589283607 AWC_IstSpannung "No";
BA_ "Fehlerwert" SG_ 2589283607 AWC_IstSpannung 1023;
BA_ "GenSigSendType" SG_ 2589283607 AWC_Fehlerstatus "OnChange";
BA_ "GenSigStartValue" SG_ 2589283607 AWC_Fehlerstatus 7;
BA_ "GenSigSwitchedByIgnition" SG_ 2589283607 AWC_Fehlerstatus "No";
BA_ "GenSigSendType" SG_ 2589283607 AWC_IstModus "OnChange";
BA_ "GenSigStartValue" SG_ 2589283607 AWC_IstModus 6;
BA_ "GenSigSwitchedByIgnition" SG_ 2589283607 AWC_IstModus "No";
BA_ "GenSigSendType" SG_ 2589283607 AWC_IstStrom "Cyclic";
BA_ "GenSigStartValue" SG_ 2589283607 AWC_IstStrom 510;
BA_ "GenSigSwitchedByIgnition" SG_ 2589283607 AWC_IstStrom "No";
BA_ "Fehlerwert" SG_ 2589283607 AWC_IstStrom 511;
BA_ "GenSigSendType" SG_ 2589283607 AWC_MaxLadLeistung "Cyclic";
BA_ "GenSigStartValue" SG_ 2589283607 AWC_MaxLadLeistung 510;
BA_ "GenSigSwitchedByIgnition" SG_ 2589283607 AWC_MaxLadLeistung "No";
BA_ "Fehlerwert" SG_ 2589283607 AWC_MaxLadLeistung 511;
BA_ "GenSigSendType" SG_ 219 AWV_03_CRC "Cyclic";
BA_ "GenSigFuncType" SG_ 219 AWV_03_CRC "CRC-8";
BA_ "GenSigSwitchedByIgnition" SG_ 219 AWV_03_CRC "No";
BA_ "GenSigSendType" SG_ 219 AWV_03_BZ "Cyclic";
BA_ "GenSigFuncType" SG_ 219 AWV_03_BZ "MsgCounter";
BA_ "GenSigSwitchedByIgnition" SG_ 219 AWV_03_BZ "No";
BA_ "GenSigSendType" SG_ 219 PCF_Freigabe "Cyclic";
BA_ "GenSigSendType" SG_ 219 SDF_PSF_Objektstatus "Cyclic";
BA_ "Fehlerwert" SG_ 219 SDF_PSF_Objektstatus 7;
BA_ "GenSigSendType" SG_ 219 SDF_PSF_CU_Status "Cyclic";
BA_ "GenSigSendType" SG_ 219 SDF_PSF_CW "Cyclic";
BA_ "GenSigStartValue" SG_ 219 SDF_PSF_CW 126;
BA_ "Fehlerwert" SG_ 219 SDF_PSF_CW 127;
BA_ "GenSigSendType" SG_ 219 SDF_PSF_Fahrer_aktiv "Cyclic";
BA_ "GenSigStartValue" SG_ 219 SDF_PSF_Fahrer_aktiv 1;
BA_ "GenSigSendType" SG_ 219 SDF_PSF_Guete "Cyclic";
BA_ "GenSigSendType" SG_ 219 SDF_PSF_Kollisionsueberdeckung "Cyclic";
BA_ "GenSigStartValue" SG_ 219 SDF_PSF_Kollisionsueberdeckung 30;
BA_ "Fehlerwert" SG_ 219 SDF_PSF_Kollisionsueberdeckung 31;
BA_ "GenSigSendType" SG_ 219 SDF_PSF_Time_To_Collision "Cyclic";
BA_ "GenSigStartValue" SG_ 219 SDF_PSF_Time_To_Collision 254;
BA_ "Fehlerwert" SG_ 219 SDF_PSF_Time_To_Collision 255;
BA_ "GenSigSendType" SG_ 219 SDF_PSF_v_rel "Cyclic";
BA_ "GenSigStartValue" SG_ 219 SDF_PSF_v_rel 254;
BA_ "Fehlerwert" SG_ 219 SDF_PSF_v_rel 255;
BA_ "GenSigSendType" SG_ 219 AWV_Eingriff_Sendeart "IfActiveWithRepetition";
BA_ "GenSigSendType" SG_ 219 AWV_Verz_Freigabe "Cyclic";
BA_ "GenSigSendType" SG_ 219 AWV_Verz_Anf "Cyclic";
BA_ "GenSigStartValue" SG_ 219 AWV_Verz_Anf 1023;
BA_ "GenSigSendType" SG_ 219 AWV_Anf_Prefill "Cyclic";
BA_ "GenSigSendType" SG_ 219 AWV_Ruckprofil "Cyclic";
BA_ "GenSigSendType" SG_ 219 AWV_Time_to_collision "Cyclic";
BA_ "GenSigStartValue" SG_ 219 AWV_Time_to_collision 255;
BA_ "GenSigSwitchedByIgnition" SG_ 219 AWV_Time_to_collision "No";
BA_ "GenSigSendType" SG_ 219 AWV_HBA_Param "Cyclic";
BA_ "GenSigSendType" SG_ 219 AWV_Verz_Anf_ASIL "Cyclic";
BA_ "GenSigSendType" SG_ 219 AWV_Time_to_brake "Cyclic";
BA_ "GenSigStartValue" SG_ 219 AWV_Time_to_brake 127;
BA_ "GenSigSendType" SG_ 219 AWV_Zielobjekttyp "Cyclic";
BA_ "GenSigStartValue" SG_ 219 AWV_Zielobjekttyp 15;
BA_ "GenSigSendType" SG_ 219 AWV_QFK_KruemmSoll "Cyclic";
BA_ "GenSigSendType" SG_ 219 AWV_QFK_KruemmSoll_VZ "Cyclic";
BA_ "GenSigSendType" SG_ 219 AWV_QFK_Spuerb "Cyclic";
BA_ "GenSigSendType" SG_ 219 AWV_QFK_AnfStat "Cyclic";
BA_ "GenSigStartValue" SG_ 219 AWV_QFK_AnfStat 1;
BA_ "GenSigSendType" SG_ 219 AWV_QFK_Signal1 "Cyclic";
BA_ "GenSigSendType" SG_ 219 AWV_QFK_Art1 "Cyclic";
BA_ "GenSigSendType" SG_ 219 AWV_QFK_Art2 "Cyclic";
BA_ "GenSigSendType" SG_ 219 AWV_QFK_Signal2 "Cyclic";
BA_ "GenSigSendType" SG_ 2536767264 BAP_Debug_Cmd "OnChange";
BA_ "GenSigSwitchedByIgnition" SG_ 2536767264 BAP_Debug_Cmd "No";
BA_ "GenSigSendType" SG_ 2536767280 BAP_Debug_Data "OnChange";
BA_ "GenSigSwitchedByIgnition" SG_ 2536767280 BAP_Debug_Data "No";
BA_ "GenSigSendType" SG_ 2536717313 BAP_EfficAssist_ASG_02_Header "OnChange";
BA_ "GenSigSwitchedByIgnition" SG_ 2536717313 BAP_EfficAssist_ASG_02_Header "No";
BA_ "GenSigSendType" SG_ 2536717314 BAP_EfficAssist_ASG_03_Header "OnChange";
BA_ "GenSigSwitchedByIgnition" SG_ 2536717314 BAP_EfficAssist_ASG_03_Header "No";
BA_ "GenSigSendType" SG_ 2536717328 BAP_EfficAssist_FSG_01_Header "OnChange";
BA_ "GenSigSwitchedByIgnition" SG_ 2536717328 BAP_EfficAssist_FSG_01_Header "No";
BA_ "GenSigSendType" SG_ 2536709120 BAP_Hybrid_ASG_01_Header "OnChange";
BA_ "GenSigSwitchedByIgnition" SG_ 2536709120 BAP_Hybrid_ASG_01_Header "No";
BA_ "GenSigSendType" SG_ 2536709136 BAP_Hybrid_FSG_01_Header "OnChange";
BA_ "GenSigSwitchedByIgnition" SG_ 2536709136 BAP_Hybrid_FSG_01_Header "No";
BA_ "GenSigSendType" SG_ 869 BEM_UBDM "Cyclic";
BA_ "GenSigSwitchedByIgnition" SG_ 869 BEM_UBDM "No";
BA_ "Fehlerwert" SG_ 869 BEM_UBDM 255;
BA_ "GenSigSendType" SG_ 869 NVEM_Ladefreigabe "Cyclic";
BA_ "GenSigSwitchedByIgnition" SG_ 869 NVEM_Ladefreigabe "No";
BA_ "GenSigSendType" SG_ 869 NVEM_FMAus_Info "Cyclic";
BA_ "GenSigStartValue" SG_ 869 NVEM_FMAus_Info 1;
BA_ "GenSigSwitchedByIgnition" SG_ 869 NVEM_FMAus_Info "No";
BA_ "GenSigSendType" SG_ 869 NVEM_PTC_Sollstufe "Cyclic";
BA_ "GenSigSwitchedByIgnition" SG_ 869 NVEM_PTC_Sollstufe "No";
BA_ "GenSigSendType" SG_ 869 NVEM_P_Generator_Status "Cyclic";
BA_ "GenSigSwitchedByIgnition" SG_ 869 NVEM_P_Generator_Status "No";
BA_ "GenSigSendType" SG_ 869 BEM_P_Generator "Cyclic";
BA_ "GenSigSwitchedByIgnition" SG_ 869 BEM_P_Generator "No";
BA_ "Fehlerwert" SG_ 869 BEM_P_Generator 255;
BA_ "GenSigSendType" SG_ 869 BEM_n_LLA "Cyclic";
BA_ "GenSigSwitchedByIgnition" SG_ 869 BEM_n_LLA "No";
BA_ "GenSigSendType" SG_ 869 BEM_01_Abschaltstufen "Cyclic";
BA_ "GenSigSwitchedByIgnition" SG_ 869 BEM_01_Abschaltstufen "No";
BA_ "GenSigSendType" SG_ 869 BEM_Anf_KL "Cyclic";
BA_ "GenSigSwitchedByIgnition" SG_ 869 BEM_Anf_KL "No";
BA_ "GenSigSendType" SG_ 869 BEM_StartStopp_Info "Cyclic";
BA_ "GenSigSwitchedByIgnition" SG_ 869 BEM_StartStopp_Info "No";
BA_ "GenSigSendType" SG_ 869 BEM_DFM "Cyclic";
BA_ "GenSigSwitchedByIgnition" SG_ 869 BEM_DFM "No";
BA_ "GenSigSendType" SG_ 869 BEM_EMLIN_ungueltig "Cyclic";
BA_ "GenSigSwitchedByIgnition" SG_ 869 BEM_EMLIN_ungueltig "No";
BA_ "GenSigSendType" SG_ 869 BEM_Batt_Ab "Cyclic";
BA_ "GenSigSwitchedByIgnition" SG_ 869 BEM_Batt_Ab "No";
BA_ "GenSigSendType" SG_ 869 NVEM_FMAus_I_Verbrauch "Cyclic";
BA_ "GenSigStartValue" SG_ 869 NVEM_FMAus_I_Verbrauch 30;
BA_ "GenSigSwitchedByIgnition" SG_ 869 NVEM_FMAus_I_Verbrauch "No";
BA_ "Fehlerwert" SG_ 869 NVEM_FMAus_I_Verbrauch 31;
BA_ "GenSigSendType" SG_ 869 NVEM_Freilauf_Info "Cyclic";
BA_ "GenSigSwitchedByIgnition" SG_ 869 NVEM_Freilauf_Info "No";
BA_ "GenSigSendType" SG_ 869 BEM_NV_NachladAnf "Cyclic";
BA_ "GenSigSwitchedByIgnition" SG_ 869 BEM_NV_NachladAnf "No";
BA_ "Fehlerwert" SG_ 869 BEM_NV_NachladAnf 3;
BA_ "GenSigSendType" SG_ 869 BEM_Segel_Info "Cyclic";
BA_ "GenSigSwitchedByIgnition" SG_ 869 BEM_Segel_Info "No";
BA_ "GenSigSendType" SG_ 869 BEM_HYB_DC_uSollLV "Cyclic";
BA_ "GenSigStartValue" SG_ 869 BEM_HYB_DC_uSollLV 37;
BA_ "GenSigSwitchedByIgnition" SG_ 869 BEM_HYB_DC_uSollLV "No";
BA_ "GenSigSendType" SG_ 869 BEM_HYB_DC_uMinLV "Cyclic";
BA_ "GenSigStartValue" SG_ 869 BEM_HYB_DC_uMinLV 254;
BA_ "GenSigSwitchedByIgnition" SG_ 869 BEM_HYB_DC_uMinLV "No";
BA_ "Fehlerwert" SG_ 869 BEM_HYB_DC_uMinLV 255;
BA_ "GenSigSendType" SG_ 1442 BMS_04_CRC "Cyclic";
BA_ "GenSigFuncType" SG_ 1442 BMS_04_CRC "CRC-8";
BA_ "GenSigSwitchedByIgnition" SG_ 1442 BMS_04_CRC "No";
BA_ "GenSigSendType" SG_ 1442 BMS_04_BZ "Cyclic";
BA_ "GenSigFuncType" SG_ 1442 BMS_04_BZ "MsgCounter";
BA_ "GenSigSwitchedByIgnition" SG_ 1442 BMS_04_BZ "No";
BA_ "GenSigSendType" SG_ 1442 BMS_Fehler_Pilot "Cyclic";
BA_ "GenSigSwitchedByIgnition" SG_ 1442 BMS_Fehler_Pilot "No";
BA_ "GenSigSendType" SG_ 1442 BMS_Status_ServiceDisconnect "Cyclic";
BA_ "GenSigSwitchedByIgnition" SG_ 1442 BMS_Status_ServiceDisconnect "No";
BA_ "GenSigSendType" SG_ 1442 BMS_Status_Spgfreiheit "Cyclic";
BA_ "GenSigSwitchedByIgnition" SG_ 1442 BMS_Status_Spgfreiheit "No";
BA_ "GenSigSendType" SG_ 1442 BMS_OBD_Lampe_Anf "Cyclic";
BA_ "GenSigSwitchedByIgnition" SG_ 1442 BMS_OBD_Lampe_Anf "No";
BA_ "GenSigSendType" SG_ 1442 BMS_Fehlerstatus "OnChange";
BA_ "GenSigStartValue" SG_ 1442 BMS_Fehlerstatus 7;
BA_ "GenSigSwitchedByIgnition" SG_ 1442 BMS_Fehlerstatus "No";
BA_ "GenSigSendType" SG_ 1442 BMS_Kapazitaet_02 "Cyclic";
BA_ "GenSigStartValue" SG_ 1442 BMS_Kapazitaet_02 2047;
BA_ "GenSigSwitchedByIgnition" SG_ 1442 BMS_Kapazitaet_02 "No";
BA_ "GenSigSendType" SG_ 1442 BMS_Fehlerlampe_Anf "Cyclic";
BA_ "GenSigSwitchedByIgnition" SG_ 1442 BMS_Fehlerlampe_Anf "No";
BA_ "GenSigSendType" SG_ 1442 BMS_Warnlampe_Anf "Cyclic";
BA_ "GenSigSwitchedByIgnition" SG_ 1442 BMS_Warnlampe_Anf "No";
BA_ "GenSigSendType" SG_ 1442 BMS_Kl30c_Status "OnChangeWithRepetition";
BA_ "GenSigSwitchedByIgnition" SG_ 1442 BMS_Kl30c_Status "No";
BA_ "Fehlerwert" SG_ 1442 BMS_Kl30c_Status 3;
BA_ "GenSigSendType" SG_ 2527679654 BMS_11_CRC "Cyclic";
BA_ "GenSigFuncType" SG_ 2527679654 BMS_11_CRC "CRC-8";
BA_ "GenSigSwitchedByIgnition" SG_ 2527679654 BMS_11_CRC "No";
BA_ "GenSigSendType" SG_ 2527679654 BMS_11_BZ "Cyclic";
BA_ "GenSigFuncType" SG_ 2527679654 BMS_11_BZ "MsgCounter";
BA_ "GenSigSwitchedByIgnition" SG_ 2527679654 BMS_11_BZ "No";
BA_ "GenSigSendType" SG_ 2527679654 BMS_IsoZustand "Cyclic";
BA_ "GenSigSwitchedByIgnition" SG_ 2527679654 BMS_IsoZustand "No";
BA_ "GenSigSendType" SG_ 2527679654 BMS_IsoFehler "Cyclic";
BA_ "GenSigSwitchedByIgnition" SG_ 2527679654 BMS_IsoFehler "No";
BA_ "GenSigSendType" SG_ 2527679654 BMS_IstTemperatur_hoechste "Cyclic";
BA_ "GenSigStartValue" SG_ 2527679654 BMS_IstTemperatur_hoechste 254;
BA_ "GenSigSwitchedByIgnition" SG_ 2527679654 BMS_IstTemperatur_hoechste "No";
BA_ "Fehlerwert" SG_ 2527679654 BMS_IstTemperatur_hoechste 255;
BA_ "GenSigSendType" SG_ 2527679654 BMS_IstTemperatur_niedrigste "Cyclic";
BA_ "GenSigStartValue" SG_ 2527679654 BMS_IstTemperatur_niedrigste 254;
BA_ "GenSigSwitchedByIgnition" SG_ 2527679654 BMS_IstTemperatur_niedrigste "No";
BA_ "Fehlerwert" SG_ 2527679654 BMS_IstTemperatur_niedrigste 255;
BA_ "GenSigSendType" SG_ 2527679654 BMS_IstZellspannung_hoechste "Cyclic";
BA_ "GenSigStartValue" SG_ 2527679654 BMS_IstZellspannung_hoechste 4094;
BA_ "GenSigSwitchedByIgnition" SG_ 2527679654 BMS_IstZellspannung_hoechste "No";
BA_ "Fehlerwert" SG_ 2527679654 BMS_IstZellspannung_hoechste 4095;
BA_ "GenSigSendType" SG_ 2527679654 BMS_IstZellspannung_niedrigste "Cyclic";
BA_ "GenSigStartValue" SG_ 2527679654 BMS_IstZellspannung_niedrigste 4094;
BA_ "GenSigSwitchedByIgnition" SG_ 2527679654 BMS_IstZellspannung_niedrigste "No";
BA_ "Fehlerwert" SG_ 2527679654 BMS_IstZellspannung_niedrigste 4095;
BA_ "GenSigSendType" SG_ 207 BMS_20_CRC "Cyclic";
BA_ "GenSigFuncType" SG_ 207 BMS_20_CRC "CRC-8";
BA_ "GenSigSwitchedByIgnition" SG_ 207 BMS_20_CRC "No";
BA_ "GenSigSendType" SG_ 207 BMS_20_BZ "Cyclic";
BA_ "GenSigFuncType" SG_ 207 BMS_20_BZ "MsgCounter";
BA_ "GenSigSwitchedByIgnition" SG_ 207 BMS_20_BZ "No";
BA_ "GenSigSendType" SG_ 207 BMS_Fehlerstatus_HV_Schuetze "Cyclic";
BA_ "GenSigSwitchedByIgnition" SG_ 207 BMS_Fehlerstatus_HV_Schuetze "No";
BA_ "GenSigSendType" SG_ 207 BMS_ErwGrenzen_aktiv "Cyclic";
BA_ "GenSigSwitchedByIgnition" SG_ 207 BMS_ErwGrenzen_aktiv "No";
BA_ "GenSigSendType" SG_ 207 BMS_IstModus "Cyclic";
BA_ "GenSigStartValue" SG_ 207 BMS_IstModus 7;
BA_ "GenSigSwitchedByIgnition" SG_ 207 BMS_IstModus "No";
BA_ "GenSigSendType" SG_ 207 BMS_HVIL_Status "Cyclic";
BA_ "GenSigSwitchedByIgnition" SG_ 207 BMS_HVIL_Status "No";
BA_ "Fehlerwert" SG_ 207 BMS_HVIL_Status 3;
BA_ "GenSigSendType" SG_ 207 BMS_Fehler_HVBattAbschaltung "Cyclic";
BA_ "GenSigSwitchedByIgnition" SG_ 207 BMS_Fehler_HVBattAbschaltung "No";
BA_ "GenSigSendType" SG_ 207 BMS_Fehler_HVBattAbschaltung_Anf "Cyclic";
BA_ "GenSigSwitchedByIgnition" SG_ 207 BMS_Fehler_HVBattAbschaltung_Anf "No";
BA_ "GenSigSendType" SG_ 207 BMS_Fehler_Leistungsred "Cyclic";
BA_ "GenSigSwitchedByIgnition" SG_ 207 BMS_Fehler_Leistungsred "No";
BA_ "GenSigSendType" SG_ 207 BMS_Strom "Cyclic";
BA_ "GenSigStartValue" SG_ 207 BMS_Strom 32766;
BA_ "GenSigSwitchedByIgnition" SG_ 207 BMS_Strom "No";
BA_ "Fehlerwert" SG_ 207 BMS_Strom 32767;
BA_ "GenSigSendType" SG_ 207 BMS_Fehler_Notabschaltung_Crash "Cyclic";
BA_ "GenSigSwitchedByIgnition" SG_ 207 BMS_Fehler_Notabschaltung_Crash "No";
BA_ "GenSigSendType" SG_ 207 BMS_Spannung_Zwischenkreis "Cyclic";
BA_ "GenSigStartValue" SG_ 207 BMS_Spannung_Zwischenkreis 4094;
BA_ "GenSigSwitchedByIgnition" SG_ 207 BMS_Spannung_Zwischenkreis "No";
BA_ "Fehlerwert" SG_ 207 BMS_Spannung_Zwischenkreis 4095;
BA_ "GenSigSendType" SG_ 207 BMS_Spannung "Cyclic";
BA_ "GenSigStartValue" SG_ 207 BMS_Spannung 4094;
BA_ "GenSigSwitchedByIgnition" SG_ 207 BMS_Spannung "No";
BA_ "Fehlerwert" SG_ 207 BMS_Spannung 4095;
BA_ "GenSigSendType" SG_ 2463978704 BMS_Max_Entladestrom "Cyclic";
BA_ "GenSigStartValue" SG_ 2463978704 BMS_Max_Entladestrom 8190;
BA_ "GenSigSwitchedByIgnition" SG_ 2463978704 BMS_Max_Entladestrom "No";
BA_ "GenSigSendType" SG_ 2463978704 BMS_Max_Ladestrom "Cyclic";
BA_ "GenSigStartValue" SG_ 2463978704 BMS_Max_Ladestrom 8190;
BA_ "GenSigSwitchedByIgnition" SG_ 2463978704 BMS_Max_Ladestrom "No";
BA_ "GenSigSendType" SG_ 2463978704 BMS_Max_Entladeleistung "Cyclic";
BA_ "GenSigStartValue" SG_ 2463978704 BMS_Max_Entladeleistung 8190;
BA_ "GenSigSwitchedByIgnition" SG_ 2463978704 BMS_Max_Entladeleistung "No";
BA_ "GenSigSendType" SG_ 2463978704 BMS_Max_Ladeleistung "Cyclic";
BA_ "GenSigStartValue" SG_ 2463978704 BMS_Max_Ladeleistung 8190;
BA_ "GenSigSwitchedByIgnition" SG_ 2463978704 BMS_Max_Ladeleistung "No";
BA_ "GenSigSendType" SG_ 2463978705 BMS_Status_EoHVL_Heizer "Cyclic";
BA_ "GenSigSwitchedByIgnition" SG_ 2463978705 BMS_Status_EoHVL_Heizer "No";
BA_ "Fehlerwert" SG_ 2463978705 BMS_Status_EoHVL_Heizer 3;
BA_ "GenSigSendType" SG_ 2463978705 BMS_Ladezustand "Cyclic";
BA_ "GenSigStartValue" SG_ 2463978705 BMS_Ladezustand 2046;
BA_ "GenSigSwitchedByIgnition" SG_ 2463978705 BMS_Ladezustand "No";
BA_ "Fehlerwert" SG_ 2463978705 BMS_Ladezustand 2047;
BA_ "GenSigSendType" SG_ 2463978705 BMS_PerfInd_Entladen "Cyclic";
BA_ "GenSigStartValue" SG_ 2463978705 BMS_PerfInd_Entladen 1022;
BA_ "GenSigSwitchedByIgnition" SG_ 2463978705 BMS_PerfInd_Entladen "No";
BA_ "GenSigSendType" SG_ 2463978705 BMS_PerfInd_Laden "Cyclic";
BA_ "GenSigStartValue" SG_ 2463978705 BMS_PerfInd_Laden 1022;
BA_ "GenSigSwitchedByIgnition" SG_ 2463978705 BMS_PerfInd_Laden "No";
BA_ "GenSigSendType" SG_ 2463978705 BMS_Nutzbare_EntladeEnergie "Cyclic";
BA_ "GenSigStartValue" SG_ 2463978705 BMS_Nutzbare_EntladeEnergie 65534;
BA_ "GenSigSwitchedByIgnition" SG_ 2463978705 BMS_Nutzbare_EntladeEnergie "No";
BA_ "Fehlerwert" SG_ 2463978705 BMS_Nutzbare_EntladeEnergie 65535;
BA_ "GenSigSendType" SG_ 2589283664 BMS_Balancing_Aktiv "Cyclic";
BA_ "GenSigSwitchedByIgnition" SG_ 2589283664 BMS_Balancing_Aktiv "No";
BA_ "GenSigSendType" SG_ 2589283664 BMS_Ladevorgang_aktiv "Cyclic";
BA_ "GenSigSwitchedByIgnition" SG_ 2589283664 BMS_Ladevorgang_aktiv "No";
BA_ "GenSigSendType" SG_ 2589283664 BMS_RIso_Ext "Cyclic";
BA_ "GenSigStartValue" SG_ 2589283664 BMS_RIso_Ext 4094;
BA_ "GenSigSwitchedByIgnition" SG_ 2589283664 BMS_RIso_Ext "No";
BA_ "Fehlerwert" SG_ 2589283664 BMS_RIso_Ext 4095;
BA_ "GenSigSendType" SG_ 2589283664 BMS_Min_Ladezustand "Cyclic";
BA_ "GenSigStartValue" SG_ 2589283664 BMS_Min_Ladezustand 2046;
BA_ "GenSigSwitchedByIgnition" SG_ 2589283664 BMS_Min_Ladezustand "No";
BA_ "GenSigSendType" SG_ 2589283664 BMS_Max_Energie "Cyclic";
BA_ "GenSigStartValue" SG_ 2589283664 BMS_Max_Energie 8190;
BA_ "GenSigSwitchedByIgnition" SG_ 2589283664 BMS_Max_Energie "No";
BA_ "GenSigSendType" SG_ 2589283664 BMS_Max_Ladezustand "Cyclic";
BA_ "GenSigStartValue" SG_ 2589283664 BMS_Max_Ladezustand 2046;
BA_ "GenSigSwitchedByIgnition" SG_ 2589283664 BMS_Max_Ladezustand "No";
BA_ "GenSigSendType" SG_ 2589283665 BMS_BattHeizung_VerbautStatus "Cyclic";
BA_ "GenSigSwitchedByIgnition" SG_ 2589283665 BMS_BattHeizung_VerbautStatus "No";
BA_ "GenSigSendType" SG_ 2589283665 BMS_Fehler_NTKreis "Cyclic";
BA_ "GenSigSwitchedByIgnition" SG_ 2589283665 BMS_Fehler_NTKreis "No";
BA_ "Fehlerwert" SG_ 2589283665 BMS_Fehler_NTKreis 1;
BA_ "GenSigSendType" SG_ 2589283665 BMS_Temperierung_Anf "Cyclic";
BA_ "GenSigStartValue" SG_ 2589283665 BMS_Temperierung_Anf 3;
BA_ "GenSigSwitchedByIgnition" SG_ 2589283665 BMS_Temperierung_Anf "No";
BA_ "GenSigSendType" SG_ 2589283665 BMS_Status_Ventil1 "Cyclic";
BA_ "GenSigStartValue" SG_ 2589283665 BMS_Status_Ventil1 6;
BA_ "GenSigSwitchedByIgnition" SG_ 2589283665 BMS_Status_Ventil1 "No";
BA_ "Fehlerwert" SG_ 2589283665 BMS_Status_Ventil1 7;
BA_ "GenSigSendType" SG_ 2589283665 BMS_Status_Ventil2 "Cyclic";
BA_ "GenSigStartValue" SG_ 2589283665 BMS_Status_Ventil2 6;
BA_ "GenSigSwitchedByIgnition" SG_ 2589283665 BMS_Status_Ventil2 "No";
BA_ "Fehlerwert" SG_ 2589283665 BMS_Status_Ventil2 7;
BA_ "GenSigSendType" SG_ 2589283665 BMS_Pumpe1_Ansteuerung "Cyclic";
BA_ "GenSigStartValue" SG_ 2589283665 BMS_Pumpe1_Ansteuerung 14;
BA_ "GenSigSwitchedByIgnition" SG_ 2589283665 BMS_Pumpe1_Ansteuerung "No";
BA_ "Fehlerwert" SG_ 2589283665 BMS_Pumpe1_Ansteuerung 15;
BA_ "GenSigSendType" SG_ 2589283665 BMS_Pumpe2_Ansteuerung "Cyclic";
BA_ "GenSigStartValue" SG_ 2589283665 BMS_Pumpe2_Ansteuerung 14;
BA_ "GenSigSwitchedByIgnition" SG_ 2589283665 BMS_Pumpe2_Ansteuerung "No";
BA_ "Fehlerwert" SG_ 2589283665 BMS_Pumpe2_Ansteuerung 15;
BA_ "GenSigSendType" SG_ 2589283665 BMS_VorlaufTemperatur "Cyclic";
BA_ "GenSigStartValue" SG_ 2589283665 BMS_VorlaufTemperatur 254;
BA_ "GenSigSwitchedByIgnition" SG_ 2589283665 BMS_VorlaufTemperatur "No";
BA_ "Fehlerwert" SG_ 2589283665 BMS_VorlaufTemperatur 255;
BA_ "GenSigSendType" SG_ 2589283665 BMS_Temperatur "Cyclic";
BA_ "GenSigStartValue" SG_ 2589283665 BMS_Temperatur 254;
BA_ "GenSigSwitchedByIgnition" SG_ 2589283665 BMS_Temperatur "No";
BA_ "Fehlerwert" SG_ 2589283665 BMS_Temperatur 255;
BA_ "GenSigSendType" SG_ 2589283665 BMS_SollVorlauftemperatur "Cyclic";
BA_ "GenSigStartValue" SG_ 2589283665 BMS_SollVorlauftemperatur 254;
BA_ "GenSigSwitchedByIgnition" SG_ 2589283665 BMS_SollVorlauftemperatur "No";
BA_ "Fehlerwert" SG_ 2589283665 BMS_SollVorlauftemperatur 255;
BA_ "GenSigSendType" SG_ 2589283665 BMS_RuecklaufTemperatur "Cyclic";
BA_ "GenSigStartValue" SG_ 2589283665 BMS_RuecklaufTemperatur 254;
BA_ "GenSigSwitchedByIgnition" SG_ 2589283665 BMS_RuecklaufTemperatur "No";
BA_ "Fehlerwert" SG_ 2589283665 BMS_RuecklaufTemperatur 255;
BA_ "GenSigSendType" SG_ 2589283760 BMS_Max_Spannung "Cyclic";
BA_ "GenSigStartValue" SG_ 2589283760 BMS_Max_Spannung 1022;
BA_ "GenSigSwitchedByIgnition" SG_ 2589283760 BMS_Max_Spannung "No";
BA_ "GenSigSendType" SG_ 2589283760 BMS_Min_Spannung "Cyclic";
BA_ "GenSigStartValue" SG_ 2589283760 BMS_Min_Spannung 1022;
BA_ "GenSigSwitchedByIgnition" SG_ 2589283760 BMS_Min_Spannung "No";
BA_ "GenSigSendType" SG_ 2589283760 BMS_Dauer_Entladeleistung "Cyclic";
BA_ "GenSigStartValue" SG_ 2589283760 BMS_Dauer_Entladeleistung 4094;
BA_ "GenSigSwitchedByIgnition" SG_ 2589283760 BMS_Dauer_Entladeleistung "No";
BA_ "GenSigSendType" SG_ 2589283760 BMS_Dauer_Ladeleistung "Cyclic";
BA_ "GenSigStartValue" SG_ 2589283760 BMS_Dauer_Ladeleistung 4094;
BA_ "GenSigSwitchedByIgnition" SG_ 2589283760 BMS_Dauer_Ladeleistung "No";
BA_ "GenSigSendType" SG_ 2463978646 CHA_Ziel_FahrPr_AGA "OnChange";
BA_ "GenSigSwitchedByIgnition" SG_ 2463978646 CHA_Ziel_FahrPr_AGA "No";
BA_ "GenSigSendType" SG_ 2463978646 CHA_Ziel_FahrPr_ESP "OnChange";
BA_ "GenSigSwitchedByIgnition" SG_ 2463978646 CHA_Ziel_FahrPr_ESP "No";
BA_ "GenSigSendType" SG_ 2463978646 CHA_Ziel_FahrPr_Freilauf "OnChange";
BA_ "GenSigSwitchedByIgnition" SG_ 2463978646 CHA_Ziel_FahrPr_Freilauf "No";
BA_ "GenSigSendType" SG_ 2463978646 CHA_Fahrer_Umschaltung "OnChange";
BA_ "GenSigSwitchedByIgnition" SG_ 2463978646 CHA_Fahrer_Umschaltung "No";
BA_ "GenSigSendType" SG_ 2463978646 CHA_Fahrer_Umschaltung_BMA "OnChange";
BA_ "GenSigSwitchedByIgnition" SG_ 2463978646 CHA_Fahrer_Umschaltung_BMA "No";
BA_ "GenSigSendType" SG_ 2463978646 CHA_Ziel_FahrPr_MO "OnChange";
BA_ "GenSigSwitchedByIgnition" SG_ 2463978646 CHA_Ziel_FahrPr_MO "No";
BA_ "GenSigSendType" SG_ 2463978646 CHA_Ziel_FahrPr_GE "OnChange";
BA_ "GenSigSwitchedByIgnition" SG_ 2463978646 CHA_Ziel_FahrPr_GE "No";
BA_ "GenSigSendType" SG_ 2463978646 CHA_Ziel_FahrPr_ALR "OnChange";
BA_ "GenSigSwitchedByIgnition" SG_ 2463978646 CHA_Ziel_FahrPr_ALR "No";
BA_ "GenSigSendType" SG_ 2463978646 CHA_Ziel_FahrPr_MO_BZS "OnChange";
BA_ "GenSigSwitchedByIgnition" SG_ 2463978646 CHA_Ziel_FahrPr_MO_BZS "No";
BA_ "GenSigSendType" SG_ 2463978646 CHA_Ziel_FahrPr_DR "OnChange";
BA_ "GenSigSwitchedByIgnition" SG_ 2463978646 CHA_Ziel_FahrPr_DR "No";
BA_ "GenSigSendType" SG_ 2463978646 CHA_Ziel_FahrPr_VAQ "OnChange";
BA_ "GenSigSwitchedByIgnition" SG_ 2463978646 CHA_Ziel_FahrPr_VAQ "No";
BA_ "GenSigSendType" SG_ 2463978646 CHA_Ziel_FahrPr_AFS "OnChange";
BA_ "GenSigSwitchedByIgnition" SG_ 2463978646 CHA_Ziel_FahrPr_AFS "No";
BA_ "GenSigSendType" SG_ 2463978646 CHA_Ziel_FahrPr_PreCrash "OnChange";
BA_ "GenSigSwitchedByIgnition" SG_ 2463978646 CHA_Ziel_FahrPr_PreCrash "No";
BA_ "GenSigSendType" SG_ 2463978646 CHA_Ziel_FahrPr_EPS "OnChange";
BA_ "GenSigSwitchedByIgnition" SG_ 2463978646 CHA_Ziel_FahrPr_EPS "No";
BA_ "GenSigSendType" SG_ 2463978646 CHA_Ziel_FahrPr_ACC "OnChange";
BA_ "GenSigSwitchedByIgnition" SG_ 2463978646 CHA_Ziel_FahrPr_ACC "No";
BA_ "GenSigSendType" SG_ 2463978646 CHA_Ziel_FahrPr_SAK "OnChange";
BA_ "GenSigSwitchedByIgnition" SG_ 2463978646 CHA_Ziel_FahrPr_SAK "No";
BA_ "GenSigSendType" SG_ 2463978646 CHA_Ziel_FahrPr_MO_StSt "OnChange";
BA_ "GenSigSwitchedByIgnition" SG_ 2463978646 CHA_Ziel_FahrPr_MO_StSt "No";
BA_ "GenSigSendType" SG_ 2463978646 CHA_Ziel_FahrPr_EBKV "OnChange";
BA_ "GenSigSwitchedByIgnition" SG_ 2463978646 CHA_Ziel_FahrPr_EBKV "No";
BA_ "GenSigSendType" SG_ 2463978646 CHA_Ziel_FahrPr_IL "OnChange";
BA_ "GenSigSwitchedByIgnition" SG_ 2463978646 CHA_Ziel_FahrPr_IL "No";
BA_ "GenSigSendType" SG_ 2463978646 CHA_Current_Mode "OnChange";
BA_ "GenSigSwitchedByIgnition" SG_ 2463978646 CHA_Current_Mode "No";
BA_ "GenSigSendType" SG_ 2463978646 CHA_Ziel_FahrPr_QS "OnChange";
BA_ "GenSigSwitchedByIgnition" SG_ 2463978646 CHA_Ziel_FahrPr_QS "No";
BA_ "GenSigSendType" SG_ 2463978646 CHA_Ziel_FahrPr_SCU "OnChange";
BA_ "GenSigSwitchedByIgnition" SG_ 2463978646 CHA_Ziel_FahrPr_SCU "No";
BA_ "GenSigSendType" SG_ 2463978646 CHA_Ziel_FahrPr_HAL "OnChange";
BA_ "GenSigSwitchedByIgnition" SG_ 2463978646 CHA_Ziel_FahrPr_HAL "No";
BA_ "GenSigSendType" SG_ 2463978646 CHA_Ziel_FahrPr_NR "OnChange";
BA_ "GenSigSwitchedByIgnition" SG_ 2463978646 CHA_Ziel_FahrPr_NR "No";
BA_ "GenSigSendType" SG_ 2463978646 CHA_Ziel_FahrPr_AV "OnChange";
BA_ "GenSigSwitchedByIgnition" SG_ 2463978646 CHA_Ziel_FahrPr_AV "No";
BA_ "GenSigSendType" SG_ 2463978646 CHA_Ziel_FahrPr_MXB "OnChange";
BA_ "GenSigSwitchedByIgnition" SG_ 2463978646 CHA_Ziel_FahrPr_MXB "No";
BA_ "GenSigSendType" SG_ 2463978646 CHA_Ziel_FahrPr_AFR "OnChange";
BA_ "GenSigSwitchedByIgnition" SG_ 2463978646 CHA_Ziel_FahrPr_AFR "No";
BA_ "GenSigSendType" SG_ 2463978646 CHA_Ziel_FahrPr_HDC "OnChange";
BA_ "GenSigSwitchedByIgnition" SG_ 2463978646 CHA_Ziel_FahrPr_HDC "No";
BA_ "GenSigSendType" SG_ 2463978646 CHA_Ziel_FahrPr_EAR "OnChange";
BA_ "GenSigSwitchedByIgnition" SG_ 2463978646 CHA_Ziel_FahrPr_EAR "No";
BA_ "GenSigSendType" SG_ 2463978646 CHA_Ziel_FahrPr_AEB "OnChange";
BA_ "GenSigSwitchedByIgnition" SG_ 2463978646 CHA_Ziel_FahrPr_AEB "No";
BA_ "GenSigSendType" SG_ 2463978646 CHA_Ziel_FahrPr_FCWO "OnChange";
BA_ "GenSigSwitchedByIgnition" SG_ 2463978646 CHA_Ziel_FahrPr_FCWO "No";
BA_ "GenSigSendType" SG_ 2463978646 CHA_Ziel_FahrPr_FCWP "OnChange";
BA_ "GenSigSwitchedByIgnition" SG_ 2463978646 CHA_Ziel_FahrPr_FCWP "No";
BA_ "GenSigSendType" SG_ 2463978646 CHA_Ziel_FahrPr_ToS_laengs "OnChange";
BA_ "GenSigSwitchedByIgnition" SG_ 2463978646 CHA_Ziel_FahrPr_ToS_laengs "No";
BA_ "GenSigSendType" SG_ 2463978646 CHA_Ziel_FahrPr_ToS_quer "OnChange";
BA_ "GenSigSwitchedByIgnition" SG_ 2463978646 CHA_Ziel_FahrPr_ToS_quer "No";
BA_ "GenSigSendType" SG_ 2463978646 CHA_Ziel_FahrPr_mFDR "OnChange";
BA_ "GenSigSwitchedByIgnition" SG_ 2463978646 CHA_Ziel_FahrPr_mFDR "No";
BA_ "GenSigSendType" SG_ 2463978646 CHA_Ziel_FahrPr_Reku_ZwGas "OnChange";
BA_ "GenSigSwitchedByIgnition" SG_ 2463978646 CHA_Ziel_FahrPr_Reku_ZwGas "No";
BA_ "GenSigSendType" SG_ 2463978646 CHA_Ziel_FahrPr_MO_Freilauf "OnChange";
BA_ "GenSigSwitchedByIgnition" SG_ 2463978646 CHA_Ziel_FahrPr_MO_Freilauf "No";
BA_ "GenSigSendType" SG_ 2463978646 CHA_Ziel_FahrPr_BMS "OnChange";
BA_ "GenSigSwitchedByIgnition" SG_ 2463978646 CHA_Ziel_FahrPr_BMS "No";
BA_ "GenSigSendType" SG_ 2463978646 CHA_Current_Mode_BMA "OnChange";
BA_ "GenSigSwitchedByIgnition" SG_ 2463978646 CHA_Current_Mode_BMA "No";
BA_ "GenSigSendType" SG_ 2463978646 CHA_Ziel_FahrPr_PDC "OnChange";
BA_ "GenSigSwitchedByIgnition" SG_ 2463978646 CHA_Ziel_FahrPr_PDC "No";
BA_ "GenSigSendType" SG_ 2463978646 CHA_Ziel_FahrPr_HHC "OnChange";
BA_ "GenSigSwitchedByIgnition" SG_ 2463978646 CHA_Ziel_FahrPr_HHC "No";
BA_ "GenSigSendType" SG_ 2463978646 CHA_Ziel_FahrPr_EDS "OnChange";
BA_ "GenSigSwitchedByIgnition" SG_ 2463978646 CHA_Ziel_FahrPr_EDS "No";
BA_ "GenSigSendType" SG_ 2463978646 CHA_Ziel_FahrPr_PACC "OnChange";
BA_ "GenSigSwitchedByIgnition" SG_ 2463978646 CHA_Ziel_FahrPr_PACC "No";
BA_ "GenSigSendType" SG_ 2463978646 CHA_Ziel_FahrPr_AGK "OnChange";
BA_ "GenSigSwitchedByIgnition" SG_ 2463978646 CHA_Ziel_FahrPr_AGK "No";
VAL_ 333 ACC_limitierte_Anfahrdyn 0 "keine_Limitierung" 1 "Limitierung_Anfahrdynamik_angefordert";
VAL_ 333 ACC_nachtr_Stopp_Anf 0 "nicht_angefordert" 1 "angefordert";
VAL_ 333 ACC_DynErhoehung 0 "normale_Verzoegerungsdynamik" 1 "erhoehte_Verzoegerungsdynamik";
VAL_ 333 ACC_Freilaufstrategie_TSK 0 "Freilaufstr_nicht_angefordert" 1 "Freilaufstr_angefordert";
VAL_ 333 ACC_StartStopp_Info 0 "Motorlauf_langfristig_nicht_notwendig_Stoppfreigabe" 1 "Motoranlauf_nicht_zwingend_notwendig_Stoppverbot_keine_Startanforderung" 2 "Motoranlauf_zwingend_notwendig_Startanforderung" 3 "Systemfehler";
VAL_ 333 ACC_Sollbeschleunigung_02 2046 "Neutralwert" 2047 "Fehler";
VAL_ 333 ACC_Anfahren 0 "keine_Anforderung_Anfahren" 1 "Anforderung_Anfahren";
VAL_ 333 ACC_Anhalten 0 "kein_Anhalten_gewuenscht" 1 "Anhalten_gewuenscht";
VAL_ 333 ACC_Typ 0 "Basis_ACC" 1 "ACC_mit_FollowToStop" 2 "ACC_mit_StopAndGo" 3 "ACC_nicht_codiert";
VAL_ 333 ACC_Status_ACC 0 "ACC_OFF_Hauptschalter_aus" 1 "ACC_INIT" 2 "ACC_STANDBY" 3 "ACC_AKTIV_regelt" 4 "ACC_OVERRIDE" 5 "ACC_Abschaltreaktion" 6 "reversibler_Fehler_im_ACC_System" 7 "irreversibler_Fehler_im_ACC_System";
VAL_ 333 ACC_Minimale_Bremsung 0 "Anforderung_Minimale_Bremsung_nicht_aktiv" 1 "Anforderung_Minimale_Bremsung_aktiv";
VAL_ 333 ACC_Anhalteweg 2046 "Neutralwert" 2047 "Fehler";
VAL_ 333 ACC_Boost 0 "Boost_nicht_aktiv" 1 "Boost_aktiv";
VAL_ 333 ACC_Freilauf_Anf 0 "keine Freilauf-Anforderung" 1 "Freilauf-Anforderung";
VAL_ 333 ACC_Anforderung_HMS 0 "keine_Anforderung" 1 "halten" 2 "parken" 3 "halten_Standby" 4 "anfahren" 5 "Loesen_ueber_Rampe";
VAL_ 333 ACC_Folgebeschl 254 "Neutralwert";
VAL_ 333 ACC_Freilauf_Info 0 "Freilauf_freigegeben" 1 "kein_Uebergang_in_Freilauf_zulaessig" 2 "Freilauf_nicht_freigegeben" 3 "Freilauf_Anforderung";
VAL_ 333 ACC_Tempolimitassistent_Ein 0 "Tempolimitassistent_aus" 1 "Tempolimitassistent_ein";
VAL_ 333 ACC_FoD_Status 0 "Init" 1 "Funktion_inaktiv" 2 "Funktion_aktiv";
VAL_ 333 vESC_Verz_Anf 8 "Neutralwert" 9 "Init" 10 "Fehler";
VAL_ 333 RDR_v_ueber_Grund 4091 "Init" 4092 "temporaer_nicht_verfuegbar" 4093 "Fehler";
VAL_ 333 RDR_v_ueber_Grund_Genauigkeit 61 "groesser_6km_h" 62 "Init" 63 "Fehler";
VAL_ 333 RDR_v_ueber_Grund_Fahrtrichtung 0 "vorwaerts" 1 "rueckwaerts" 2 "init_unbekannt";
VAL_ 2527679682 ACC_ASM_Ereignis 0 "No_Event" 255 "ASM_Trigger";
VAL_ 2527679682 ACC_ASM_Zeitstempel 255 "Init";
VAL_ 64 AB_RGS_Anst 4 "aktiv_Niveau_1" 5 "aktiv_Niveau_2" 6 "aktiv_Niveau_3" 7 "aktiv_Niveau_4" 8 "deaktiviert";
VAL_ 64 AB_Front_Crash 0 "kein_Front_Crash" 1 "Front_Crash";
VAL_ 64 AB_Heck_Crash 0 "kein_Heck_Crash" 1 "Heck_Crash";
VAL_ 64 AB_SF_Crash 0 "kein_Seiten_Crash_Fahrer" 1 "Seiten_Crash_Fahrer";
VAL_ 64 AB_SB_Crash 0 "kein_Seiten_Crash_Beifahrer" 1 "Seiten_Crash_Beifahrer";
VAL_ 64 AB_Rollover_Crash 0 "kein_Rollover" 1 "Rollover";
VAL_ 64 AB_Crash_Int 0 "kein_Crash" 1 "Crash_Intensitaet_1" 2 "Crash_Intensitaet_2_(nur_Stellgliedtest_MLB_B8)" 3 "Crash_Intensitaet_2_(nur_D4_C7_Colorado_NF_PAG__Crash_im_MLB_B8)" 4 "Crash_Intensitaet_3_(alt_VW/AUDI__Stellgliedtest_MLB_B8)" 5 "Crash_Intensitaet_3_(alt_PAG)" 7 "Crash_Intensitaet_3";
VAL_ 64 AB_Lampe 0 "Aus" 1 "Ein";
VAL_ 64 AB_Deaktiviert 0 "aktiv" 1 "deaktiviert";
VAL_ 64 AB_VB_deaktiviert 0 "Beifahrerairbag_aktiv" 1 "Beifahrerairbag_deaktiviert";
VAL_ 64 AB_Systemfehler 0 "kein_Fehler" 1 "Airbag_Systemfehler";
VAL_ 64 AB_Diagnose 0 "nicht_in_Diagnose" 1 "in_Diagnose";
VAL_ 64 AB_Stellgliedtest 0 "nicht_im_Stellgliedtest" 1 "Airbag_im_Stellgliedtest";
VAL_ 64 AB_Erh_Auf_VB 0 "keine_Anzeige" 1 "Beifahrerairbag_deaktiviert" 2 "Beifahrerairbag_aktiviert" 3 "nicht_definiert";
VAL_ 64 AB_Gurtwarn_VF 0 "keine_Warnung" 1 "Gurtwarnung_ausloesen";
VAL_ 64 AB_Gurtwarn_VB 0 "keine_Warnung" 1 "Gurtwarnung_ausloesen";
VAL_ 64 AB_Anzeige_Fussg 0 "keine_FSG_Aktion_ausgeloest" 1 "Motorhaube_offen" 2 "Systemfehler";
VAL_ 64 AB_Texte_AKS 0 "keine_AKS_Ausloesung" 1 "AKS_ausgeloest" 2 "AKS_Systemfehler";
VAL_ 64 AB_PAO_Leuchte_Anf 0 "Leuchte_ausschalten" 1 "Leuchte_einschalten";
VAL_ 64 AB_MKB_gueltig 0 "Multikollisionsbremsung_nicht_freigeschaltet" 1 "Multikollisionsbremsung_freigeschaltet";
VAL_ 64 AB_MKB_Anforderung 0 "Multikollisionsbremsung_nicht_angefordert" 1 "Multikollisionsbremsung_angefordert";
VAL_ 64 AB_Versorgungsspannung 0 "plausibel" 1 "unplausibel";
VAL_ 64 AB_Deaktivierung_HV 0 "keine_Deaktivierung" 1 "Deaktivierung_1" 2 "Deaktivierung_2" 3 "Deaktivierung_3" 4 "Deaktivierung_4" 5 "Deaktivierung_5" 6 "Deaktivierung_6" 7 "Fehler";
VAL_ 64 AB_EDR_Trigger 0 "No_Event" 1 "Start_Event" 2 "NonDeployment_Event" 3 "Deployment_Event";
VAL_ 64 AB_Belegung_VF 0 "nicht_verfuegbar" 1 "Fehler" 2 "nicht_belegt" 3 "belegt";
VAL_ 64 AB_Gurtschloss_FA_ext 0 "nicht_verbaut" 1 "reserviert" 2 "nicht_gesteckt" 3 "gesteckt" 4 "dauerhaft_nicht_gesteckt" 5 "dauerhaft_gesteckt" 6 "Init" 7 "Fehler";
VAL_ 64 AB_Belegung_VF_ext 0 "nicht_verbaut" 1 "reserviert" 2 "nicht_belegt" 3 "belegt" 4 "dauerhaft_nicht_belegt" 5 "dauerhaft_belegt" 6 "Init" 7 "Fehler";
VAL_ 64 ASM_Masterzeit 255 "Init";
VAL_ 1312 LoGeWa_Event_Kombiwarnung 0 "Init" 1 "Unfall" 2 "Traktionsverlust" 3 "Panne" 4 "Sichtbehinderung" 5 "Aquaplaning";
VAL_ 1312 AB_Anforderung_eCall 0 "keine_Anforderung" 1 "Anforderung";
VAL_ 1312 AB_Anprall_Seite_Beifahrer 0 "kein_Anprall" 1 "Anprall_erkannt";
VAL_ 1312 AB_Anprall_Rollover 0 "kein_Anprall" 1 "Anprall_erkannt";
VAL_ 1312 AB_Anprall_FGS 0 "kein_Anprall" 1 "Anprall_erkannt";
VAL_ 1312 AB_Anprall_Front_Beifahrer 0 "kein_Anprall" 1 "Anprall_erkannt";
VAL_ 1312 AB_Anprall_Front_Fahrer 0 "kein_Anprall" 1 "Anprall_erkannt";
VAL_ 1312 AB_Anprall_Heck_Beifahrer 0 "kein_Anprall" 1 "Anprall_erkannt";
VAL_ 1312 AB_Anprall_Heck_Fahrer 0 "kein_Anprall" 1 "Anprall_erkannt";
VAL_ 1312 AB_Wickelklappung_Reihe2_MI 0 "nicht_verbaut" 1 "nicht_verfuegbar__Fehler_oder_Init" 2 "nicht_verriegelt" 3 "verriegelt";
VAL_ 1312 AB_Belegung_VB 0 "nicht_verfuegbar" 1 "Fehler" 2 "nicht_belegt" 3 "belegt";
VAL_ 1312 AB_Abschaltanf_SIH_BF 0 "Normalbetrieb" 1 "Abschaltung_angefordert";
VAL_ 1312 AB_Anprall_Seite_Fahrer 0 "kein_Anprall" 1 "Anprall_erkannt";
VAL_ 1312 SC_PAO_Schriftzug_Anf 0 "LED aus" 1 "LED an" 2 "LED blinken" 3 "reserviert";
VAL_ 1312 SC_PAO_ON_Anf 0 "LED aus" 1 "LED an" 2 "LED blinken" 3 "reserviert";
VAL_ 1312 SC_PAO_OFF_Anf 0 "LED aus" 1 "LED an" 2 "LED blinken" 3 "reserviert";
VAL_ 1312 AB_Crashschwere 0 "kein_Ereignis" 1 "Crashschwere_1" 2 "Crashschwere_2" 3 "Crashschwere_3" 4 "Crashschwere_4" 5 "Crashschwere_5" 6 "Crashschwere_2_bis_5" 7 "Fehler";
VAL_ 1312 AB_Anforderung_USM 0 "keine_Anforderung" 1 "Anforderung";
VAL_ 1312 AB_Gurtschloss_FA 0 "nicht_verbaut" 1 "nicht_verfügbar (Fehler oder Init)" 2 "nicht_gesteckt" 3 "gesteckt";
VAL_ 1312 AB_Gurtschloss_BF 0 "nicht_verbaut" 1 "nicht_verfügbar (Fehler oder Init)" 2 "nicht_gesteckt" 3 "gesteckt";
VAL_ 1312 AB_Gurtschloss_Reihe2_FA 0 "nicht_verbaut" 1 "nicht_verfügbar (Fehler oder Init)" 2 "nicht_gesteckt" 3 "gesteckt";
VAL_ 1312 AB_Gurtschloss_Reihe2_MI 0 "nicht_verbaut" 1 "nicht_verfügbar (Fehler oder Init)" 2 "nicht_gesteckt" 3 "gesteckt";
VAL_ 1312 AB_Gurtschloss_Reihe2_BF 0 "nicht_verbaut" 1 "nicht_verfügbar (Fehler oder Init)" 2 "nicht_gesteckt" 3 "gesteckt";
VAL_ 1312 AB_Gurtschloss_Reihe3_FA 0 "nicht_verbaut" 1 "nicht_verfügbar (Fehler oder Init)" 2 "nicht_gesteckt" 3 "gesteckt";
VAL_ 1312 AB_Gurtschloss_Reihe3_MI 0 "nicht_verbaut" 1 "nicht_verfügbar (Fehler oder Init)" 2 "nicht_gesteckt" 3 "gesteckt";
VAL_ 1312 AB_Gurtschloss_Reihe3_BF 0 "nicht_verbaut" 1 "nicht_verfügbar (Fehler oder Init)" 2 "nicht_gesteckt" 3 "gesteckt";
VAL_ 1312 AB_Sitzpos_Sens_FA 0 "nicht verfügbar" 1 "Fehler" 2 "Sitz nicht vorne" 3 "Sitz vorne";
VAL_ 1312 AB_Sitzpos_Sens_BF 0 "nicht verfügbar" 1 "Fehler" 2 "Sitz nicht vorne" 3 "Sitz vorne";
VAL_ 1312 AB_Wickelklappung_Reihe2_BF 0 "nicht_verbaut" 1 "nicht_verfuegbar__Fehler_oder_Init" 2 "nicht_verriegelt" 3 "verriegelt";
VAL_ 1312 AB_Wickelklappung_Reihe2_FA 0 "nicht_verbaut" 1 "nicht_verfuegbar__Fehler_oder_Init" 2 "nicht_verriegelt" 3 "verriegelt";
VAL_ 65 AB_MKB_Safing 0 "Multikollisionsbremsung_nicht_bestaetigt" 1 "Multikollisionsbremsung_bestaetigt";
VAL_ 1349 AB_Gurtwarn_Reihe4_FA 0 "nicht_verbaut" 1 "keine_Gurtwarnung_Sitz_leer" 2 "keine_Gurtwarnung_Sitz_belegt" 3 "Gurtwarnung_Sitz_belegt";
VAL_ 1349 AB_Gurtwarn_Reihe4_BF 0 "nicht_verbaut" 1 "keine_Gurtwarnung_Sitz_leer" 2 "keine_Gurtwarnung_Sitz_belegt" 3 "Gurtwarnung_Sitz_belegt";
VAL_ 1349 AB_Gurtwarn_Reihe4_MI 0 "nicht_verbaut" 1 "keine_Gurtwarnung_Sitz_leer" 2 "keine_Gurtwarnung_Sitz_belegt" 3 "Gurtwarnung_Sitz_belegt";
VAL_ 1349 AB_Gurtwarn_Reihe2_FA 0 "nicht_verbaut" 1 "keine_Gurtwarnung_Sitz_leer" 2 "keine_Gurtwarnung_Sitz_belegt" 3 "Gurtwarnung_Sitz_belegt";
VAL_ 1349 AB_Gurtwarn_Reihe2_BF 0 "nicht_verbaut" 1 "keine_Gurtwarnung_Sitz_leer" 2 "keine_Gurtwarnung_Sitz_belegt" 3 "Gurtwarnung_Sitz_belegt";
VAL_ 1349 AbstWarn_MV_FAS_Fkt_Status 0 "Init" 1 "Funktion_Ist_Ein" 2 "Funktion_Ist_Aus" 3 "Fehler";
VAL_ 1349 WarnBrems_Charisma_Status 0 "Init" 1 "verfügbar" 2 "nicht verfügbar" 3 "asynchron durch Fahrerwunsch";
VAL_ 1349 WarnBrems_Charisma_FahrPr 0 "keine_Funktion" 1 "Programm_1" 2 "Programm_2" 3 "Programm_3" 4 "Programm_4" 5 "Programm_5" 6 "Programm_6" 7 "Programm_7" 8 "Programm_8" 9 "Programm_9" 10 "Programm_10" 11 "Programm_11" 12 "Programm_12" 13 "Programm_13" 14 "Programm_14" 15 "Programm_15";
VAL_ 1349 AB_Gurtwarn_Reihe2_MI 0 "nicht_verbaut" 1 "keine_Gurtwarnung_Sitz_leer" 2 "keine_Gurtwarnung_Sitz_belegt" 3 "Gurtwarnung_Sitz_belegt";
VAL_ 1349 AB_Gurtwarn_Reihe3_FA 0 "nicht_verbaut" 1 "keine_Gurtwarnung_Sitz_leer" 2 "keine_Gurtwarnung_Sitz_belegt" 3 "Gurtwarnung_Sitz_belegt";
VAL_ 1349 AB_Gurtwarn_Reihe3_MI 0 "nicht_verbaut" 1 "keine_Gurtwarnung_Sitz_leer" 2 "keine_Gurtwarnung_Sitz_belegt" 3 "Gurtwarnung_Sitz_belegt";
VAL_ 1349 AB_Gurtwarn_Reihe3_BF 0 "nicht_verbaut" 1 "keine_Gurtwarnung_Sitz_leer" 2 "keine_Gurtwarnung_Sitz_belegt" 3 "Gurtwarnung_Sitz_belegt";
VAL_ 1349 LGI_FAS_Fkt_Status 0 "Init" 1 "Funktion_Ist_Ein" 2 "Funktion_Ist_Aus" 3 "Fehler";
VAL_ 1349 PreCrash_FAS_Fkt_Status 0 "Init" 1 "Funktion_Ist_Ein" 2 "Funktion_Ist_Aus" 3 "Fehler";
VAL_ 1349 AB_SBR_hinten_verbau 0 "ohne_SBR_hinten" 1 "mit_SBR_hinten" 2 "nicht_definiert" 3 "Init";
VAL_ 1349 AWV_Einstellung_System_ASG 0 "deaktiviert" 1 "aktiviert";
VAL_ 1349 AWV_Einstellung_Warnung_ASG 0 "Aus" 1 "Setting_2" 2 "Setting_3" 3 "Setting_4" 4 "Setting_5" 5 "Ein";
VAL_ 1349 SC_PreSense_Modus_Warnung_NV 0 "Aus" 1 "Setting_2" 2 "Setting_3" 3 "Setting_4" 4 "Setting_5" 5 "Ein";
VAL_ 1349 SC_PreSense_Modus_Warnung_MV 0 "Aus" 1 "Setting_2" 2 "Setting_3" 3 "Setting_4" 4 "Setting_5" 5 "Ein";
VAL_ 1349 SC_PreSense_Modus_System_MV 0 "deaktiviert" 1 "aktiviert";
VAL_ 1349 SC_PreSense_Modus_System_NV 0 "deaktiviert" 1 "aktiviert";
VAL_ 1349 SC_PreSense_Modus_System_KAS 0 "deaktiviert" 1 "aktiviert";
VAL_ 2527679722 AB_Gurtschloss_Reihe4_FA 0 "nicht_verbaut" 1 "nicht_verfügbar (Fehler oder Init)" 2 "nicht_gesteckt" 3 "gesteckt";
VAL_ 2527679722 AB_Gurtschloss_Reihe4_BF 0 "nicht_verbaut" 1 "nicht_verfügbar (Fehler oder Init)" 2 "nicht_gesteckt" 3 "gesteckt";
VAL_ 2527679722 AB_Gurtschloss_Reihe4_MI 0 "nicht_verbaut" 1 "nicht_verfügbar (Fehler oder Init)" 2 "nicht_gesteckt" 3 "gesteckt";
VAL_ 1633 AAG_AVS_Fehler_02_inv 0 "Fehler" 1 "kein_Fehler";
VAL_ 1633 AAG_Bremsl_durch_ECD 0 "Bremslicht_ist_aus" 1 "Bremslicht_durch_ECD_aktiv";
VAL_ 1633 AAG_Anhaenger_abgesteckt 1 "Anhaenger_wurde_bei_KL15_aus_abgesteckt";
VAL_ 1633 AAG_NSL_aktiv 1 "Anhaenger_Nebelschusslicht_aktiv";
VAL_ 1633 AAG_Anhaenger_erkannt 0 "kein_Anhaenger_erkannt" 1 "AAG_Anhaenger_erkannt";
VAL_ 1633 AAG_Blinker_H_aktiv 1 "Anhaenger_Blinker_aktiv";
VAL_ 1633 AAG_Blinker_HL_def 1 "Anhaenger_Blinker_links_defekt";
VAL_ 1633 AAG_Blinker_HR_def 1 "Anhaenger_Blinker_rechts_defekt";
VAL_ 1633 AAG_Bremslicht_H_def 1 "Anhaenger_Bremslicht_defekt";
VAL_ 1633 AAG_Schlusslicht_HL_def 1 "Anhaenger_Schlusslicht_links_defekt";
VAL_ 1633 AAG_Schlusslicht_HR_def 1 "Anhaenger_Schlusslicht_rechts_defekt";
VAL_ 1633 AAG_Bremslicht_Reku 0 "inaktiv" 1 "aktiv";
VAL_ 1633 AAG_AVS_Fehler_02 0 "kein_Fehler" 1 "Fehler";
VAL_ 1633 AAG_LED_aktiv 0 "Lampen" 1 "LED";
VAL_ 1633 AAG_AVS_Stati 0 "endlage eingefahren erreicht" 1 "endlage ausgefahren erreicht" 2 "ausfahren automatik " 3 "einfahren automatik" 4 "ausfahren manuell " 5 "einfahren manuell" 6 "zwischenposition" 7 "nicht initialisiert";
VAL_ 345 ARA_Anf_Meldungen 128 "steeringAsAct_brakeByYourself" 0 "keine_Meldung" 129 "trailer_assist_is_finished" 1 "trailer_assist_temp_notAvailable" 130 "SteerIntervenDriverEmergBrakeAct" 2 "pressBrake_toReleaseParkingBrak" 131 "stabilityCtrl_emergencyBrake_act" 3 "trailDetNotFinishedMoveStraight" 132 "maxAngleExeeded_EmergBrakeAct" 4 "trailDetecNotFinishedReducedFctn" 133 "sysErrorEmergBrakeContactService" 5 "parkAsNotFuncRackOnTrailTowHitch" 134 "system_error_contact_service" 6 "aborted_trailNotDetec_emergBrake" 135 "aborted_trailNotDetec_emergBrake" 7 "aborted_trailer_is_not_detected" 136 "aborted_trailerNotDetecRsmeSteer" 8 "standstill_to_act_trailerAssist" 137 "system_error_braking_byYourself" 9 "duringAutomSteering_actNotAvail" 138 "trajectFwdSteerAsActBrakeYourslf" 10 "standstill_time_not_long_enough" 139 "SteeringAs_notAct_resumeSteering" 11 "press_PLA_BTN_toActTrailerAssist" 140 "trailerAs_aborted_resumeSteering" 12 "Temporary_not_available_ESP_off" 13 "traject_forward_path_suggestion" 14 "traject_backing_up_is_possible" 15 "traject_towing_fwd_canB_finished" 16 "trailerAsNotAvail_acivateMirrors" 17 "mirrors_are_closing" 18 "trailerAsNotAvailable_close_door" 19 "trailerAs_aborted_driverDoorOpen" 20 "trailerAsNotAvailable_closeTrunk" 21 "aborted_trunk_door_is_open" 22 "trailerAsNotAvail_cleanRearCam" 23 "aborted_clean_rear_camera" 24 "trailerAs_check_trailerConnector" 25 "trajectory_finished";
VAL_ 345 ARA_Knickwinkel_konfidenz 126 "Init" 127 "Fehler";
VAL_ 345 ARA_Texte 0 "kein Text/Akustik" 63 "Fehler";
VAL_ 345 ARA_Modus 0 "Knickwinkelmodus" 1 "Trajektorienmodus";
VAL_ 345 ARA_Aktiver_Grafikmodus 0 "keine_Grafik" 1 "Grafikmodus_aktiv";
VAL_ 345 ARA_Deaktivierung_sperren 0 "nicht_gesperrt" 1 "gesperrt";
VAL_ 345 ARA_Modus_Anf 0 "ARA Modus nicht im TSG angefordert" 1 "ARA Modus im TSG angefordert";
VAL_ 345 ARA_Bremsfuss 0 "kein Bremsfuss" 1 "Bremsfuss angefordert";
VAL_ 345 ARA_Sensor_Aktivierung 0 "Knickwinkelsensor deaktivieren" 1 "Knickwinkelsensor aktivieren";
VAL_ 345 ARA_Knickwinkel_Komfort 62 "Init" 63 "Fehler";
VAL_ 345 ARA_Status 8 "ARA_Status_betriebsbereit" 0 "ARA_Status_inaktiv" 9 "ARA_Status_Klemmtraeger_erkannt" 1 "ARA_Status_init" 2 "Fehler" 3 "ARA_Status_Start" 4 "ARA_Status_aktiv" 6 "ARA_Status_Regelung_aktiv" 10 "ARA_Status_Abbruch" 11 "ARA_Status_nicht_betriebsbereit";
VAL_ 345 ARA_Knickwinkel_Max 126 "Init" 127 "Fehler";
VAL_ 345 ARA_Knickwinkel_Soll 254 "Init" 255 "Fehler";
VAL_ 345 ARA_Knickwinkel_Ist 254 "Init" 255 "Fehler";
VAL_ 2589283607 AWC_Status_EoHVL 0 "Init" 1 "Keine_offene_HV_Leitung_erkannt" 2 "offene_HV_Leitung_erkannt" 3 "Fehler";
VAL_ 2589283607 AWC_Status_Spgfreiheit 0 "Init" 1 "HV_Komponente_spannungsfrei" 2 "HV_Komp_nicht_spannungsfrei" 3 "Fehler_nicht_spannungsfrei";
VAL_ 2589283607 AWC_IstSpannung 1022 "Init" 1023 "Fehler";
VAL_ 2589283607 AWC_Fehlerstatus 0 "Komponente_IO" 1 "Eingeschr_KompFkt_AWC_Lad_NIO" 2 "Eingeschr_KompFkt_reserve" 3 "Eingeschr_KompFkt_Interlock" 4 "Eingeschr_KompFkt_reserve" 5 "Eingeschr_KompFkt_reserve" 6 "Keine_Komponentenfunktion" 7 "Init";
VAL_ 2589283607 AWC_IstModus 0 "Standby_AWCLaden_inaktiv" 1 "AWCLaden_aktiv" 2 "AWCLaden_Verzoegerung" 3 "AWCLaden_Deaktiviert" 6 "Init" 7 "Ladefehler";
VAL_ 2589283607 AWC_IstStrom 510 "Init" 511 "Fehler";
VAL_ 2589283607 AWC_MaxLadLeistung 510 "Init" 511 "Fehler";
VAL_ 219 PCF_Freigabe 0 "keine_Freigabe_PreCrashFront" 1 "Freigabe_PreCrashFront";
VAL_ 219 SDF_PSF_Objektstatus 0 "kein_relevantes_Obj" 1 "relevantes_Obj_vorausfahrend" 2 "relevantes_Obj_stehend" 3 "relevantes_Obj_angehalten" 4 "relevantes_Obj_entgegenkommend" 5 "relevantes_Obj_querend" 7 "Fehler";
VAL_ 219 SDF_PSF_CU_Status 0 "Kollision_vermeidbar" 1 "Kollision_unvermeidbar";
VAL_ 219 SDF_PSF_CW 126 "Init" 127 "Fehler";
VAL_ 219 SDF_PSF_Fahrer_aktiv 0 "Fahrer_nicht_aktiv" 1 "Fahrer_aktiv";
VAL_ 219 SDF_PSF_Guete 0 "Modellguete_niO_keine_Plausi" 1 "Modellguete_niO_plausibilisiert" 2 "Modellguete_iO_keine_Plausi" 3 "Modellguete_iO_plausibilisiert";
VAL_ 219 SDF_PSF_Kollisionsueberdeckung 0 "Keine_Ueberdeckung" 29 "Ueberdeckung_groesser_Maximalwert" 30 "Init" 31 "Fehler";
VAL_ 219 SDF_PSF_Time_To_Collision 254 "Init" 255 "Fehler";
VAL_ 219 SDF_PSF_v_rel 0 "Objektstatus_0" 254 "Init" 255 "Fehler";
VAL_ 219 AWV_Eingriff_Sendeart 0 "langsamer_Zyklus" 1 "schneller_Zyklus";
VAL_ 219 AWV_Verz_Freigabe 0 "Verzoegerung_nicht_freigeben" 1 "Verzoegerung_freigeben";
VAL_ 219 AWV_Verz_Anf 1023 "keine_Anforderung";
VAL_ 219 AWV_Anf_Prefill 0 "Keine_Anforderung" 1 "Prefill_aktivieren";
VAL_ 219 AWV_Ruckprofil 0 "kein_Ruck" 1 "schwacher_Ruck" 2 "mittlerer_Ruck" 3 "starker_Ruck";
VAL_ 219 AWV_Time_to_collision 253 "Wert_groesser_max" 254 "Unbekannt" 255 "Init";
VAL_ 219 AWV_HBA_Param 0 "Defaultparametersatz" 1 "leicht_erhoeht" 2 "erhoeht" 3 "hoechst";
VAL_ 219 AWV_Verz_Anf_ASIL 0 "QM" 1 "A" 2 "B" 3 "C";
VAL_ 219 AWV_Time_to_brake 125 "Wert_groesser_max" 126 "unbekannt" 127 "Init";
VAL_ 219 AWV_Zielobjekttyp 0 "Unbekannt" 1 "Fussgaenger" 2 "Zweirad" 3 "PKW" 4 "LKW" 5 "reserviert" 6 "reserviert" 7 "reserviert" 8 "reserviert" 9 "reserviert" 10 "reserviert" 11 "reserviert" 12 "reserviert" 13 "reserviert" 14 "reserviert" 15 "init";
VAL_ 219 AWV_QFK_KruemmSoll_VZ 0 "positiv" 1 "negativ";
VAL_ 219 AWV_QFK_AnfStat 1 "Init" 2 "Bereit" 4 "Eingriff";
VAL_ 869 BEM_UBDM 0 "Init" 255 "Fehler";
VAL_ 869 NVEM_Ladefreigabe 0 "kein_Freigabe" 1 "Freigabe_Stufe_1" 2 "Freigabe_Stufe_2" 3 "Uneingeschraenkte_Freigabe";
VAL_ 869 NVEM_FMAus_Info 0 "Motorlauf_langfristig_nicht_notwendig_FMAus_Freigabe" 1 "Motoranlauf_nicht_zwingend_notwendig_Stoppverbot_keine_Startanforderung" 2 "Motoranlauf_zwingend_notwendig_Startanforderung" 3 "Systemfehler";
VAL_ 869 NVEM_PTC_Sollstufe 0 "Aus" 1 "Stufe_1" 2 "Stufe_2" 3 "Stufe_3";
VAL_ 869 NVEM_P_Generator_Status 0 "gefiltert" 1 "ungefiltert";
VAL_ 869 BEM_P_Generator 255 "Fehler";
VAL_ 869 BEM_n_LLA 0 "keine_Erhoehung" 1 "Stufe_1" 2 "Stufe_2" 3 "Stufe_3";
VAL_ 869 BEM_01_Abschaltstufen 0 "Stufe_0_keine_Einschraenkung" 1 "Stufe_1" 2 "Stufe_2" 3 "Stufe_3" 4 "Transportmodus" 7 "Ruhestrommessmodus";
VAL_ 869 BEM_Anf_KL 0 "keine Anforderung" 1 "Anforderung Kühlerlüfter Ansteuerung";
VAL_ 869 BEM_StartStopp_Info 0 "Motorlauf_nicht_notwendig_(Stoppfreigabe)" 1 "Motoranlauf_nicht_zwingend_notwendig_(Stoppverbot,keine_Startanforderung)" 2 "Motoranlauf_zwingend_notwendig_(Startanforderung)" 3 "Systemfehler";
VAL_ 869 BEM_EMLIN_ungueltig 0 "Signale_gueltig" 1 "Signale_ungueltig";
VAL_ 869 BEM_Batt_Ab 0 "verbunden" 1 "nicht_verbunden";
VAL_ 869 NVEM_FMAus_I_Verbrauch 30 "Init" 31 "Fehler";
VAL_ 869 NVEM_Freilauf_Info 0 "Freilauf_freigegeben" 1 "Weiches_Veto_uebertippbar" 2 "Hartes_Veto_Abbruch" 3 "Freilauf_Anforderung";
VAL_ 869 BEM_NV_NachladAnf 0 "keine_Anforderung" 1 "Anforderung_NV_Nachladung" 2 "Wunsch_NV_Nachladung" 3 "Fehler";
VAL_ 869 BEM_Segel_Info 0 "keine_Anforderung" 1 "Mindestdrehzahl_1" 2 "Mindestdrehzahl_2" 3 "Segelveto";
VAL_ 869 BEM_HYB_DC_uMinLV 254 "Init" 255 "Fehler";
VAL_ 1442 BMS_Fehler_Pilot 0 "geschlossen" 1 "Unterbrechung";
VAL_ 1442 BMS_Status_ServiceDisconnect 0 "gesteckt" 1 "gezogen";
VAL_ 1442 BMS_Status_Spgfreiheit 0 "Init" 1 "HV_Komponente_spannungsfrei" 2 "HV_Komp_nicht_spannungsfrei" 3 "Fehler_nicht_spannungsfrei";
VAL_ 1442 BMS_OBD_Lampe_Anf 0 "kein_MIL_Request" 1 "MIL_Request";
VAL_ 1442 BMS_Fehlerstatus 0 "Komponente_IO" 1 "Eingeschr_KompFkt_Isofehler_I" 2 "Eingeschr_KompFkt_Isofehler_II" 3 "Eingeschr_KompFkt_Interlock" 4 "Eingeschr_KompFkt_SD" 5 "Eingeschr_KompFkt_Leistungsred" 6 "Keine_Komponentenfunktion" 7 "Init";
VAL_ 1442 BMS_Kapazitaet_02 2047 "Init";
VAL_ 1442 BMS_Fehlerlampe_Anf 1 "RedLED_Request";
VAL_ 1442 BMS_Warnlampe_Anf 1 "YellowLED_Request";
VAL_ 1442 BMS_Kl30c_Status 0 "Init" 1 "geschlossen" 2 "offen" 3 "Fehler";
VAL_ 2527679654 BMS_IsoZustand 0 "Init" 1 "groesser_Schwelle_1" 2 "kleiner_Schwelle_1_gesamt" 3 "kleiner_Schwelle_1_intern" 4 "kleiner_Schwelle_2_gesamt" 5 "kleiner_Schwelle_2_intern" 6 "kein_Messwert" 7 "Messung_aktiv";
VAL_ 2527679654 BMS_IsoFehler 0 "Init" 1 "kein_IsoFehler" 2 "IsoFehler_Schwelle_1" 3 "IsoFehler_Schwelle_2" 4 "IWU_defekt" 5 "reserviert" 6 "reserviert" 7 "reserviert";
VAL_ 2527679654 BMS_IstTemperatur_hoechste 253 "reserviert" 254 "Init" 255 "Fehler";
VAL_ 2527679654 BMS_IstTemperatur_niedrigste 253 "reserviert" 254 "Init" 255 "Fehler";
VAL_ 2527679654 BMS_IstZellspannung_hoechste 4092 "reserviert" 4093 "reserviert" 4094 "Init" 4095 "Fehler";
VAL_ 2527679654 BMS_IstZellspannung_niedrigste 4092 "reserviert" 4093 "reserviert" 4094 "Init" 4095 "Fehler";
VAL_ 207 BMS_Fehlerstatus_HV_Schuetze 0 "Init_kein_Diagnoseergebnis" 1 "kein_Schuetz_verschweisst" 2 "mind_1_Schuetz_verschweisst" 3 "Fehler_Schuetzstatuserkennung";
VAL_ 207 BMS_ErwGrenzen_aktiv 0 "Init" 1 "extended_Range";
VAL_ 207 BMS_IstModus 0 "HV_inaktiv" 1 "Fahren_HV_aktiv" 2 "stBalancing" 3 "externes_Laden" 4 "AC_Laden" 5 "Error_Batt" 6 "DC_Laden" 7 "Init";
VAL_ 207 BMS_HVIL_Status 0 "Init" 1 "geschlossen" 2 "offen" 3 "Fehler";
VAL_ 207 BMS_Fehler_HVBattAbschaltung 1 "Err_ShutOff";
VAL_ 207 BMS_Fehler_HVBattAbschaltung_Anf 1 "Err_ShutOffRequest";
VAL_ 207 BMS_Fehler_Leistungsred 0 "keine_Leistungseinschraenkung" 1 "Leistungseinschraenkung";
VAL_ 207 BMS_Strom 32765 "nicht_messbar" 32766 "Init" 32767 "Fehler";
VAL_ 207 BMS_Fehler_Notabschaltung_Crash 1 "Err_EmergcyShtOffCrash";
VAL_ 207 BMS_Spannung_Zwischenkreis 4093 "nicht_messbar" 4094 "Init" 4095 "Fehler";
VAL_ 207 BMS_Spannung 4093 "nicht_messbar" 4094 "Init" 4095 "Fehler";
VAL_ 2463978704 BMS_Max_Entladestrom 8190 "Init";
VAL_ 2463978704 BMS_Max_Ladestrom 8190 "Init";
VAL_ 2463978704 BMS_Max_Entladeleistung 8190 "Init";
VAL_ 2463978704 BMS_Max_Ladeleistung 8190 "Init";
VAL_ 2463978705 BMS_Status_EoHVL_Heizer 0 "Init" 1 "Keine_offene_HV_Leitung_erkannt" 2 "offene_HV_Leitung_erkannt" 3 "Fehler";
VAL_ 2463978705 BMS_Ladezustand 2046 "Init" 2047 "Fehler";
VAL_ 2463978705 BMS_PerfInd_Entladen 1022 "Init";
VAL_ 2463978705 BMS_PerfInd_Laden 1022 "Init";
VAL_ 2463978705 BMS_Nutzbare_EntladeEnergie 65534 "Init" 65535 "Fehler";
VAL_ 2589283664 BMS_Balancing_Aktiv 0 "Init" 1 "aktiv" 2 "nicht_aktiv";
VAL_ 2589283664 BMS_Ladevorgang_aktiv 0 "inaktiv" 1 "aktiv";
VAL_ 2589283664 BMS_RIso_Ext 4094 "Init" 4095 "Fehler";
VAL_ 2589283664 BMS_Min_Ladezustand 2046 "Init";
VAL_ 2589283664 BMS_Max_Energie 8190 "Init";
VAL_ 2589283664 BMS_Max_Ladezustand 2046 "Init";
VAL_ 2589283665 BMS_BattHeizung_VerbautStatus 0 "nicht_verbaut" 1 "verbaut";
VAL_ 2589283665 BMS_Fehler_NTKreis 0 "kein_Fehler" 1 "Fehler";
VAL_ 2589283665 BMS_Temperierung_Anf 0 "hoher_Kuehlbedarf" 1 "mittlerer_Kuehlbedarf" 2 "niedriger_Kuehlbedarf" 3 "kein_Temperierungsbedarf_Init" 4 "niedriger_Heizbedarf" 5 "mittlerer_Heizbedarf" 6 "hoher_Heizbedarf" 7 "Umwaelzungsbedarf";
VAL_ 2589283665 BMS_Status_Ventil1 0 "Ventil_nicht_angesteuert" 1 "Ventil_angesteuert" 2 "reserviert" 3 "reserviert" 4 "reserviert" 5 "Ventil_nicht_verbaut" 6 "Init" 7 "Fehler";
VAL_ 2589283665 BMS_Status_Ventil2 0 "Ventil_nicht_angesteuert" 1 "Ventil_angesteuert" 2 "reserviert" 3 "reserviert" 4 "reserviert" 5 "Ventil_nicht_verbaut" 6 "Init" 7 "Fehler";
VAL_ 2589283665 BMS_Pumpe1_Ansteuerung 13 "nicht_verbaut" 14 "Init" 15 "Fehler";
VAL_ 2589283665 BMS_Pumpe2_Ansteuerung 13 "nicht_verbaut" 14 "Init" 15 "Fehler";
VAL_ 2589283665 BMS_VorlaufTemperatur 253 "nicht_verbaut" 254 "Init" 255 "Fehler";
VAL_ 2589283665 BMS_Temperatur 254 "Init" 255 "Fehler";
VAL_ 2589283665 BMS_SollVorlauftemperatur 254 "Init" 255 "Fehler";
VAL_ 2589283665 BMS_RuecklaufTemperatur 253 "nicht_verbaut" 254 "Init" 255 "Fehler";
VAL_ 2589283760 BMS_Max_Spannung 1022 "Init";
VAL_ 2589283760 BMS_Min_Spannung 1022 "Init";
VAL_ 2589283760 BMS_Dauer_Entladeleistung 4094 "Init";
VAL_ 2589283760 BMS_Dauer_Ladeleistung 4094 "Init";
VAL_ 2463978646 CHA_Ziel_FahrPr_AGA 0 "keine_Funktion" 1 "Programm_1" 2 "Programm_2" 3 "Programm_3" 4 "Programm_4" 5 "Programm_5" 6 "Programm_6" 7 "Programm_7" 8 "Programm_8" 9 "Programm_9" 10 "Programm_10" 11 "Programm_11" 12 "Programm_12" 13 "Programm_13" 14 "Programm_14" 15 "Programm_15";
VAL_ 2463978646 CHA_Ziel_FahrPr_ESP 0 "keine_Funktion" 1 "Programm_1" 2 "Programm_2" 3 "Programm_3" 4 "Programm_4" 5 "Programm_5" 6 "Programm_6" 7 "Programm_7" 8 "Programm_8" 9 "Programm_9" 10 "Programm_10" 11 "Programm_11" 12 "Programm_12" 13 "Programm_13" 14 "Programm_14" 15 "Programm_15";
VAL_ 2463978646 CHA_Ziel_FahrPr_Freilauf 0 "keine_Funktion" 1 "Programm_1" 2 "Programm_2" 3 "Programm_3" 4 "Programm_4" 5 "Programm_5" 6 "Programm_6" 7 "Programm_7" 8 "Programm_8" 9 "Programm_9" 10 "Programm_10" 11 "Programm_11" 12 "Programm_12" 13 "Programm_13" 14 "Programm_14" 15 "Programm_15";
VAL_ 2463978646 CHA_Fahrer_Umschaltung 0 "keine_oder_automatische_Umschaltung" 1 "manuelle_Umschaltung";
VAL_ 2463978646 CHA_Fahrer_Umschaltung_BMA 0 "keine_oder_autom_Umschaltung" 1 "manuelle_Umschaltung";
VAL_ 2463978646 CHA_Ziel_FahrPr_MO 0 "keine_Funktion" 1 "Programm_1" 2 "Programm_2" 3 "Programm_3" 4 "Programm_4" 5 "Programm_5" 6 "Programm_6" 7 "Programm_7" 8 "Programm_8" 9 "Programm_9" 10 "Programm_10" 11 "Programm_11" 12 "Programm_12" 13 "Programm_13" 14 "Programm_14" 15 "Programm_15";
VAL_ 2463978646 CHA_Ziel_FahrPr_GE 0 "keine_Funktion" 1 "Programm_1" 2 "Programm_2" 3 "Programm_3" 4 "Programm_4" 5 "Programm_5" 6 "Programm_6" 7 "Programm_7" 8 "Programm_8" 9 "Programm_9" 10 "Programm_10" 11 "Programm_11" 12 "Programm_12" 13 "Programm_13" 14 "Programm_14" 15 "Programm_15";
VAL_ 2463978646 CHA_Ziel_FahrPr_ALR 0 "keine_Funktion" 1 "Programm_1" 2 "Programm_2" 3 "Programm_3" 4 "Programm_4" 5 "Programm_5" 6 "Programm_6" 7 "Programm_7" 8 "Programm_8" 9 "Programm_9" 10 "Programm_10" 11 "Programm_11" 12 "Programm_12" 13 "Programm_13" 14 "Programm_14" 15 "Programm_15";
VAL_ 2463978646 CHA_Ziel_FahrPr_MO_BZS 0 "keine_Funktion" 1 "Programm_1" 2 "Programm_2" 3 "Programm_3" 4 "Programm_4" 5 "Programm_5" 6 "Programm_6" 7 "Programm_7" 8 "Programm_8" 9 "Programm_9" 10 "Programm_10" 11 "Programm_11" 12 "Programm_12" 13 "Programm_13" 14 "Programm_14" 15 "Programm_15";
VAL_ 2463978646 CHA_Ziel_FahrPr_DR 0 "keine_Funktion" 1 "Programm_1" 2 "Programm_2" 3 "Programm_3" 4 "Programm_4" 5 "Programm_5" 6 "Programm_6" 7 "Programm_7" 8 "Programm_8" 9 "Programm_9" 10 "Programm_10" 11 "Programm_11" 12 "Programm_12" 13 "Programm_13" 14 "Programm_14" 15 "Programm_15";
VAL_ 2463978646 CHA_Ziel_FahrPr_VAQ 0 "keine_Funktion" 1 "Programm_1" 2 "Programm_2" 3 "Programm_3" 4 "Programm_4" 5 "Programm_5" 6 "Programm_6" 7 "Programm_7" 8 "Programm_8" 9 "Programm_9" 10 "Programm_10" 11 "Programm_11" 12 "Programm_12" 13 "Programm_13" 14 "Programm_14" 15 "Programm_15";
VAL_ 2463978646 CHA_Ziel_FahrPr_AFS 0 "keine_Funktion" 1 "Programm_1" 2 "Programm_2" 3 "Programm_3" 4 "Programm_4" 5 "Programm_5" 6 "Programm_6" 7 "Programm_7" 8 "Programm_8" 9 "Programm_9" 10 "Programm_10" 11 "Programm_11" 12 "Programm_12" 13 "Programm_13" 14 "Programm_14" 15 "Programm_15";
VAL_ 2463978646 CHA_Ziel_FahrPr_PreCrash 0 "keine_Funktion" 1 "Programm_1" 2 "Programm_2" 3 "Programm_3" 4 "Programm_4" 5 "Programm_5" 6 "Programm_6" 7 "Programm_7" 8 "Programm_8" 9 "Programm_9" 10 "Programm_10" 11 "Programm_11" 12 "Programm_12" 13 "Programm_13" 14 "Programm_14" 15 "Programm_15";
VAL_ 2463978646 CHA_Ziel_FahrPr_EPS 0 "keine_Funktion" 1 "Programm_1" 2 "Programm_2" 3 "Programm_3" 4 "Programm_4" 5 "Programm_5" 6 "Programm_6" 7 "Programm_7" 8 "Programm_8" 9 "Programm_9" 10 "Programm_10" 11 "Programm_11" 12 "Programm_12" 13 "Programm_13" 14 "Programm_14" 15 "Programm_15";
VAL_ 2463978646 CHA_Ziel_FahrPr_ACC 0 "keine_Funktion" 1 "Programm_1" 2 "Programm_2" 3 "Programm_3" 4 "Programm_4" 5 "Programm_5" 6 "Programm_6" 7 "Programm_7" 8 "Programm_8" 9 "Programm_9" 10 "Programm_10" 11 "Programm_11" 12 "Programm_12" 13 "Programm_13" 14 "Programm_14" 15 "Programm_15";
VAL_ 2463978646 CHA_Ziel_FahrPr_SAK 0 "keine_Funktion" 1 "Programm_1" 2 "Programm_2" 3 "Programm_3" 4 "Programm_4" 5 "Programm_5" 6 "Programm_6" 7 "Programm_7" 8 "Programm_8" 9 "Programm_9" 10 "Programm_10" 11 "Programm_11" 12 "Programm_12" 13 "Programm_13" 14 "Programm_14" 15 "Programm_15";
VAL_ 2463978646 CHA_Ziel_FahrPr_MO_StSt 0 "keine_Funktion" 1 "Programm_1" 2 "Programm_2" 3 "Programm_3" 4 "Programm_4" 5 "Programm_5" 6 "Programm_6" 7 "Programm_7" 8 "Programm_8" 9 "Programm_9" 10 "Programm_10" 11 "Programm_11" 12 "Programm_12" 13 "Programm_13" 14 "Programm_14" 15 "Programm_15";
VAL_ 2463978646 CHA_Ziel_FahrPr_EBKV 0 "keine_Funktion" 1 "Programm_1" 2 "Programm_2" 3 "Programm_3" 4 "Programm_4" 5 "Programm_5" 6 "Programm_6" 7 "Programm_7" 8 "Programm_8" 9 "Programm_9" 10 "Programm_10" 11 "Programm_11" 12 "Programm_12" 13 "Programm_13" 14 "Programm_14" 15 "Programm_15";
VAL_ 2463978646 CHA_Ziel_FahrPr_IL 0 "keine_Funktion" 1 "Programm_1" 2 "Programm_2" 3 "Programm_3" 4 "Programm_4" 5 "Programm_5" 6 "Programm_6" 7 "Programm_7" 8 "Programm_8" 9 "Programm_9" 10 "Programm_10" 11 "Programm_11" 12 "Programm_12" 13 "Programm_13" 14 "Programm_14" 15 "Programm_15";
VAL_ 2463978646 CHA_Current_Mode 0 "keine_Funktion" 1 "Programm_1" 2 "Programm_2" 3 "Programm_3" 4 "Programm_4" 5 "Programm_5" 6 "Programm_6" 7 "Programm_7" 8 "Programm_8" 9 "Programm_9" 10 "Programm_10" 11 "Programm_11" 12 "Programm_12" 13 "Programm_13" 14 "Programm_14" 15 "Programm_15";
VAL_ 2463978646 CHA_Ziel_FahrPr_QS 0 "keine_Funktion" 1 "Programm_1" 2 "Programm_2" 3 "Programm_3" 4 "Programm_4" 5 "Programm_5" 6 "Programm_6" 7 "Programm_7" 8 "Programm_8" 9 "Programm_9" 10 "Programm_10" 11 "Programm_11" 12 "Programm_12" 13 "Programm_13" 14 "Programm_14" 15 "Programm_15";
VAL_ 2463978646 CHA_Ziel_FahrPr_SCU 0 "keine_Funktion" 1 "Programm_1" 2 "Programm_2" 3 "Programm_3" 4 "Programm_4" 5 "Programm_5" 6 "Programm_6" 7 "Programm_7" 8 "Programm_8" 9 "Programm_9" 10 "Programm_10" 11 "Programm_11" 12 "Programm_12" 13 "Programm_13" 14 "Programm_14" 15 "Programm_15";
VAL_ 2463978646 CHA_Ziel_FahrPr_HAL 0 "keine_Funktion" 1 "Programm_1" 2 "Programm_2" 3 "Programm_3" 4 "Programm_4" 5 "Programm_5" 6 "Programm_6" 7 "Programm_7" 8 "Programm_8" 9 "Programm_9" 10 "Programm_10" 11 "Programm_11" 12 "Programm_12" 13 "Programm_13" 14 "Programm_14" 15 "Programm_15";
VAL_ 2463978646 CHA_Ziel_FahrPr_NR 0 "keine_Funktion" 1 "Programm_1" 2 "Programm_2" 3 "Programm_3" 4 "Programm_4" 5 "Programm_5" 6 "Programm_6" 7 "Programm_7" 8 "Programm_8" 9 "Programm_9" 10 "Programm_10" 11 "Programm_11" 12 "Programm_12" 13 "Programm_13" 14 "Programm_14" 15 "Programm_15";
VAL_ 2463978646 CHA_Ziel_FahrPr_AV 0 "keine_Funktion" 1 "Programm_1" 2 "Programm_2" 3 "Programm_3" 4 "Programm_4" 5 "Programm_5" 6 "Programm_6" 7 "Programm_7" 8 "Programm_8" 9 "Programm_9" 10 "Programm_10" 11 "Programm_11" 12 "Programm_12" 13 "Programm_13" 14 "Programm_14" 15 "Programm_15";
VAL_ 2463978646 CHA_Ziel_FahrPr_MXB 0 "keine_Funktion" 1 "Programm_1" 2 "Programm_2" 3 "Programm_3" 4 "Programm_4" 5 "Programm_5" 6 "Programm_6" 7 "Programm_7" 8 "Programm_8" 9 "Programm_9" 10 "Programm_10" 11 "Programm_11" 12 "Programm_12" 13 "Programm_13" 14 "Programm_14" 15 "Programm_15";
VAL_ 2463978646 CHA_Ziel_FahrPr_AFR 0 "keine_Funktion" 1 "Programm_1" 2 "Programm_2" 3 "Programm_3" 4 "Programm_4" 5 "Programm_5" 6 "Programm_6" 7 "Programm_7" 8 "Programm_8" 9 "Programm_9" 10 "Programm_10" 11 "Programm_11" 12 "Programm_12" 13 "Programm_13" 14 "Programm_14" 15 "Programm_15";
VAL_ 2463978646 CHA_Ziel_FahrPr_HDC 0 "keine_Funktion" 1 "Programm_1" 2 "Programm_2" 3 "Programm_3" 4 "Programm_4" 5 "Programm_5" 6 "Programm_6" 7 "Programm_7" 8 "Programm_8" 9 "Programm_9" 10 "Programm_10" 11 "Programm_11" 12 "Programm_12" 13 "Programm_13" 14 "Programm_14" 15 "Programm_15";
VAL_ 2463978646 CHA_Ziel_FahrPr_EAR 0 "keine_Funktion" 1 "Programm_1" 2 "Programm_2" 3 "Programm_3" 4 "Programm_4" 5 "Programm_5" 6 "Programm_6" 7 "Programm_7" 8 "Programm_8" 9 "Programm_9" 10 "Programm_10" 11 "Programm_11" 12 "Programm_12" 13 "Programm_13" 14 "Programm_14" 15 "Programm_15";
VAL_ 2463978646 CHA_Ziel_FahrPr_AEB 0 "keine_Funktion" 1 "Programm_1" 2 "Programm_2" 3 "Programm_3" 4 "Programm_4" 5 "Programm_5" 6 "Programm_6" 7 "Programm_7" 8 "Programm_8" 9 "Programm_9" 10 "Programm_10" 11 "Programm_11" 12 "Programm_12" 13 "Programm_13" 14 "Programm_14" 15 "Programm_15";
VAL_ 2463978646 CHA_Ziel_FahrPr_FCWO 0 "keine_Funktion" 1 "Programm_1" 2 "Programm_2" 3 "Programm_3" 4 "Programm_4" 5 "Programm_5" 6 "Programm_6" 7 "Programm_7" 8 "Programm_8" 9 "Programm_9" 10 "Programm_10" 11 "Programm_11" 12 "Programm_12" 13 "Programm_13" 14 "Programm_14" 15 "Programm_15";
VAL_ 2463978646 CHA_Ziel_FahrPr_FCWP 0 "keine_Funktion" 1 "Programm_1" 2 "Programm_2" 3 "Programm_3" 4 "Programm_4" 5 "Programm_5" 6 "Programm_6" 7 "Programm_7" 8 "Programm_8" 9 "Programm_9" 10 "Programm_10" 11 "Programm_11" 12 "Programm_12" 13 "Programm_13" 14 "Programm_14" 15 "Programm_15";
VAL_ 2463978646 CHA_Ziel_FahrPr_ToS_laengs 0 "keine_Funktion" 1 "Programm_1" 2 "Programm_2" 3 "Programm_3" 4 "Programm_4" 5 "Programm_5" 6 "Programm_6" 7 "Programm_7" 8 "Programm_8" 9 "Programm_9" 10 "Programm_10" 11 "Programm_11" 12 "Programm_12" 13 "Programm_13" 14 "Programm_14" 15 "Programm_15";
VAL_ 2463978646 CHA_Ziel_FahrPr_ToS_quer 0 "keine_Funktion" 1 "Programm_1" 2 "Programm_2" 3 "Programm_3" 4 "Programm_4" 5 "Programm_5" 6 "Programm_6" 7 "Programm_7" 8 "Programm_8" 9 "Programm_9" 10 "Programm_10" 11 "Programm_11" 12 "Programm_12" 13 "Programm_13" 14 "Programm_14" 15 "Programm_15";
VAL_ 2463978646 CHA_Ziel_FahrPr_mFDR 0 "keine_Funktion" 1 "Programm_1" 2 "Programm_2" 3 "Programm_3" 4 "Programm_4" 5 "Programm_5" 6 "Programm_6" 7 "Programm_7" 8 "Programm_8" 9 "Programm_9" 10 "Programm_10" 11 "Programm_11" 12 "Programm_12" 13 "Programm_13" 14 "Programm_14" 15 "Programm_15";
VAL_ 2463978646 CHA_Ziel_FahrPr_Reku_ZwGas 0 "kein_Funktion" 1 "Programm_1" 2 "Programm_2" 3 "Programm_3" 4 "Programm_4" 5 "Programm_5" 6 "Programm_6" 7 "Programm_7" 8 "Programm_8" 9 "Programm_9" 10 "Programm_10" 11 "Programm_11" 12 "Programm_12" 13 "Programm_13" 14 "Programm_14" 15 "Programm_15";
VAL_ 2463978646 CHA_Ziel_FahrPr_MO_Freilauf 0 "keine_Funktion" 1 "Programm_1" 2 "Programm_2" 3 "Programm_3" 4 "Programm_4" 5 "Programm_5" 6 "Programm_6" 7 "Programm_7" 8 "Programm_8" 9 "Programm_9" 10 "Programm_10" 11 "Programm_11" 12 "Programm_12" 13 "Programm_13" 14 "Programm_14" 15 "Programm_15";
VAL_ 2463978646 CHA_Ziel_FahrPr_BMS 0 "keine_Funktion" 1 "Programm_1" 2 "Programm_2" 3 "Programm_3" 4 "Programm_4" 5 "Programm_5" 6 "Programm_6" 7 "Programm_7" 8 "Programm_8" 9 "Programm_9" 10 "Programm_10" 11 "Programm_11" 12 "Programm_12" 13 "Programm_13" 14 "Programm_14" 15 "Programm_15";
VAL_ 2463978646 CHA_Current_Mode_BMA 0 "keine_Funktion" 1 "Programm_1" 2 "Programm_2" 3 "Programm_3" 4 "Programm_4" 5 "Programm_5" 6 "Programm_6" 7 "Programm_7" 8 "Programm_8" 9 "Programm_9" 10 "Programm_10" 11 "Programm_11" 12 "Programm_12" 13 "Programm_13" 14 "Programm_14" 15 "Programm_15";
VAL_ 2463978646 CHA_Ziel_FahrPr_PDC 0 "keine_Funktion" 1 "Programm_1" 2 "Programm_2" 3 "Programm_3" 4 "Programm_4" 5 "Programm_5" 6 "Programm_6" 7 "Programm_7" 8 "Programm_8" 9 "Programm_9" 10 "Programm_10" 11 "Programm_11" 12 "Programm_12" 13 "Programm_13" 14 "Programm_14" 15 "Programm_15";
VAL_ 2463978646 CHA_Ziel_FahrPr_HHC 0 "keine_Funktion" 1 "Programm_1" 2 "Programm_2" 3 "Programm_3" 4 "Programm_4" 5 "Programm_5" 6 "Programm_6" 7 "Programm_7" 8 "Programm_8" 9 "Programm_9" 10 "Programm_10" 11 "Programm_11" 12 "Programm_12" 13 "Programm_13" 14 "Programm_14" 15 "Programm_15";
VAL_ 2463978646 CHA_Ziel_FahrPr_EDS 0 "keine_Funktion" 1 "Programm_1" 2 "Programm_2" 3 "Programm_3" 4 "Programm_4" 5 "Programm_5" 6 "Programm_6" 7 "Programm_7" 8 "Programm_8" 9 "Programm_9" 10 "Programm_10" 11 "Programm_11" 12 "Programm_12" 13 "Programm_13" 14 "Programm_14" 15 "Programm_15";
VAL_ 2463978646 CHA_Ziel_FahrPr_PACC 0 "keine_Funktion" 1 "Programm_1" 2 "Programm_2" 3 "Programm_3" 4 "Programm_4" 5 "Programm_5" 6 "Programm_6" 7 "Programm_7" 8 "Programm_8" 9 "Programm_9" 10 "Programm_10" 11 "Programm_11" 12 "Programm_12" 13 "Programm_13" 14 "Programm_14" 15 "Programm_15";
VAL_ 2463978646 CHA_Ziel_FahrPr_AGK 0 "keine_Funktion" 1 "Programm_1" 2 "Programm_2" 3 "Programm_3" 4 "Programm_4" 5 "Programm_5" 6 "Programm_6" 7 "Programm_7" 8 "Programm_8" 9 "Programm_9" 10 "Programm_10" 11 "Programm_11" 12 "Programm_12" 13 "Programm_13" 14 "Programm_14" 15 "Programm_15";
